VERSION ""

NS_ :

BS_:

BU_: BMS ECC EVBUS_Virtual_ECU GW OBC VCU

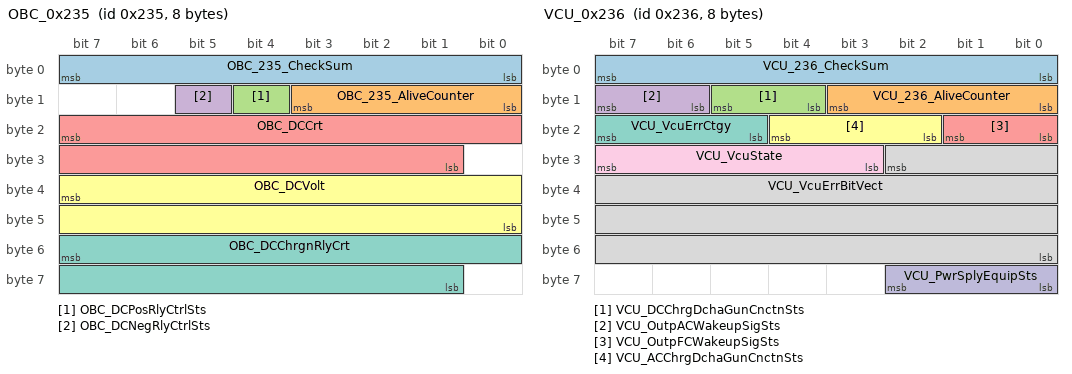
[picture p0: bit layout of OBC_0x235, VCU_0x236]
BO_ 565 OBC_0x235: 8 OBC
 SG_ OBC_235_CheckSum : 7|8@0+ (1,0) [0|255] ""  GW,VCU
 SG_ OBC_235_AliveCounter : 11|4@0+ (1,0) [0|14] ""  GW,VCU
 SG_ OBC_DCPosRlyCtrlSts : 12|1@0+ (1,0) [0|1] ""  GW,VCU
 SG_ OBC_DCNegRlyCtrlSts : 13|1@0+ (1,0) [0|1] ""  GW,VCU
 SG_ OBC_DCCrt : 23|15@0+ (0.02,-255) [-255|255] "A"  GW,VCU
 SG_ OBC_DCVolt : 39|16@0+ (0.02,0) [0|1310.7] "V"  GW,VCU
 SG_ OBC_DCChrgnRlyCrt : 55|15@0+ (0.02,-255) [-255|255] "A"  GW,VCU

BO_ 566 VCU_0x236: 8 VCU
 SG_ VCU_236_CheckSum : 7|8@0+ (1,0) [0|255] ""  GW,OBC
 SG_ VCU_236_AliveCounter : 11|4@0+ (1,0) [0|14] ""  GW,OBC
 SG_ VCU_DCChrgDchaGunCnctnSts : 13|2@0+ (1,0) [0|3] ""  GW,OBC
 SG_ VCU_OutpACWakeupSigSts : 15|2@0+ (1,0) [0|3] ""  GW
 SG_ VCU_OutpFCWakeupSigSts : 17|2@0+ (1,0) [0|3] ""  GW
 SG_ VCU_ACChrgDchaGunCnctnSts : 20|3@0+ (1,0) [0|7] ""  GW,OBC
 SG_ VCU_VcuErrCtgy : 23|3@0+ (1,0) [0|7] ""  GW
 SG_ VCU_VcuErrBitVect : 26|27@0+ (1,0) [0|134217727] ""  GW
 SG_ VCU_VcuState : 31|5@0+ (1,0) [0|31] ""  GW
 SG_ VCU_PwrSplyEquipSts : 58|3@0+ (1,0) [0|7] ""  GW

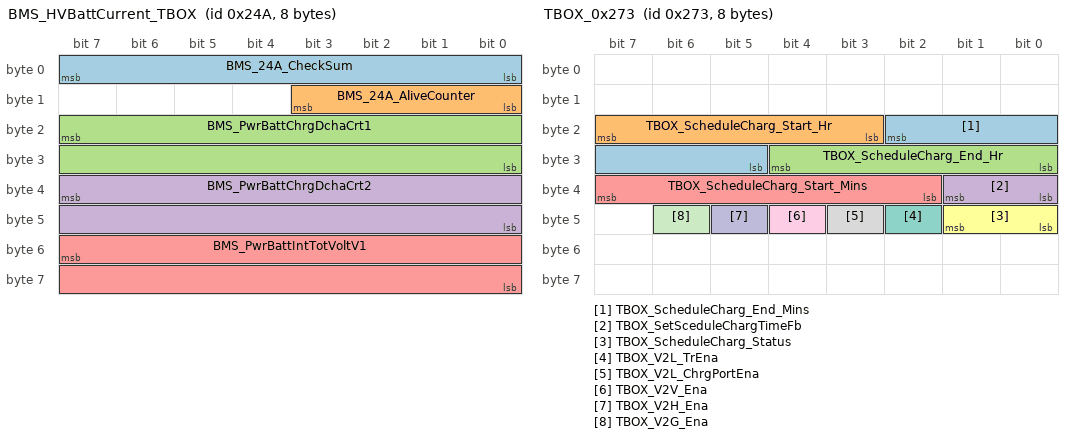
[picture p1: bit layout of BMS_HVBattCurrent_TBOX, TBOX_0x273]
BO_ 586 BMS_HVBattCurrent_TBOX: 8 BMS
 SG_ BMS_24A_CheckSum : 7|8@0+ (1,0) [0|255] ""  GW,VCU
 SG_ BMS_24A_AliveCounter : 11|4@0+ (1,0) [0|14] ""  GW,VCU
 SG_ BMS_PwrBattChrgDchaCrt1 : 23|16@0+ (0.04,-1000) [-1000|1621.4] "A"  GW,VCU
 SG_ BMS_PwrBattChrgDchaCrt2 : 39|16@0+ (0.04,-1000) [-1000|1621.4] "A"  GW,VCU
 SG_ BMS_PwrBattIntTotVoltV1 : 55|16@0+ (0.02,0) [0|1310.7] "V"  ECC,GW,VCU

BO_ 608 VCU_0x260: 16 VCU
 SG_ VCU_260_269_CheckSum : 7|8@0+ (1,0) [0|255] ""  BMS,GW,OBC
 SG_ VCU_260_269_AliveCounter : 11|4@0+ (1,0) [0|14] ""  BMS,GW,OBC
 SG_ VCU_DCVoltCmd_OBC : 23|16@0+ (0.02,0) [0|1310.7] "V"  GW,OBC
 SG_ VCU_DCCrtCmd_OBC : 39|16@0+ (0.02,0) [0|1310.7] "A"  GW,OBC
 SG_ VCU_VehChrgDchgMod : 50|3@0+ (1,0) [0|7] ""  GW,OBC
 SG_ VCU_DCRlyCtrlCmd : 51|1@0+ (1,0) [0|1] ""  GW,OBC
 SG_ VCU_ChrgSysOperCmd : 58|3@0+ (1,0) [0|7] ""  GW,OBC
 SG_ VCU_ChrgSts : 63|3@0+ (1,0) [0|7] ""  BMS,GW,OBC
 SG_ VCU_260_SSecOC_Fresh_Byte0 : 71|8@0+ (1,0) [0|255] ""  GW,OBC
 SG_ VCU_260_SSecOC_MAC_Byte0 : 79|8@0+ (1,0) [0|255] ""  GW,OBC
 SG_ VCU_260_SSecOC_MAC_Byte1 : 87|8@0+ (1,0) [0|255] ""  GW,OBC
 SG_ VCU_260_SSecOC_MAC_Byte2 : 95|8@0+ (1,0) [0|255] ""  GW,OBC

BO_ 627 TBOX_0x273: 8 GW
 SG_ TBOX_ScheduleCharg_End_Mins : 18|6@0+ (1,0) [0|59] ""  EVBUS_Virtual_ECU
 SG_ TBOX_ScheduleCharg_Start_Hr : 23|5@0+ (1,0) [0|23] ""  EVBUS_Virtual_ECU
 SG_ TBOX_ScheduleCharg_End_Hr : 28|5@0+ (1,0) [0|23] ""  EVBUS_Virtual_ECU
 SG_ TBOX_SetSceduleChargTimeFb : 33|2@0+ (1,0) [0|3] ""  EVBUS_Virtual_ECU
 SG_ TBOX_ScheduleCharg_Start_Mins : 39|6@0+ (1,0) [0|59] ""  EVBUS_Virtual_ECU
 SG_ TBOX_ScheduleCharg_Status : 41|2@0+ (1,0) [0|3] ""  VCU
 SG_ TBOX_V2L_TrEna : 42|1@0+ (1,0) [0|1] ""  VCU
 SG_ TBOX_V2L_ChrgPortEna : 43|1@0+ (1,0) [0|1] ""  VCU
 SG_ TBOX_V2V_Ena : 44|1@0+ (1,0) [0|1] ""  VCU
 SG_ TBOX_V2H_Ena : 45|1@0+ (1,0) [0|1] ""  VCU
 SG_ TBOX_V2G_Ena : 46|1@0+ (1,0) [0|1] ""  VCU

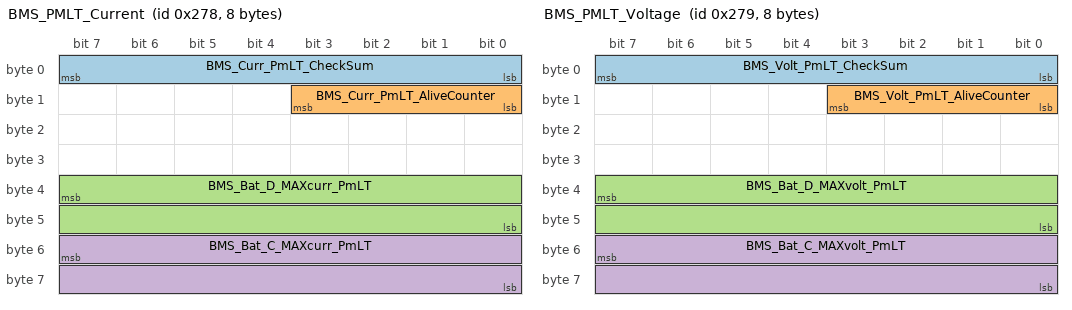
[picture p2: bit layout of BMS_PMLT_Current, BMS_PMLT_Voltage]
BO_ 632 BMS_PMLT_Current: 8 BMS
 SG_ BMS_Curr_PmLT_CheckSum : 7|8@0+ (1,0) [0|255] ""  GW,VCU
 SG_ BMS_Curr_PmLT_AliveCounter : 11|4@0+ (1,0) [0|14] ""  GW,VCU
 SG_ BMS_Bat_D_MAXcurr_PmLT : 39|16@0+ (0.05,0) [0|3276.75] "A"  GW,VCU
 SG_ BMS_Bat_C_MAXcurr_PmLT : 55|16@0+ (0.05,0) [0|3276.75] "A"  GW,VCU

BO_ 633 BMS_PMLT_Voltage: 8 BMS
 SG_ BMS_Volt_PmLT_CheckSum : 7|8@0+ (1,0) [0|255] ""  GW,VCU
 SG_ BMS_Volt_PmLT_AliveCounter : 11|4@0+ (1,0) [0|14] ""  GW,VCU
 SG_ BMS_Bat_D_MAXvolt_PmLT : 39|16@0+ (0.02,0) [0|1310.7] "V"  GW,VCU
 SG_ BMS_Bat_C_MAXvolt_PmLT : 55|16@0+ (0.02,0) [0|1310.7] "V"  GW,VCU

BO_ 649 VCU_0x289: 8 VCU
 SG_ VCU_SetSpeedLimitSts : 7|8@0+ (1,0) [0|255] ""  GW

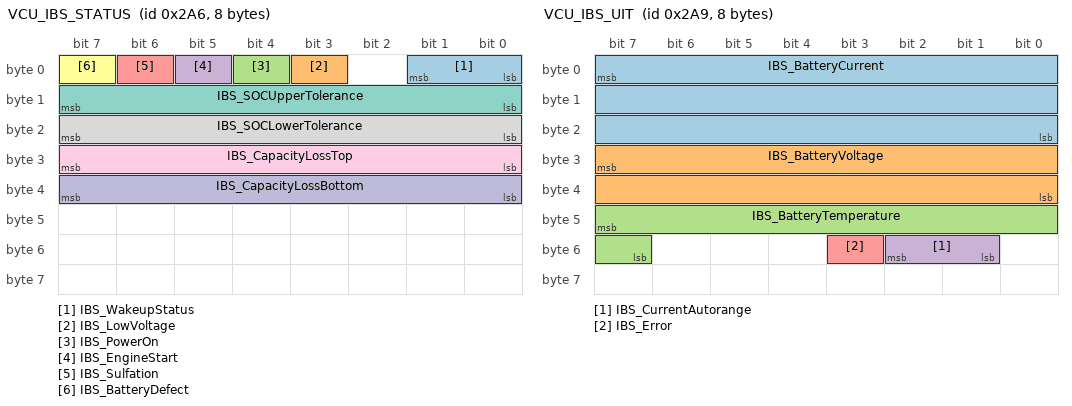
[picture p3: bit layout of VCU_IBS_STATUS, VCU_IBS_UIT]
BO_ 678 VCU_IBS_STATUS: 8 VCU
 SG_ IBS_WakeupStatus : 1|2@0+ (1,0) [0|1] ""  GW
 SG_ IBS_LowVoltage : 3|1@0+ (1,0) [0|1] ""  GW
 SG_ IBS_PowerOn : 4|1@0+ (1,0) [0|1] ""  GW
 SG_ IBS_EngineStart : 5|1@0+ (1,0) [0|1] ""  GW
 SG_ IBS_Sulfation : 6|1@0+ (1,0) [0|1] ""  GW
 SG_ IBS_BatteryDefect : 7|1@0+ (1,0) [0|1] ""  GW
 SG_ IBS_SOCUpperTolerance : 15|8@0+ (1,0) [0|254] "%"  GW
 SG_ IBS_SOCLowerTolerance : 23|8@0+ (1,0) [0|254] "%"  GW
 SG_ IBS_CapacityLossTop : 31|8@0+ (0.5,0) [0|100] "%"  GW
 SG_ IBS_CapacityLossBottom : 39|8@0+ (0.5,0) [0|100] "%"  GW

BO_ 681 VCU_IBS_UIT: 8 VCU
 SG_ IBS_BatteryCurrent : 7|24@0+ (0.001,-2000) [-2000|4000000] "A"  GW
 SG_ IBS_BatteryVoltage : 31|16@0+ (0.001,0) [0|65.535] "V"  GW
 SG_ IBS_BatteryTemperature : 47|9@0+ (0.5,-40) [-40|125] "Degree Celsius"  GW
 SG_ IBS_CurrentAutorange : 50|2@0+ (1,0) [0|3] ""  GW
 SG_ IBS_Error : 51|1@0+ (1,0) [0|1] ""  GW

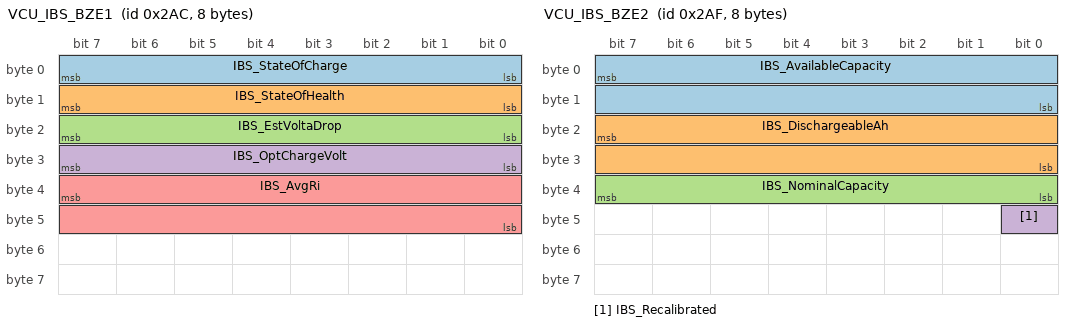
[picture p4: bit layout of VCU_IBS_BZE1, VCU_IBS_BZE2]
BO_ 684 VCU_IBS_BZE1: 8 VCU
 SG_ IBS_StateOfCharge : 7|8@0+ (0.5,0) [0|100] "%"  GW
 SG_ IBS_StateOfHealth : 15|8@0+ (0.5,0) [0|100] "%"  GW
 SG_ IBS_EstVoltaDrop : 23|8@0+ (0.05,0) [0|12.7] "V"  GW
 SG_ IBS_OptChargeVolt : 31|8@0+ (0.05,5) [5|17.75] "V"  GW
 SG_ IBS_AvgRi : 39|16@0+ (0.01,0) [0|200] "mOhm"  GW

BO_ 687 VCU_IBS_BZE2: 8 VCU
 SG_ IBS_AvailableCapacity : 7|16@0+ (0.1,0) [0|500] "Ah"  GW
 SG_ IBS_DischargeableAh : 23|16@0+ (0.1,0) [0|500] "Ah"  GW
 SG_ IBS_NominalCapacity : 39|8@0+ (2,0) [0|500] "Ah"  GW
 SG_ IBS_Recalibrated : 40|1@0+ (1,0) [0|1] ""  GW

BO_ 743 ECC_0x2E7: 8 ECC
 SG_ ECC_ICCSysSwtCmdFb : 1|2@0+ (1,0) [0|3] ""  GW
 SG_ ECC_CooltLvlWarn : 17|2@0+ (1,0) [0|3] ""  GW

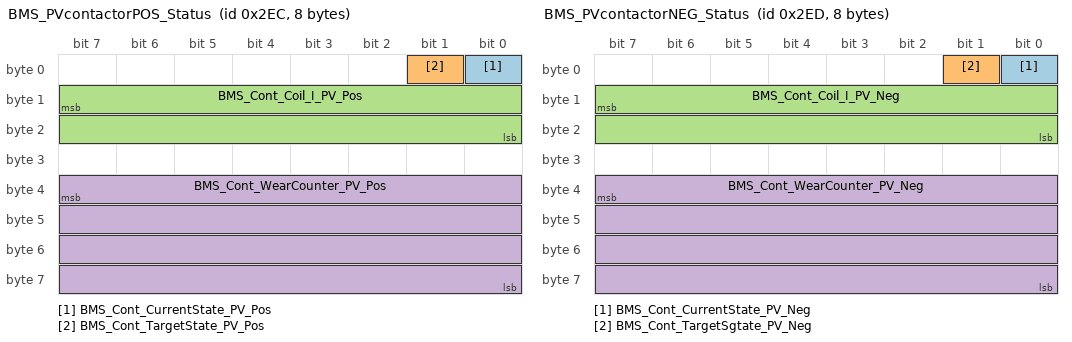
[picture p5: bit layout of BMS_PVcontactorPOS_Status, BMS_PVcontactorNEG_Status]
BO_ 748 BMS_PVcontactorPOS_Status: 8 BMS
 SG_ BMS_Cont_CurrentState_PV_Pos : 0|1@0+ (1,0) [0|1] ""  GW,VCU
 SG_ BMS_Cont_TargetState_PV_Pos : 1|1@0+ (1,0) [0|1] ""  GW
 SG_ BMS_Cont_Coil_I_PV_Pos : 15|16@0+ (0.08,0) [0|5242.8] "mA"  GW,VCU
 SG_ BMS_Cont_WearCounter_PV_Pos : 39|32@0+ (1,0) [0|4294967295] ""  GW,VCU

BO_ 749 BMS_PVcontactorNEG_Status: 8 BMS
 SG_ BMS_Cont_CurrentState_PV_Neg : 0|1@0+ (1,0) [0|1] ""  GW,VCU
 SG_ BMS_Cont_TargetSgtate_PV_Neg : 1|1@0+ (1,0) [0|1] ""  GW
 SG_ BMS_Cont_Coil_I_PV_Neg : 15|16@0+ (0.08,0) [0|5242.8] "mA"  GW,VCU
 SG_ BMS_Cont_WearCounter_PV_Neg : 39|32@0+ (1,0) [0|4294967295] ""  GW,VCU

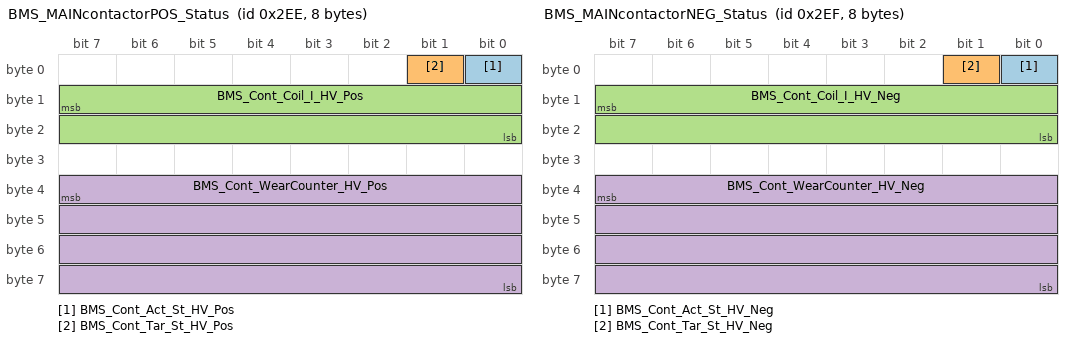
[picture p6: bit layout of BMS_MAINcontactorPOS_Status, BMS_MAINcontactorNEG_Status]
BO_ 750 BMS_MAINcontactorPOS_Status: 8 BMS
 SG_ BMS_Cont_Act_St_HV_Pos : 0|1@0+ (1,0) [0|1] ""  GW,VCU
 SG_ BMS_Cont_Tar_St_HV_Pos : 1|1@0+ (1,0) [0|1] ""  GW,VCU
 SG_ BMS_Cont_Coil_I_HV_Pos : 15|16@0+ (0.08,0) [0|5242.8] "mA"  GW,VCU
 SG_ BMS_Cont_WearCounter_HV_Pos : 39|32@0+ (1,0) [0|4294967295] ""  GW,VCU

BO_ 751 BMS_MAINcontactorNEG_Status: 8 BMS
 SG_ BMS_Cont_Act_St_HV_Neg : 0|1@0+ (1,0) [0|1] ""  GW,VCU
 SG_ BMS_Cont_Tar_St_HV_Neg : 1|1@0+ (1,0) [0|1] ""  GW,VCU
 SG_ BMS_Cont_Coil_I_HV_Neg : 15|16@0+ (0.08,0) [0|5242.8] "mA"  GW,VCU
 SG_ BMS_Cont_WearCounter_HV_Neg : 39|32@0+ (1,0) [0|4294967295] ""  GW,VCU

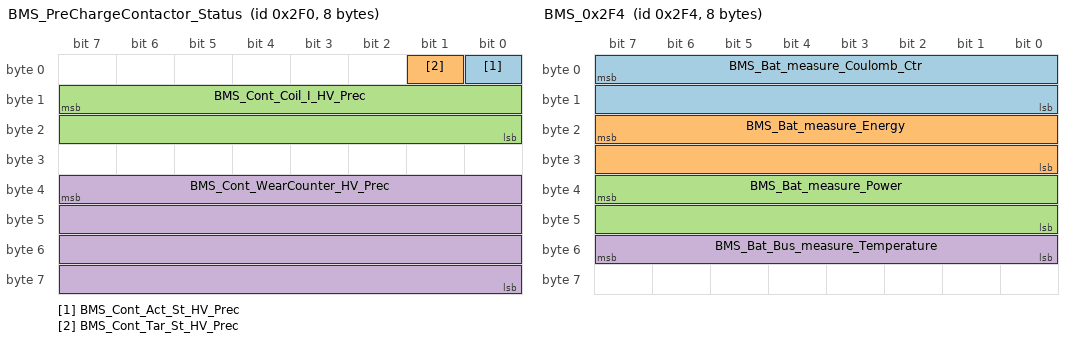
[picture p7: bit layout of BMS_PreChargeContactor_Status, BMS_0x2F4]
BO_ 752 BMS_PreChargeContactor_Status: 8 BMS
 SG_ BMS_Cont_Act_St_HV_Prec : 0|1@0+ (1,0) [0|1] ""  GW,VCU
 SG_ BMS_Cont_Tar_St_HV_Prec : 1|1@0+ (1,0) [0|1] ""  GW
 SG_ BMS_Cont_Coil_I_HV_Prec : 15|16@0+ (0.08,0) [0|5242.8] "mA"  GW,VCU
 SG_ BMS_Cont_WearCounter_HV_Prec : 39|32@0+ (1,0) [0|4294967295] ""  GW,VCU

BO_ 755 BMS_HVBatt_Status_Errors_2: 8 BMS
 SG_ BMS_Error_Flag_CheckSum : 7|8@0+ (1,0) [0|255] ""  GW,VCU
 SG_ BMS_Error_Flag_AliveCounter : 11|4@0+ (1,0) [0|14] ""  GW,VCU
 SG_ BMS_ErrorWarning_CellVoltageDiff : 12|1@0+ (1,0) [0|1] ""  GW,VCU
 SG_ BMS_ErrorActive_CellVoltageDiffO : 13|1@0+ (1,0) [0|1] ""  GW,VCU
 SG_ BMS_ErrorWarning_Diff_U1_UCellSu : 14|1@0+ (1,0) [0|1] ""  GW,VCU
 SG_ BMS_ErrorActive_Diff_U1_UCellSum : 15|1@0+ (1,0) [0|1] ""  GW,VCU
 SG_ BMS_ErrorWarning_SOH_Low : 16|1@0+ (1,0) [0|1] ""  GW,VCU
 SG_ BMS_ErrorActive_SOH_Low : 17|1@0+ (1,0) [0|1] ""  GW,VCU
 SG_ BMS_SystemError_SystemInitFailed : 18|1@0+ (1,0) [0|1] ""  GW,VCU
 SG_ BMS_SystemError_Precharge : 19|1@0+ (1,0) [0|1] ""  GW,VCU
 SG_ BMS_SystemError_HV_CCT_WrongPola : 20|1@0+ (1,0) [0|1] ""  GW,VCU
 SG_ BMS_SystemError_HV_CCT_NoBatVolt : 21|1@0+ (1,0) [0|1] ""  GW,VCU
 SG_ BMS_HVlinkWarning_VCU_MessageInt : 22|1@0+ (1,0) [0|1] ""  GW,VCU
 SG_ BMS_HVlinkError_IVT_Comm_Failure : 23|1@0+ (1,0) [0|1] ""  GW,VCU
 SG_ BMS_HVlinkWarning_IVT_Meas_Failu : 24|1@0+ (1,0) [0|1] ""  GW,VCU
 SG_ BMS_HVlinkError_IVT_Meas_Failure : 25|1@0+ (1,0) [0|1] ""  GW,VCU
 SG_ BMS_HVlinkError_NVM_Comm_Failure : 26|1@0+ (1,0) [0|1] ""  GW,VCU
 SG_ BMS_HVlinkWarning_Eeprom_LifeCyc : 27|1@0+ (1,0) [0|1] ""  GW,VCU
 SG_ BMS_HVlinkError_Eeprom_LifeCycle : 28|1@0+ (1,0) [0|1] ""  GW,VCU
 SG_ BMS_HVlinkError_ContactorGeneric : 29|1@0+ (1,0) [0|1] ""  GW,VCU
 SG_ BMS_HVlinkError_ContactorOpen : 30|1@0+ (1,0) [0|1] ""  GW,VCU
 SG_ BMS_HVlinkError_ContactorAuxFail : 31|1@0+ (1,0) [0|1] ""  GW,VCU
 SG_ BMS_HVlinkError_ContactorPwmEcon : 32|1@0+ (1,0) [0|1] ""  GW,VCU
 SG_ BMS_HVlinkWarning_AnalogInput_Ex : 33|1@0+ (1,0) [0|1] ""  GW,VCU
 SG_ BMS_HVlinkError_AnalogInput_Exce : 34|1@0+ (1,0) [0|1] ""  GW,VCU
 SG_ BMS_HWerror_KL30_Voltage : 35|1@0+ (1,0) [0|1] ""  GW,VCU
 SG_ BMS_HWerror_SD_Voltage : 36|1@0+ (1,0) [0|1] ""  GW,VCU
 SG_ BMS_HWerror_PCB_Temp_Sensor_Fail : 40|1@0+ (1,0) [0|1] ""  GW,VCU
 SG_ BMS_HWerror_Cell_Temp_Sensor_Fai : 41|1@0+ (1,0) [0|1] ""  GW,VCU
 SG_ BMS_HWwarning_LCM_PCB_OverTemp : 42|1@0+ (1,0) [0|1] ""  GW,VCU
 SG_ BMS_HWerror_LCM_PCB_OverTemp : 43|1@0+ (1,0) [0|1] ""  GW,VCU
 SG_ BMS_HWwarning_LCM_PCB_UnderTemp : 44|1@0+ (1,0) [0|1] ""  GW,VCU
 SG_ BMS_HWerror_LCM_PCB_UnderTemp : 45|1@0+ (1,0) [0|1] ""  GW,VCU
 SG_ BMS_Software_Error_Boot_Faild : 46|1@0+ (1,0) [0|1] ""  GW,VCU
 SG_ BMS_DTC_status : 55|16@0+ (1,0) [0|65535] ""  GW,VCU

BO_ 756 BMS_0x2F4: 8 BMS
 SG_ BMS_Bat_measure_Coulomb_Ctr : 7|16@0- (10,0) [-327680|327670] "As"  GW,VCU
 SG_ BMS_Bat_measure_Energy : 23|16@0- (10,0) [-327680|327670] "Wh"  GW,VCU
 SG_ BMS_Bat_measure_Power : 39|16@0- (0.1,0) [-3276.8|3276.7] "KW"  GW,VCU
 SG_ BMS_Bat_Bus_measure_Temperature : 55|8@0+ (1,-55) [-55|200] "Degree Celsius"  GW,VCU

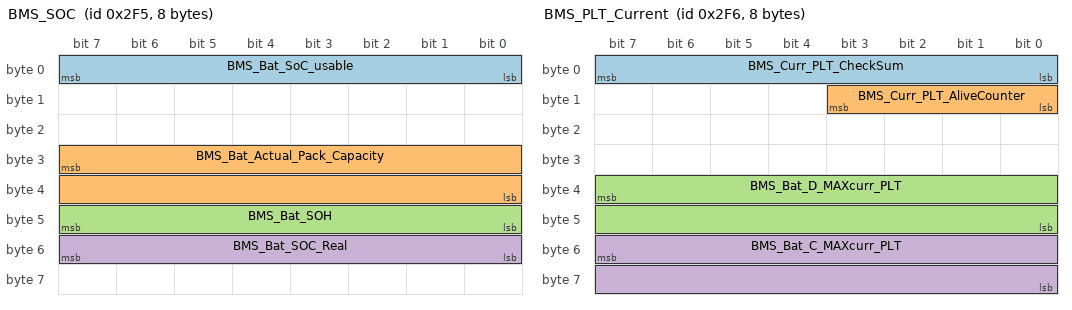
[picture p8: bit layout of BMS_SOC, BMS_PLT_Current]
BO_ 757 BMS_SOC: 8 BMS
 SG_ BMS_Bat_SoC_usable : 7|8@0+ (1,0) [0|100] "%"  GW,VCU
 SG_ BMS_Bat_Actual_Pack_Capacity : 31|16@0+ (0.01,0) [0|655.35] "kWh"  GW,VCU
 SG_ BMS_Bat_SOH : 47|8@0+ (1,0) [0|255] "%"  GW,VCU
 SG_ BMS_Bat_SOC_Real : 55|8@0+ (1,0) [0|100] "%"  GW

BO_ 758 BMS_PLT_Current: 8 BMS
 SG_ BMS_Curr_PLT_CheckSum : 7|8@0+ (1,0) [0|255] ""  GW,VCU
 SG_ BMS_Curr_PLT_AliveCounter : 11|4@0+ (1,0) [0|14] ""  GW,VCU
 SG_ BMS_Bat_D_MAXcurr_PLT : 39|16@0+ (0.05,0) [0|3276.75] "A"  GW,VCU
 SG_ BMS_Bat_C_MAXcurr_PLT : 55|16@0+ (0.05,0) [0|3276.75] "A"  GW,VCU

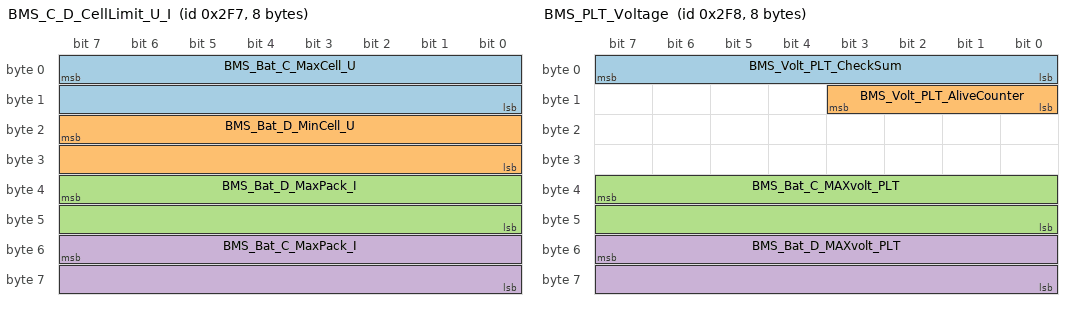
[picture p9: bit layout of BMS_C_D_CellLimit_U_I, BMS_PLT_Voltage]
BO_ 759 BMS_C_D_CellLimit_U_I: 8 BMS
 SG_ BMS_Bat_C_MaxCell_U : 7|16@0+ (0.1,0) [0|6553.5] "mV"  GW,VCU
 SG_ BMS_Bat_D_MinCell_U : 23|16@0+ (0.1,0) [0|6553.5] "mV"  ECC,GW,OBC,VCU
 SG_ BMS_Bat_D_MaxPack_I : 39|16@0+ (0.02,0) [0|1310.7] "A"  ECC,GW,OBC,VCU
 SG_ BMS_Bat_C_MaxPack_I : 55|16@0+ (0.02,0) [0|1310.7] "A"  GW,VCU

BO_ 760 BMS_PLT_Voltage: 8 BMS
 SG_ BMS_Volt_PLT_CheckSum : 7|8@0+ (1,0) [0|255] ""  GW,VCU
 SG_ BMS_Volt_PLT_AliveCounter : 11|4@0+ (1,0) [0|14] ""  GW,VCU
 SG_ BMS_Bat_C_MAXvolt_PLT : 39|16@0+ (0.02,0) [0|1310.7] "V"  GW,VCU
 SG_ BMS_Bat_D_MAXvolt_PLT : 55|16@0+ (0.02,0) [0|1310.7] "V"  GW,VCU

BO_ 761 BMS_C_D_PackLimit_U: 8 BMS
 SG_ BMS_Bat_C_MaxPack_U : 7|16@0+ (0.02,0) [0|1310.7] "V"  GW,VCU
 SG_ BMS_Bat_D_MinPack_U : 23|16@0+ (0.02,0) [0|1310.7] "V"  GW,VCU

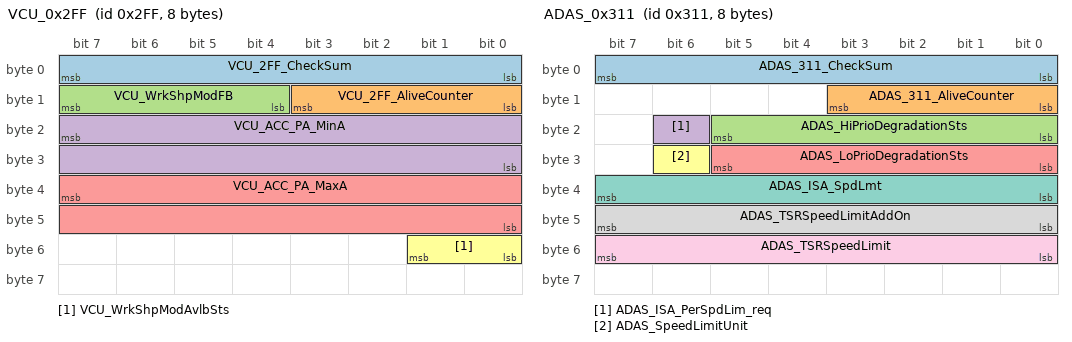
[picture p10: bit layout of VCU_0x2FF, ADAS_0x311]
BO_ 767 VCU_0x2FF: 8 VCU
 SG_ VCU_2FF_CheckSum : 7|8@0+ (1,0) [0|255] ""  GW
 SG_ VCU_2FF_AliveCounter : 11|4@0+ (1,0) [0|14] ""  GW
 SG_ VCU_WrkShpModFB : 15|4@0+ (1,0) [0|15] ""  ECC,GW
 SG_ VCU_ACC_PA_MinA : 23|16@0+ (0.0004882,-16) [-16|0] "m/sec2"  GW
 SG_ VCU_ACC_PA_MaxA : 39|16@0+ (0.0004882,0) [0|16] "m/sec2"  GW
 SG_ VCU_WrkShpModAvlbSts : 49|2@0+ (1,0) [0|3] ""  GW

BO_ 783 ICC_0x30F: 8 GW
 SG_ ICC_QuickBootMode : 0|1@0+ (1,0) [0|1] ""  VCU

BO_ 785 ADAS_0x311: 8 GW
 SG_ ADAS_311_CheckSum : 7|8@0+ (1,0) [0|255] ""  EVBUS_Virtual_ECU
 SG_ ADAS_311_AliveCounter : 11|4@0+ (1,0) [0|14] ""  EVBUS_Virtual_ECU
 SG_ ADAS_HiPrioDegradationSts : 21|6@0+ (1,0) [0|63] ""  EVBUS_Virtual_ECU
 SG_ ADAS_ISA_PerSpdLim_req : 22|1@0+ (1,0) [0|1] ""  EVBUS_Virtual_ECU
 SG_ ADAS_LoPrioDegradationSts : 29|6@0+ (1,0) [0|63] ""  EVBUS_Virtual_ECU
 SG_ ADAS_SpeedLimitUnit : 30|1@0+ (1,0) [0|1] ""  EVBUS_Virtual_ECU
 SG_ ADAS_ISA_SpdLmt : 39|8@0+ (1,0) [0|255] "kph"  VCU
 SG_ ADAS_TSRSpeedLimitAddOn : 47|8@0+ (1,0) [0|255] ""  EVBUS_Virtual_ECU
 SG_ ADAS_TSRSpeedLimit : 55|8@0+ (1,0) [0|255] ""  EVBUS_Virtual_ECU

BO_ 792 ESP_0x318: 8 GW
 SG_ ESP_318_CheckSum : 7|8@0+ (1,0) [0|255] ""  BMS,ECC,OBC
 SG_ ESP_318_AliveCounter : 11|4@0+ (1,0) [0|14] ""  BMS,ECC,OBC
 SG_ ESP_BrkPedlStsVld : 13|2@0+ (1,0) [0|3] ""  ECC
 SG_ ESP_BrkPedlSts : 14|1@0+ (1,0) [0|1] ""  ECC
 SG_ ESP_VehSpdVld : 17|2@0+ (1,0) [0|3] ""  BMS,ECC,OBC
 SG_ ESP_SysActv : 20|1@0+ (1,0) [0|1] ""  ECC
 SG_ ESP_LampSwtOffIndcn : 21|1@0+ (1,0) [0|1] ""  ECC
 SG_ ESP_FltIndcn_EBD : 22|1@0+ (1,0) [0|1] ""  ECC
 SG_ ESP_FltIndcn_ABS : 23|1@0+ (1,0) [0|1] ""  ECC
 SG_ ESP_MilgRollgCntr_ODO : 31|16@0+ (1,0) [0|65535] "pulses"  ECC
 SG_ ESP_VehSpd : 47|16@0+ (0.1,0) [0|300] "km/h"  BMS,ECC,OBC
 SG_ ESP_IninModSigIndcn : 56|1@0+ (1,0) [0|1] ""  ECC
 SG_ ESP_FltIndcn_TCS : 57|1@0+ (1,0) [0|1] ""  ECC
 SG_ ESP_CtrlSts_HDC : 59|2@0+ (1,0) [0|3] ""  ECC
 SG_ ESP_AvlIndcn_HDC : 60|1@0+ (1,0) [0|1] ""  ECC
 SG_ ESP_NoBrkP : 61|1@0+ (1,0) [0|1] ""  ECC
 SG_ ESP_RDAEnaFlg : 62|1@0+ (1,0) [0|1] ""  ECC

BO_ 799 ICC_0x31F: 8 GW
 SG_ ICC_SetSpeedLimit : 23|8@0+ (1,0) [0|255] ""  VCU

BO_ 816 BMS_HVBatt_Status_2_TBOX: 16 BMS
 SG_ BMS_330_391_CheckSum : 7|8@0+ (1,0) [0|255] ""  GW,VCU
 SG_ BMS_330_391_AliveCounter : 11|4@0+ (1,0) [0|14] ""  GW,VCU
 SG_ BMS_VehInsulFltDisp : 16|1@0+ (1,0) [0|1] ""  GW
 SG_ BMS_PwrBattSysFltDisp : 17|1@0+ (1,0) [0|1] ""  GW
 SG_ BMS_PwrBattRmngCpSOC : 31|8@0+ (0.4,0) [0|100] "%"  ECC,GW,VCU
 SG_ BMS_PwrBattAvlCp : 39|16@0+ (0.01,0) [0|655.35] "Ah"  GW,VCU
 SG_ BMS_CellMinTAlrm : 48|1@0+ (1,0) [0|1] ""  GW,VCU
 SG_ BMS_PwrBattThermRunawayAlrm : 49|1@0+ (1,0) [0|1] ""  GW,VCU
 SG_ BMS_PwrBattOverT : 53|1@0+ (1,0) [0|1] ""  GW,VCU
 SG_ BMS_PwrBattInsulSts : 55|2@0+ (1,0) [0|3] ""  GW,VCU
 SG_ BMS_330_SSecOC_Fresh_Byte0 : 71|8@0+ (1,0) [0|255] ""  GW,VCU
 SG_ BMS_330_SSecOC_MAC_Byte0 : 79|8@0+ (1,0) [0|255] ""  GW,VCU
 SG_ BMS_330_SSecOC_MAC_Byte1 : 87|8@0+ (1,0) [0|255] ""  GW,VCU
 SG_ BMS_330_SSecOC_MAC_Byte2 : 95|8@0+ (1,0) [0|255] ""  GW,VCU

BO_ 817 PKC_0x331: 16 GW
 SG_ PKC_331_CheckSum : 7|8@0+ (1,0) [0|255] ""  EVBUS_Virtual_ECU
 SG_ PKC_331_AliveCounter : 11|4@0+ (1,0) [0|14] ""  EVBUS_Virtual_ECU
 SG_ PKC_OTARdy_Fb : 13|2@0+ (1,0) [0|3] ""  EVBUS_Virtual_ECU
 SG_ PKC_OTAInhbRdy : 15|2@0+ (1,0) [0|3] ""  VCU
 SG_ PKC_RemReqCfmRxResp : 16|1@0+ (1,0) [0|1] ""  EVBUS_Virtual_ECU
 SG_ PKC_SysLrngMod : 17|1@0+ (1,0) [0|1] ""  EVBUS_Virtual_ECU
 SG_ PKC_StrtReq : 18|1@0+ (1,0) [0|1] ""  VCU
 SG_ PKC_IMMO_AuthSts : 20|2@0+ (1,0) [0|3] ""  VCU
 SG_ PKC_RemModOpenSts : 23|2@0+ (1,0) [0|3] ""  EVBUS_Virtual_ECU
 SG_ PKC_MnvrSelect : 26|3@0+ (1,0) [0|7] ""  EVBUS_Virtual_ECU
 SG_ PKC_MnvrDelete : 29|3@0+ (1,0) [0|7] ""  EVBUS_Virtual_ECU
 SG_ PKC_331_SSecOC_Fresh_Byte0 : 71|8@0+ (1,0) [0|255] ""  VCU
 SG_ PKC_331_SSecOC_MAC_Byte0 : 79|8@0+ (1,0) [0|255] ""  VCU
 SG_ PKC_331_SSecOC_MAC_Byte1 : 87|8@0+ (1,0) [0|255] ""  VCU
 SG_ PKC_331_SSecOC_MAC_Byte2 : 95|8@0+ (1,0) [0|255] ""  VCU

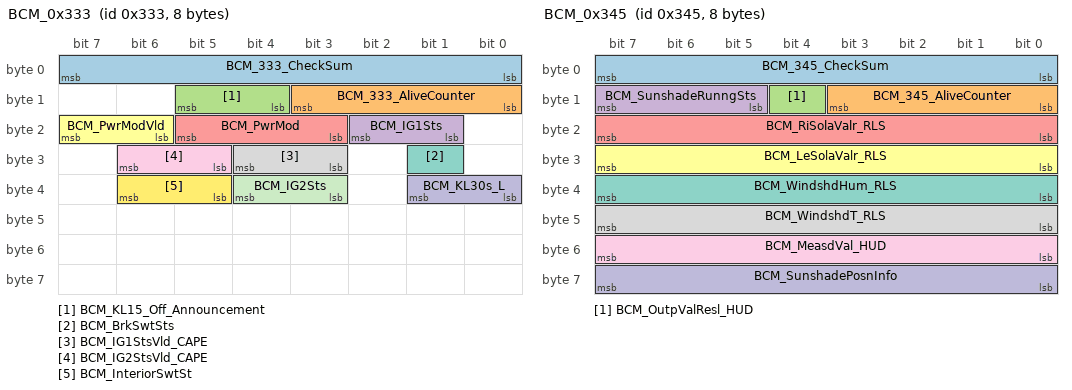
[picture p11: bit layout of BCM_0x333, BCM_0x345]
BO_ 819 BCM_0x333: 8 GW
 SG_ BCM_333_CheckSum : 7|8@0+ (1,0) [0|255] ""  BMS,ECC,OBC,VCU
 SG_ BCM_333_AliveCounter : 11|4@0+ (1,0) [0|14] ""  BMS,ECC,OBC,VCU
 SG_ BCM_KL15_Off_Announcement : 13|2@0+ (1,0) [0|3] ""  ECC
 SG_ BCM_IG1Sts : 18|2@0+ (1,0) [0|3] ""  BMS,ECC
 SG_ BCM_PwrMod : 21|3@0+ (1,0) [0|7] ""  BMS,ECC,OBC,VCU
 SG_ BCM_PwrModVld : 23|2@0+ (1,0) [0|3] ""  BMS,ECC,OBC,VCU
 SG_ BCM_BrkSwtSts : 25|1@0+ (1,0) [0|1] ""  ECC
 SG_ BCM_IG1StsVld_CAPE : 28|2@0+ (1,0) [0|3] ""  BMS,ECC
 SG_ BCM_IG2StsVld_CAPE : 30|2@0+ (1,0) [0|3] ""  ECC
 SG_ BCM_KL30s_L : 33|2@0+ (1,0) [0|3] ""  ECC
 SG_ BCM_IG2Sts : 36|2@0+ (1,0) [0|3] ""  ECC
 SG_ BCM_InteriorSwtSt : 38|2@0+ (1,0) [0|3] ""  ECC

BO_ 835 BCM_0x343: 8 GW
 SG_ BCM_343_CheckSum : 7|8@0+ (1,0) [0|255] ""  EVBUS_Virtual_ECU
 SG_ BCM_343_AliveCounter : 11|4@0+ (1,0) [0|14] ""  EVBUS_Virtual_ECU
 SG_ BCM_RemReqFb : 13|2@0+ (1,0) [0|3] ""  EVBUS_Virtual_ECU
 SG_ BCM_APASwSts : 15|2@0+ (1,0) [0|3] ""  EVBUS_Virtual_ECU
 SG_ BCM_FrntHoodLidSts : 16|1@0+ (1,0) [0|1] ""  VCU
 SG_ BCM_SunroofAntipinchSts : 17|1@0+ (1,0) [0|1] ""  EVBUS_Virtual_ECU
 SG_ BCM_FrntDrDoorLockSts : 18|1@0+ (1,0) [0|1] ""  ECC
 SG_ BCM_TrRelsSwtSts : 19|1@0+ (1,0) [0|1] ""  EVBUS_Virtual_ECU
 SG_ BCM_LockAllDoorCmd : 20|1@0+ (1,0) [0|1] ""  EVBUS_Virtual_ECU
 SG_ BCM_DrFrntDoorSts : 21|1@0+ (1,0) [0|1] ""  ECC,VCU
 SG_ BCM_PasFrntDoorSts : 22|1@0+ (1,0) [0|1] ""  ECC,VCU
 SG_ BCM_AntithftSts : 25|2@0+ (1,0) [0|3] ""  VCU
 SG_ BCM_CenLockSwtSts : 27|2@0+ (1,0) [0|3] ""  ECC
 SG_ BCM_DoorUnlockSetFb : 28|1@0+ (1,0) [0|1] ""  EVBUS_Virtual_ECU
 SG_ BCM_RiReDoorSts : 29|1@0+ (1,0) [0|1] ""  ECC,VCU
 SG_ BCM_LeReDoorSts : 30|1@0+ (1,0) [0|1] ""  ECC,VCU
 SG_ BCM_LeFrntWinSts : 31|1@0+ (1,0) [0|1] ""  EVBUS_Virtual_ECU
 SG_ BCM_RiFrntWinSts : 32|1@0+ (1,0) [0|1] ""  EVBUS_Virtual_ECU
 SG_ BCM_LeReWinSts : 33|1@0+ (1,0) [0|1] ""  EVBUS_Virtual_ECU
 SG_ BCM_RiReWinSt : 34|1@0+ (1,0) [0|1] ""  EVBUS_Virtual_ECU
 SG_ BCM_SunroofSts : 35|1@0+ (1,0) [0|1] ""  EVBUS_Virtual_ECU
 SG_ BCM_FolwMeSetStsFb : 38|3@0+ (1,0) [0|7] ""  EVBUS_Virtual_ECU
 SG_ BCM_DrvrDoorUnlckOutpCmd : 39|1@0+ (1,0) [0|1] ""  EVBUS_Virtual_ECU
 SG_ BCM_PassDoorUnlckOutpCmd : 40|1@0+ (1,0) [0|1] ""  EVBUS_Virtual_ECU
 SG_ BCM_LeDRLOutpCmd : 41|1@0+ (1,0) [0|1] ""  EVBUS_Virtual_ECU
 SG_ BCM_RiDRLOutpCmd : 42|1@0+ (1,0) [0|1] ""  EVBUS_Virtual_ECU
 SG_ BCM_ArmedClsWinSetSts : 44|1@0+ (1,0) [0|1] ""  EVBUS_Virtual_ECU
 SG_ BCM_OffAutoUnlckSetSts : 45|1@0+ (1,0) [0|1] ""  EVBUS_Virtual_ECU
 SG_ BCM_WarnVbrnSts : 46|1@0+ (1,0) [0|1] ""  EVBUS_Virtual_ECU
 SG_ BCM_SunroofPosnInfo : 55|7@0+ (1,0) [0|127] "%"  EVBUS_Virtual_ECU
 SG_ BCM_SunroofOpenAr : 56|1@0+ (1,0) [0|1] ""  EVBUS_Virtual_ECU
 SG_ BCM_SteerWhlVbrnAlrmAvl : 58|2@0+ (1,0) [0|3] ""  EVBUS_Virtual_ECU
 SG_ BCM_SunroofRunngSts : 61|3@0+ (1,0) [0|7] ""  EVBUS_Virtual_ECU
 SG_ BCM_MirrCmd : 63|2@0+ (1,0) [0|3] ""  EVBUS_Virtual_ECU

BO_ 837 BCM_0x345: 8 GW
 SG_ BCM_345_CheckSum : 7|8@0+ (1,0) [0|255] ""  ECC
 SG_ BCM_345_AliveCounter : 11|4@0+ (1,0) [0|14] ""  ECC
 SG_ BCM_OutpValResl_HUD : 12|1@0+ (1,0) [0|1] ""  EVBUS_Virtual_ECU
 SG_ BCM_SunshadeRunngSts : 15|3@0+ (1,0) [0|7] ""  EVBUS_Virtual_ECU
 SG_ BCM_RiSolaValr_RLS : 23|8@0+ (4.01575,0) [0|1024.01625] "W/m2"  ECC
 SG_ BCM_LeSolaValr_RLS : 31|8@0+ (4.01575,0) [0|1024.01625] "W/m2"  ECC
 SG_ BCM_WindshdHum_RLS : 39|8@0+ (0.5,0) [0|127.5] "%"  ECC
 SG_ BCM_WindshdT_RLS : 47|8@0+ (0.5,-40) [-40|87.5] "Degree Celsius"  ECC
 SG_ BCM_MeasdVal_HUD : 55|8@0+ (1,0) [0|255] ""  EVBUS_Virtual_ECU
 SG_ BCM_SunshadePosnInfo : 63|8@0+ (1,0) [0|100] ""  EVBUS_Virtual_ECU

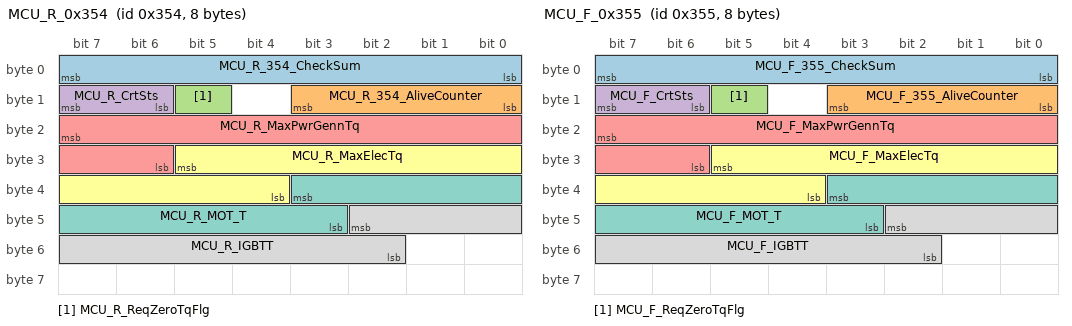
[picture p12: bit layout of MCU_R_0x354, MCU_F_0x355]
BO_ 852 MCU_R_0x354: 8 GW
 SG_ MCU_R_354_CheckSum : 7|8@0+ (1,0) [0|255] ""  ECC
 SG_ MCU_R_354_AliveCounter : 11|4@0+ (1,0) [0|14] ""  ECC
 SG_ MCU_R_ReqZeroTqFlg : 13|1@0+ (1,0) [0|1] ""  EVBUS_Virtual_ECU
 SG_ MCU_R_CrtSts : 15|2@0+ (1,0) [0|3] ""  ECC
 SG_ MCU_R_MaxPwrGennTq : 23|10@0+ (1,-511) [-511|512] "Nm"  EVBUS_Virtual_ECU
 SG_ MCU_R_MaxElecTq : 29|10@0+ (1,-511) [-511|512] "Nm"  EVBUS_Virtual_ECU
 SG_ MCU_R_MOT_T : 35|9@0+ (1,-48) [-48|400] "Degree Celsius"  ECC
 SG_ MCU_R_IGBTT : 42|9@0+ (1,-48) [-48|300] "Degree Celsius"  ECC

BO_ 853 MCU_F_0x355: 8 GW
 SG_ MCU_F_355_CheckSum : 7|8@0+ (1,0) [0|255] ""  ECC
 SG_ MCU_F_355_AliveCounter : 11|4@0+ (1,0) [0|14] ""  ECC
 SG_ MCU_F_ReqZeroTqFlg : 13|1@0+ (1,0) [0|1] ""  EVBUS_Virtual_ECU
 SG_ MCU_F_CrtSts : 15|2@0+ (1,0) [0|3] ""  ECC
 SG_ MCU_F_MaxPwrGennTq : 23|10@0+ (1,-511) [-511|512] "Nm"  EVBUS_Virtual_ECU
 SG_ MCU_F_MaxElecTq : 29|10@0+ (1,-511) [-511|512] "Nm"  EVBUS_Virtual_ECU
 SG_ MCU_F_MOT_T : 35|9@0+ (1,-48) [-48|400] "Degree Celsius"  ECC
 SG_ MCU_F_IGBTT : 42|9@0+ (1,-48) [-48|300] "Degree Celsius"  ECC

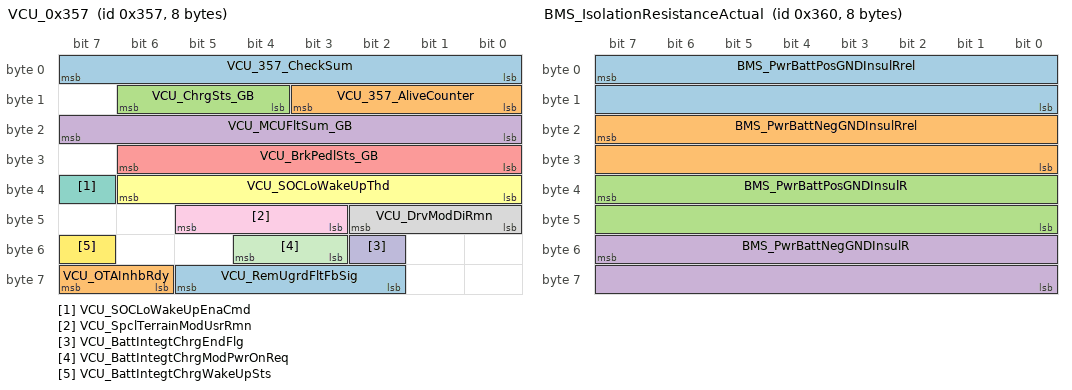
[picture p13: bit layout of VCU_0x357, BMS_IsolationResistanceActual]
BO_ 855 VCU_0x357: 8 VCU
 SG_ VCU_357_CheckSum : 7|8@0+ (1,0) [0|255] ""  GW
 SG_ VCU_357_AliveCounter : 11|4@0+ (1,0) [0|14] ""  GW
 SG_ VCU_ChrgSts_GB : 14|3@0+ (1,0) [0|7] ""  GW
 SG_ VCU_MCUFltSum_GB : 23|8@0+ (1,0) [0|255] ""  GW
 SG_ VCU_BrkPedlSts_GB : 30|7@0+ (1,0) [0|127] ""  GW
 SG_ VCU_SOCLoWakeUpThd : 38|7@0+ (1,0) [0|100] "%"  GW
 SG_ VCU_SOCLoWakeUpEnaCmd : 39|1@0+ (1,0) [0|1] ""  GW
 SG_ VCU_DrvModDiRmn : 42|3@0+ (1,0) [0|7] ""  GW
 SG_ VCU_SpclTerrainModUsrRmn : 45|3@0+ (1,0) [0|7] ""  GW
 SG_ VCU_BattIntegtChrgEndFlg : 50|1@0+ (1,0) [0|1] ""  GW
 SG_ VCU_BattIntegtChrgModPwrOnReq : 52|2@0+ (1,0) [0|3] ""  GW
 SG_ VCU_BattIntegtChrgWakeUpSts : 55|1@0+ (1,0) [0|1] ""  GW
 SG_ VCU_RemUgrdFltFbSig : 61|4@0+ (1,0) [0|15] ""  GW
 SG_ VCU_OTAInhbRdy : 63|2@0+ (1,0) [0|3] ""  GW

BO_ 856 VCU_0x358: 8 VCU
 SG_ VCU_358_CheckSum : 7|8@0+ (1,0) [0|255] ""  EVBUS_Virtual_ECU
 SG_ VCU_358_AliveCounter : 11|4@0+ (1,0) [0|14] ""  EVBUS_Virtual_ECU
 SG_ VCU_KickdwnFlg : 13|2@0+ (1,0) [0|3] ""  EVBUS_Virtual_ECU
 SG_ VCU_EPedlEnaSig : 15|1@0+ (1,0) [0|1] ""  EVBUS_Virtual_ECU
 SG_ VCU_ComLostFlt_ESP : 16|1@0+ (1,0) [0|1] ""  EVBUS_Virtual_ECU
 SG_ VCU_ComFlt_iBooster : 17|1@0+ (1,0) [0|1] ""  EVBUS_Virtual_ECU
 SG_ VCU_RegenLvlFb : 19|2@0+ (1,0) [0|3] ""  EVBUS_Virtual_ECU
 SG_ VCU_AccelModFb : 21|2@0+ (1,0) [0|3] ""  EVBUS_Virtual_ECU
 SG_ VCU_EPedlStsFb : 23|2@0+ (1,0) [0|3] ""  EVBUS_Virtual_ECU
 SG_ VCU_CcTrgSpdDisp : 31|8@0+ (1,0) [0|255] ""  EVBUS_Virtual_ECU
 SG_ VCU_Sts_CC_ICC : 35|4@0+ (1,0) [0|15] ""  EVBUS_Virtual_ECU
 SG_ VCU_CCIconDisp : 38|3@0+ (1,0) [0|7] ""  EVBUS_Virtual_ECU
 SG_ VCU_DispSpdUnit_CC : 39|1@0+ (1,0) [0|1] ""  EVBUS_Virtual_ECU
 SG_ VCU_BoostEnStat : 43|4@0+ (1,0) [0|15] ""  EVBUS_Virtual_ECU
 SG_ VCU_OTARdy_Fb : 45|2@0+ (1,0) [0|3] ""  EVBUS_Virtual_ECU
 SG_ VCU_OTA_ECUInhb_Req : 47|2@0+ (1,0) [0|3] ""  EVBUS_Virtual_ECU
 SG_ VCU_OTAVehCdnChk_ASIL : 49|2@0+ (1,0) [0|3] ""  BMS,ECC,OBC
 SG_ VCU_OTAVehInhb_ASIL_Fb : 51|2@0+ (1,0) [0|3] ""  BMS,ECC,OBC

BO_ 864 BMS_IsolationResistanceActual: 8 BMS
 SG_ BMS_PwrBattPosGNDInsulRrel : 7|16@0+ (1,0) [0|65535] "Ohm/V"  GW,VCU
 SG_ BMS_PwrBattNegGNDInsulRrel : 23|16@0+ (1,0) [0|65535] "Ohm/V"  GW,VCU
 SG_ BMS_PwrBattPosGNDInsulR : 39|16@0+ (1,0) [0|65535] "k¦¸"  GW,VCU
 SG_ BMS_PwrBattNegGNDInsulR : 55|16@0+ (1,0) [0|65535] "k¦¸"  GW,VCU

BO_ 867 VCU_0x363: 8 VCU
 SG_ VCU_ACDchaStrtFailReason : 10|3@0+ (1,0) [0|7] ""  GW
 SG_ VCU_AllwRemHeatgSts : 14|3@0+ (1,0) [0|7] ""  GW
 SG_ VCU_FbRemHeatgOperSts : 15|1@0+ (1,0) [0|1] ""  GW
 SG_ VCU_ChrgEndSOCCrtCtrlFlg : 17|2@0+ (1,0) [0|3] ""  GW
 SG_ VCU_Lvl2ProtStrtFlg : 18|1@0+ (1,0) [0|1] ""  GW
 SG_ VCU_TotOverVoltLvl2ProtFlg : 19|1@0+ (1,0) [0|1] ""  GW
 SG_ VCU_UnderVoltFltLvl2ProtFlg : 20|1@0+ (1,0) [0|1] ""  GW
 SG_ VCU_OverTFltLvl2ProtFlg : 21|1@0+ (1,0) [0|1] ""  GW
 SG_ VCU_OverVoltFltLvl2ProtFlg : 22|1@0+ (1,0) [0|1] ""  GW
 SG_ VCU_CellIntShoFltLvl2ProtFlg : 23|1@0+ (1,0) [0|1] ""  GW
 SG_ VCU_InsulFltLvl2ProtFlg : 24|1@0+ (1,0) [0|1] ""  GW
 SG_ VCU_VehCfgExchgFlg : 25|1@0+ (1,0) [0|1] ""  GW
 SG_ VCU_ReadEEFailFlg : 26|1@0+ (1,0) [0|1] ""  GW
 SG_ VCU_WrEEFailFlg : 27|1@0+ (1,0) [0|1] ""  GW
 SG_ VCU_FirstUseEEFlg : 28|1@0+ (1,0) [0|1] ""  GW
 SG_ VCU_SwUpdataFlg : 29|1@0+ (1,0) [0|1] ""  GW
 SG_ VCU_NewOldEESwtFlg : 30|1@0+ (1,0) [0|1] ""  GW
 SG_ VCU_FSCFillEndFlg : 31|1@0+ (1,0) [0|1] ""  GW
 SG_ VCU_MaxAlrmLvl : 33|2@0+ (1,0) [0|3] ""  GW
 SG_ VCU_UsrStopChrgReqSts : 35|2@0+ (1,0) [0|3] ""  GW
 SG_ VCU_DchaIndcrLampCtrlCmd : 36|1@0+ (1,0) [0|1] ""  GW
 SG_ VCU_VehExtDchaSts : 39|3@0+ (1,0) [0|7] ""  GW
 SG_ VCU_S1SwtCmd : 41|2@0+ (1,0) [0|3] ""  GW
 SG_ VCU_DchaFltStsIndcn : 42|1@0+ (1,0) [0|1] ""  GW
 SG_ VCU_DchaUsrSetThd : 43|1@0+ (1,0) [0|1] ""  GW
 SG_ VCU_RemHeatgDmd : 45|2@0+ (1,0) [0|3] ""  GW
 SG_ VCU_PwrBattHeatgTyp : 47|2@0+ (1,0) [0|3] ""  ECC,GW
 SG_ VCU_RemPwrBattPreheatgDmdTi : 55|8@0+ (1,0) [0|255] "min"  GW
 SG_ VCU_ChrgInsulFctOpenSts : 56|1@0+ (1,0) [0|1] ""  GW
 SG_ VCU_ChrgEquipPwrNotEngh : 59|2@0+ (1,0) [0|3] ""  GW
 SG_ VCU_ACChrgStrtFailReason : 62|3@0+ (1,0) [0|7] ""  GW

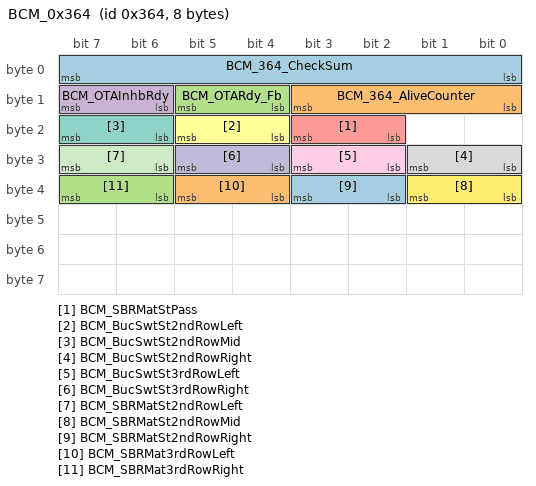
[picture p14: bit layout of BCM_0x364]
BO_ 868 BCM_0x364: 8 GW
 SG_ BCM_364_CheckSum : 7|8@0+ (1,0) [0|255] ""  ECC
 SG_ BCM_364_AliveCounter : 11|4@0+ (1,0) [0|14] ""  ECC
 SG_ BCM_OTARdy_Fb : 13|2@0+ (1,0) [0|3] ""  EVBUS_Virtual_ECU
 SG_ BCM_OTAInhbRdy : 15|2@0+ (1,0) [0|3] ""  VCU
 SG_ BCM_SBRMatStPass : 19|2@0+ (1,0) [0|3] ""  ECC
 SG_ BCM_BucSwtSt2ndRowLeft : 21|2@0+ (1,0) [0|3] ""  ECC
 SG_ BCM_BucSwtSt2ndRowMid : 23|2@0+ (1,0) [0|3] ""  ECC
 SG_ BCM_BucSwtSt2ndRowRight : 25|2@0+ (1,0) [0|3] ""  ECC
 SG_ BCM_BucSwtSt3rdRowLeft : 27|2@0+ (1,0) [0|3] ""  ECC
 SG_ BCM_BucSwtSt3rdRowRight : 29|2@0+ (1,0) [0|3] ""  ECC
 SG_ BCM_SBRMatSt2ndRowLeft : 31|2@0+ (1,0) [0|3] ""  ECC
 SG_ BCM_SBRMatSt2ndRowMid : 33|2@0+ (1,0) [0|3] ""  ECC
 SG_ BCM_SBRMatSt2ndRowRight : 35|2@0+ (1,0) [0|3] ""  ECC
 SG_ BCM_SBRMat3rdRowLeft : 37|2@0+ (1,0) [0|3] ""  ECC
 SG_ BCM_SBRMat3rdRowRight : 39|2@0+ (1,0) [0|3] ""  ECC

BO_ 869 MCU_F_0x365: 8 GW
 SG_ MCU_F_SecuStsChkFlt : 1|1@0+ (1,0) [0|1] ""  EVBUS_Virtual_ECU
 SG_ MCU_F_HVActvDchaFlt : 2|1@0+ (1,0) [0|1] ""  EVBUS_Virtual_ECU
 SG_ MCU_F_CtrlPanTChkCircFlt : 6|1@0+ (1,0) [0|1] ""  EVBUS_Virtual_ECU
 SG_ MCU_F_ComLostFlt_VCU : 7|1@0+ (1,0) [0|1] ""  EVBUS_Virtual_ECU
 SG_ MCU_F_E2EFlt : 8|1@0+ (1,0) [0|1] ""  EVBUS_Virtual_ECU
 SG_ MCU_F_I2TFlt : 9|1@0+ (1,0) [0|1] ""  EVBUS_Virtual_ECU
 SG_ MCU_F_OperModFlt : 10|1@0+ (1,0) [0|1] ""  EVBUS_Virtual_ECU
 SG_ MCU_F_CooltOverTFlt : 11|1@0+ (1,0) [0|1] ""  EVBUS_Virtual_ECU
 SG_ MCU_F_PhaCrtSampleCircFltU : 17|1@0+ (1,0) [0|1] ""  EVBUS_Virtual_ECU
 SG_ MCU_F_PhaCrtSampleCircFltV : 19|1@0+ (1,0) [0|1] ""  EVBUS_Virtual_ECU
 SG_ MCU_F_PhaCrtSampleCircFltW : 20|1@0+ (1,0) [0|1] ""  EVBUS_Virtual_ECU
 SG_ MCU_F_ThreePhaCrtChkFlt : 21|1@0+ (1,0) [0|1] ""  EVBUS_Virtual_ECU
 SG_ MCU_F_DCBusUnderVoltFlt : 22|1@0+ (1,0) [0|1] ""  EVBUS_Virtual_ECU
 SG_ MCU_F_DCBusOverVoltFlt : 23|1@0+ (1,0) [0|1] ""  EVBUS_Virtual_ECU
 SG_ MCU_F_PosnSnsrChkCircFlt : 25|1@0+ (1,0) [0|1] ""  EVBUS_Virtual_ECU
 SG_ MCU_F_DCBusVoltSampleCircFlt : 26|1@0+ (1,0) [0|1] ""  EVBUS_Virtual_ECU
 SG_ MCU_F_OverSpdFlt : 27|1@0+ (1,0) [0|1] ""  EVBUS_Virtual_ECU
 SG_ MCU_F_IGBTOverTFltU : 28|1@0+ (1,0) [0|1] ""  ECC
 SG_ MCU_F_IGBTTChkCircFltU : 29|1@0+ (1,0) [0|1] ""  ECC
 SG_ MCU_F_IGBTTChkCircFltV : 32|1@0+ (1,0) [0|1] ""  ECC
 SG_ MCU_F_IGBTTChkCircFltW : 33|1@0+ (1,0) [0|1] ""  ECC
 SG_ MCU_F_OverTFlt : 34|1@0+ (1,0) [0|1] ""  ECC
 SG_ MCU_F_TChkCircFlt : 35|1@0+ (1,0) [0|1] ""  ECC
 SG_ MCU_F_CtrlPanOverTFlt : 36|1@0+ (1,0) [0|1] ""  ECC
 SG_ MCU_F_LVPwrSplyUnderVoltFlt : 38|1@0+ (1,0) [0|1] ""  EVBUS_Virtual_ECU
 SG_ MCU_F_LVPwrSplyOverVoltFlt : 39|1@0+ (1,0) [0|1] ""  EVBUS_Virtual_ECU
 SG_ MCU_F_FbTqStsChkFlt : 40|1@0+ (1,0) [0|1] ""  EVBUS_Virtual_ECU
 SG_ MCU_F_PhaCrtSwOverCrtFltU : 42|1@0+ (1,0) [0|1] ""  EVBUS_Virtual_ECU
 SG_ MCU_F_TqCmdOverLimFlt : 43|1@0+ (1,0) [0|1] ""  ECC
 SG_ MCU_F_PwrSplyModFlt : 44|1@0+ (1,0) [0|1] ""  EVBUS_Virtual_ECU
 SG_ MCU_F_IGBTThreePhaTChkFlt : 45|1@0+ (1,0) [0|1] ""  EVBUS_Virtual_ECU
 SG_ MCU_F_RotCalFlt : 46|1@0+ (1,0) [0|1] ""  EVBUS_Virtual_ECU
 SG_ MCU_F_IntComFlt : 47|1@0+ (1,0) [0|1] ""  EVBUS_Virtual_ECU
 SG_ MCU_F_IntTqChkFlt : 48|1@0+ (1,0) [0|1] ""  EVBUS_Virtual_ECU
 SG_ MCU_F_IGBTDesatFltTop : 49|1@0+ (1,0) [0|1] ""  EVBUS_Virtual_ECU
 SG_ MCU_F_IGBTDesatFltBot : 50|1@0+ (1,0) [0|1] ""  EVBUS_Virtual_ECU
 SG_ MCU_F_PhaCrtSwOverCrtFltV : 52|1@0+ (1,0) [0|1] ""  EVBUS_Virtual_ECU
 SG_ MCU_F_PhaCrtSwOverCrtFltW : 53|1@0+ (1,0) [0|1] ""  EVBUS_Virtual_ECU
 SG_ MCU_F_IGBTOverTFltV : 54|1@0+ (1,0) [0|1] ""  EVBUS_Virtual_ECU
 SG_ MCU_F_IGBTOverTFltW : 55|1@0+ (1,0) [0|1] ""  EVBUS_Virtual_ECU

CM_ SG_ 565 OBC_235_CheckSum "OBC_235_Message checksum(0x55)OBC_235_CheckSum";
CM_ SG_ 565 OBC_235_AliveCounter "OBC_235_Message counterOBC235AliveCounter";
CM_ SG_ 565 OBC_DCPosRlyCtrlSts "DC Pos charging relay control state";
CM_ SG_ 565 OBC_DCNegRlyCtrlSts "DC Neg charging relay control state";
CM_ SG_ 565 OBC_DCCrt "DC terminal current of charger";
CM_ SG_ 565 OBC_DCVolt "DC terminal voltage of charger";
CM_ SG_ 565 OBC_DCChrgnRlyCrt "HV DC charging contactor current";
CM_ SG_ 566 VCU_236_CheckSum "VCU_236_Message checksum (E2E data ID: 0x94)";
CM_ SG_ 566 VCU_236_AliveCounter "VCU_236_Message counterVCU_236_AliveCounter";
CM_ SG_ 566 VCU_DCChrgDchaGunCnctnSts "DC Connection state of charge/discharge gun";
CM_ SG_ 566 VCU_OutpACWakeupSigSts "VCU output AC charge and discharge wake-up signal state";
CM_ SG_ 566 VCU_OutpFCWakeupSigSts "VCU output fast charge wake-up signal state";
CM_ SG_ 566 VCU_ACChrgDchaGunCnctnSts "AC Connection state of charge/discharge gun";
CM_ SG_ 566 VCU_VcuErrCtgy "VCU Error Category";
CM_ SG_ 566 VCU_VcuErrBitVect "VCU error bit signal";
CM_ SG_ 566 VCU_VcuState "VCU state signal";
CM_ SG_ 566 VCU_PwrSplyEquipSts "State of power supply equipment";
CM_ SG_ 586 BMS_24A_CheckSum "BMS_24A_message checksum (E2E data ID: 0xA8)";
CM_ SG_ 586 BMS_24A_AliveCounter "BMS_24A message counterBMS_24A_AliveCounter";
CM_ SG_ 586 BMS_PwrBattChrgDchaCrt1 "Traction battery charge and discharge current (functional safety channel 1)";
CM_ SG_ 586 BMS_PwrBattChrgDchaCrt2 "Traction battery charge and discharge current (functional safety channel 2)";
CM_ SG_ 586 BMS_PwrBattIntTotVoltV1 "Total internal voltage V1 of traction battery";
CM_ SG_ 608 VCU_260_269_CheckSum "VCU_260_269_CheckSum (E2E data ID: 0x5D) ";
CM_ SG_ 608 VCU_260_269_AliveCounter "VCU_260_269_AliveCounter";
CM_ SG_ 608 VCU_DCVoltCmd_OBC "DC terminal voltage command of on-board charger";
CM_ SG_ 608 VCU_DCCrtCmd_OBC "On-board charger DC terminal current command";
CM_ SG_ 608 VCU_VehChrgDchgMod "Vehicle charge and discharge mode";
CM_ SG_ 608 VCU_DCRlyCtrlCmd "DC charging relay control command";
CM_ SG_ 608 VCU_ChrgSysOperCmd "Operating instructions of charging system";
CM_ SG_ 608 VCU_ChrgSts "VCU charging status";
CM_ SG_ 608 VCU_260_SSecOC_Fresh_Byte0 "Short SecOC Fresh signal byte 0 on CAN";
CM_ SG_ 608 VCU_260_SSecOC_MAC_Byte0 "Short SecOC MAC signal byte 0 on CAN";
CM_ SG_ 608 VCU_260_SSecOC_MAC_Byte1 "Short SecOC MAC signal byte 1 on CAN";
CM_ SG_ 608 VCU_260_SSecOC_MAC_Byte2 "Short SecOC MAC signal byte 2 on CAN";
CM_ SG_ 627 TBOX_V2L_TrEna "TBOX_V2LTrunkEnable";
CM_ SG_ 627 TBOX_V2L_ChrgPortEna "TBOX_V2LChargePortEnable";
CM_ SG_ 627 TBOX_V2V_Ena "TBOX_V2VEnable";
CM_ SG_ 627 TBOX_V2H_Ena "TBOX_V2HEnable";
CM_ SG_ 627 TBOX_V2G_Ena "TBOX_V2GEnable";
CM_ SG_ 632 BMS_Curr_PmLT_CheckSum "CheckSum(E2E data ID: 0x52)";
CM_ SG_ 632 BMS_Curr_PmLT_AliveCounter "Rolling counter";
CM_ SG_ 632 BMS_Bat_D_MAXcurr_PmLT "predicted discharge current for middle long time [30s value]";
CM_ SG_ 632 BMS_Bat_C_MAXcurr_PmLT "  predicted charge current for middle long time [30s value]   When vehicle driving, this signal is used as a recharging (recuperation) current limit";
CM_ SG_ 633 BMS_Volt_PmLT_CheckSum "CheckSum(E2E data ID: 0x53)";
CM_ SG_ 633 BMS_Volt_PmLT_AliveCounter "Rolling counter";
CM_ SG_ 633 BMS_Bat_D_MAXvolt_PmLT "predicted discharge REESS voltage for middle long time [30s value]";
CM_ SG_ 633 BMS_Bat_C_MAXvolt_PmLT "predicted charge REESS voltage for middle long time [30s value]";
CM_ SG_ 678 IBS_WakeupStatus "Information if IBS has woken-up the master or not";
CM_ SG_ 678 IBS_LowVoltage "Voltage lower then defined level (not implemented)";
CM_ SG_ 678 IBS_PowerOn "IBS Power On in last 2 sec";
CM_ SG_ 678 IBS_EngineStart "Engine cranking seen";
CM_ SG_ 678 IBS_Sulfation "Battery sulfation flag";
CM_ SG_ 678 IBS_BatteryDefect "Battery defect flag";
CM_ SG_ 678 IBS_SOCUpperTolerance "State of Charge Upper Tolerance";
CM_ SG_ 678 IBS_SOCLowerTolerance "State of Charge Lower Tolerance";
CM_ SG_ 678 IBS_CapacityLossTop "Upper capacity loss (reversible)";
CM_ SG_ 678 IBS_CapacityLossBottom "Lower capacity loss";
CM_ SG_ 681 IBS_BatteryCurrent "Battery current (charge = positive)";
CM_ SG_ 681 IBS_BatteryVoltage "Battery voltage";
CM_ SG_ 681 IBS_BatteryTemperature "Battery temperature (acid temperature)";
CM_ SG_ 681 IBS_CurrentAutorange "Current measurement range (gain setting)";
CM_ SG_ 684 IBS_StateOfCharge "State of Charge";
CM_ SG_ 684 IBS_StateOfHealth "State of Health, age of battery";
CM_ SG_ 684 IBS_EstVoltaDrop "State of Function, predicted battery voltage for next crank";
CM_ SG_ 684 IBS_OptChargeVolt "Recommended charge voltage for battery";
CM_ SG_ 684 IBS_AvgRi "Average of internal resistance";
CM_ SG_ 687 IBS_AvailableCapacity "Available capacity if battery would be fully charged";
CM_ SG_ 687 IBS_DischargeableAh "Dischargeable capacity";
CM_ SG_ 687 IBS_NominalCapacity "Adjusted nominal capacity";
CM_ SG_ 687 IBS_Recalibrated "SOC valid flag";
CM_ SG_ 743 ECC_CooltLvlWarn "Coolant level Warning to HMI ";
CM_ SG_ 748 BMS_Cont_CurrentState_PV_Pos "Current State of the relay see Enum ContactorStatus";
CM_ SG_ 748 BMS_Cont_TargetState_PV_Pos "Desired state of the ralay  ";
CM_ SG_ 748 BMS_Cont_Coil_I_PV_Pos "Current flowing through the coil";
CM_ SG_ 748 BMS_Cont_WearCounter_PV_Pos "Switch counter";
CM_ SG_ 749 BMS_Cont_CurrentState_PV_Neg "Current State of the relay see Enum ContactorStatus";
CM_ SG_ 749 BMS_Cont_TargetSgtate_PV_Neg "Desired state of the ralay  ";
CM_ SG_ 749 BMS_Cont_Coil_I_PV_Neg "Current flowing through the coil";
CM_ SG_ 749 BMS_Cont_WearCounter_PV_Neg "Switch counter";
CM_ SG_ 750 BMS_Cont_Act_St_HV_Pos "Current State of the relay see Enum ContactorStatus";
CM_ SG_ 750 BMS_Cont_Tar_St_HV_Pos "Desired state of the ralay  ";
CM_ SG_ 750 BMS_Cont_Coil_I_HV_Pos "Current flowing through the coil";
CM_ SG_ 750 BMS_Cont_WearCounter_HV_Pos "Switch counter";
CM_ SG_ 751 BMS_Cont_Act_St_HV_Neg "Current State of the relay see Enum ContactorStatus";
CM_ SG_ 751 BMS_Cont_Tar_St_HV_Neg "Desired state of the ralay  ";
CM_ SG_ 751 BMS_Cont_Coil_I_HV_Neg "Current flowing through the coil";
CM_ SG_ 751 BMS_Cont_WearCounter_HV_Neg "Switch counter";
CM_ SG_ 752 BMS_Cont_Act_St_HV_Prec "Current State of the relay see Enum ContactorStatus";
CM_ SG_ 752 BMS_Cont_Tar_St_HV_Prec "Desired state of the ralay  ";
CM_ SG_ 752 BMS_Cont_Coil_I_HV_Prec "Current flowing through the coil";
CM_ SG_ 752 BMS_Cont_WearCounter_HV_Prec "Switch counter";
CM_ SG_ 755 BMS_Error_Flag_CheckSum "CheckSum(E2E data ID: 0xF3)";
CM_ SG_ 755 BMS_Error_Flag_AliveCounter "Rolling counter";
CM_ SG_ 755 BMS_ErrorWarning_CellVoltageDiff "Cell voltages are not homogenious and allowed maximum cell voltage difference is almost reached";
CM_ SG_ 755 BMS_ErrorActive_CellVoltageDiffO "Cell voltages are not homogenious and allowed maximum cell voltage difference is  reached";
CM_ SG_ 755 BMS_ErrorWarning_Diff_U1_UCellSu "Sum of all cell voltages differs from the measured voltage of IVT (U1)";
CM_ SG_ 755 BMS_ErrorActive_Diff_U1_UCellSum "Sum of all cell voltages differs from the measured voltage of IVT (U1)";
CM_ SG_ 755 BMS_ErrorWarning_SOH_Low "The currently measured SOH value has reached the warning threshold: SOH system limit ";
CM_ SG_ 755 BMS_ErrorActive_SOH_Low "Current measured SOH value is below of the minimum allowed system limit";
CM_ SG_ 755 BMS_SystemError_SystemInitFailed "There is any err while the initialization is done.";
CM_ SG_ 755 BMS_SystemError_Precharge "Precharge sequence failed because voltage after contactors is not equal to U1 +/-2V for 250ms after time";
CM_ SG_ 755 BMS_SystemError_HV_CCT_WrongPola "The battery volatge and current signes are wrong";
CM_ SG_ 755 BMS_SystemError_HV_CCT_NoBatVolt "No battery volatge measured during initialisation";
CM_ SG_ 755 BMS_HVlinkWarning_VCU_MessageInt "The content of the received VCU_BMS_Control message is not valid or undefined";
CM_ SG_ 755 BMS_HVlinkError_IVT_Comm_Failure "Messages of the IVT Sensor are lost or specific measurement channels (e.g current channel) aren't received in the defined cycle time.";
CM_ SG_ 755 BMS_HVlinkWarning_IVT_Meas_Failu "The sensor signals with specific err bits that the last received measurement results are faulty. This err will be reported when the warning threshold value has been reached";
CM_ SG_ 755 BMS_HVlinkError_IVT_Meas_Failure "IVT sensor no longer sends plausible values . This err is reported when the number of measurement errs exceeds the critical threshold. ";
CM_ SG_ 755 BMS_HVlinkError_NVM_Comm_Failure "The number of faulty write and read accesses to eeprom memory has reached the maximum allowed limit";
CM_ SG_ 755 BMS_HVlinkWarning_Eeprom_LifeCyc "The Eeeprom memory has almost reached the maximum number of write cycles.";
CM_ SG_ 755 BMS_HVlinkError_Eeprom_LifeCycle "The Eeeprom memory has reached the maximum number of write cycles.No further writing on Eeprom is Possible.";
CM_ SG_ 755 BMS_HVlinkError_ContactorGeneric "the life time of the contactor (number of close-open sequencies) has been reached  or number of disconnects under high currrent has exceeded the allowed limit for this contactor type";
CM_ SG_ 755 BMS_HVlinkError_ContactorOpen "-A- HV contactor is defective and no longer closes";
CM_ SG_ 755 BMS_HVlinkError_ContactorAuxFail "Auxilary feedback line of the contactor is defective";
CM_ SG_ 755 BMS_HVlinkError_ContactorPwmEcon "The chosen pwm value does not keep the contacts together.This err only applies to pwm operated contactors.";
CM_ SG_ 755 BMS_HVlinkWarning_AnalogInput_Ex "One of the analog inputs crossed its limit operational limit";
CM_ SG_ 755 BMS_HVlinkError_AnalogInput_Exce "One of the analog inputs crossed its limit safety limit";
CM_ SG_ 755 BMS_HWerror_KL30_Voltage "Voltage at KL30 + reminal is outside defined operational range";
CM_ SG_ 755 BMS_HWerror_SD_Voltage "Service disconnect loop voltage is outside of defined operational range";
CM_ SG_ 755 BMS_HWerror_PCB_Temp_Sensor_Fail "One or more pcb  temperature sensors at LMM module are faulty";
CM_ SG_ 755 BMS_HWerror_Cell_Temp_Sensor_Fai "One or more cell  temperature sensors  are faulty";
CM_ SG_ 755 BMS_HWwarning_LCM_PCB_OverTemp "Temperature sensor on the LCM has reached its overheating warning threshold.";
CM_ SG_ 755 BMS_HWerror_LCM_PCB_OverTemp "Temperature sensor on the LCM has reached its overheating  limit";
CM_ SG_ 755 BMS_HWwarning_LCM_PCB_UnderTemp "Temperature sensor on the LCM has reached its undercooling warning threshold.";
CM_ SG_ 755 BMS_HWerror_LCM_PCB_UnderTemp "Temperature sensor on the LCM has reached its undercooling limit";
CM_ SG_ 755 BMS_Software_Error_Boot_Faild "Boot process failed";
CM_ SG_ 755 BMS_DTC_status "BMS DTC status";
CM_ SG_ 756 BMS_Bat_measure_Coulomb_Ctr "measured values [As]";
CM_ SG_ 756 BMS_Bat_measure_Energy "measured values IVT [Wh]";
CM_ SG_ 756 BMS_Bat_measure_Power "measured values IVT [KW]";
CM_ SG_ 756 BMS_Bat_Bus_measure_Temperature "measured valuesIVT";
CM_ SG_ 757 BMS_Bat_SoC_usable "Usable SoC value output [%]";
CM_ SG_ 757 BMS_Bat_Actual_Pack_Capacity "Actual system capacity [kWh]";
CM_ SG_ 757 BMS_Bat_SOH "Actual aging [%]";
CM_ SG_ 757 BMS_Bat_SOC_Real "Real SOC of HV battery (%) ";
CM_ SG_ 758 BMS_Curr_PLT_CheckSum "CheckSum(E2E data ID: 0x82)";
CM_ SG_ 758 BMS_Curr_PLT_AliveCounter "Rolling counter";
CM_ SG_ 758 BMS_Bat_D_MAXcurr_PLT "predicted discharge current for long time [300s value]";
CM_ SG_ 758 BMS_Bat_C_MAXcurr_PLT "predicted charge current for long time [300s value]";
CM_ SG_ 759 BMS_Bat_C_MaxCell_U "maximum cell voltage which is allowed in charge direction ";
CM_ SG_ 759 BMS_Bat_D_MinCell_U "minimum cell voltage level, which is allowed in discharge";
CM_ SG_ 759 BMS_Bat_D_MaxPack_I " maximum allowed current in discharge direction (depends on temperature)";
CM_ SG_ 759 BMS_Bat_C_MaxPack_I "maximum allowed current in charge direction (depends on temperature) When vehicle driving, this signal is used as a recharging (recuperation) current limit";
CM_ SG_ 760 BMS_Volt_PLT_CheckSum "CheckSum(E2E data ID: 0x89)";
CM_ SG_ 760 BMS_Volt_PLT_AliveCounter "Rolling counter";
CM_ SG_ 760 BMS_Bat_C_MAXvolt_PLT "predicted charge REESS voltage for long time [300s value]";
CM_ SG_ 760 BMS_Bat_D_MAXvolt_PLT "predicted discharge REESS voltage for long time [300s value]";
CM_ SG_ 761 BMS_Bat_C_MaxPack_U "maximum system voltage which is allowed in charge direction.";
CM_ SG_ 761 BMS_Bat_D_MinPack_U "minimum system voltage level, which is allowed in discharge direction";
CM_ SG_ 767 VCU_2FF_CheckSum "VCU_2FF_Message checksum (0xE7)VCU_2FF_CheckSum";
CM_ SG_ 767 VCU_2FF_AliveCounter "VCU_0x139_AliveCounter";
CM_ SG_ 767 VCU_WrkShpModFB "Workshop Mode Feedback from VCU";
CM_ SG_ 767 VCU_ACC_PA_MinA "VCU minimum acceleration for ACC and parking functions";
CM_ SG_ 767 VCU_ACC_PA_MaxA "VCU maximum acceleration for ACC and parking functions";
CM_ SG_ 767 VCU_WrkShpModAvlbSts "Workshop Mode Availability Status from VCU";
CM_ SG_ 783 ICC_QuickBootMode "ICC to send VCU to enable quick boot mode where ICC does not power down, but just turns the screen blank.";
CM_ SG_ 785 ADAS_311_CheckSum "ADAS_0x311_message checksum (E2E data ID: 0x4F)";
CM_ SG_ 785 ADAS_311_AliveCounter "ADAS_311_Message counter";
CM_ SG_ 785 ADAS_HiPrioDegradationSts "ADAS high priority feature degradation status, used to popup a window on central display when the feature reaches the safe state";
CM_ SG_ 785 ADAS_ISA_PerSpdLim_req "Signal to notify the driver for the speed limit change between SLIF percieved speed limit and Speedometer speed.";
CM_ SG_ 785 ADAS_LoPrioDegradationSts "ADAS low priority feature degradation status, used to popup a window on central display when the feature reaches the safe state";
CM_ SG_ 785 ADAS_SpeedLimitUnit "Change speed Unit (kmh /Mph)";
CM_ SG_ 785 ADAS_ISA_SpdLmt "ISA detected speed limit + user selected offset";
CM_ SG_ 785 ADAS_TSRSpeedLimitAddOn "TSR speed limit add on";
CM_ SG_ 785 ADAS_TSRSpeedLimit "TSR speed limit";
CM_ SG_ 792 ESP_318_CheckSum "ESP318_Message Checksum ( E2E data ID: 0x79)";
CM_ SG_ 792 ESP_318_AliveCounter "ESP 3318_Message counterESP_318_AliveCounter";
CM_ SG_ 792 ESP_BrkPedlStsVld "Effective position of brake pedal state validity of BRAKE_STATUS_ESP.";
CM_ SG_ 792 ESP_BrkPedlSts "Brake pedal state indicating brake pedal activated by driver or not.";
CM_ SG_ 792 ESP_VehSpdVld "ABS_ESC signal indicates whether the vehicle speed is valid When the diagnostic have set the failure code on this signal the value wil be 2.";
CM_ SG_ 792 ESP_SysActv "ESP works effectively Is used to indicate to the driver that the system is currently active. Not used for ABS.";
CM_ SG_ 792 ESP_LampSwtOffIndcn "ESP OFF indication Signal indicates to light up 'TCS/ESP off' lamp.-manual switch off of ESP function (on/off switch).Not used for ABS.";
CM_ SG_ 792 ESP_FltIndcn_EBD "EBD fault indication Signal indicates to light up EBD lamp.";
CM_ SG_ 792 ESP_FltIndcn_ABS "ABS fault indication Signal indicates to light up ABS lamp.";
CM_ SG_ 792 ESP_MilgRollgCntr_ODO "Mileage statistical pulse Odometer rolling count 1 pulse/bit. The value shall be set to zero at every ignition off and if the counter reach max value it starts from zero again.";
CM_ SG_ 792 ESP_VehSpd "Speed signal";
CM_ SG_ 792 ESP_IninModSigIndcn "The signal needs to cover the time of ESP and ABS fault signals caused by self-inspection. Signal indicates if ESP or ABS is in initialization mode or not.";
CM_ SG_ 792 ESP_FltIndcn_TCS "ESP/TCS fault indication Signal indicates failure monitoring of ESP function. Not used for ABS";
CM_ SG_ 792 ESP_CtrlSts_HDC "Indicate that the HDC is on/off or working, and the ADAS receives this signal to determine whether the ACC is off. HDC control(Off/On, not active braking/On, active braking).";
CM_ SG_ 792 ESP_AvlIndcn_HDC "Effective bit of HDC indicating HDC is available or not.";
CM_ SG_ 792 ESP_NoBrkP "When the vehicle is stationary, whether the function has braking force or not, whether it is braking.no brake pressure applied; generally it regards wheel cylinder presure.";
CM_ SG_ 792 ESP_RDAEnaFlg "ESP remote driving function enable flag position";
CM_ SG_ 816 BMS_330_391_CheckSum "BMS_330_Message checksum (E2E data ID: 0x3F)";
CM_ SG_ 816 BMS_330_391_AliveCounter "BMS_330_AliveCounter";
CM_ SG_ 816 BMS_VehInsulFltDisp "Vehicle insulation fault display";
CM_ SG_ 816 BMS_PwrBattSysFltDisp "Power battery system fault display";
CM_ SG_ 816 BMS_PwrBattRmngCpSOC "Remaining SOC";
CM_ SG_ 816 BMS_PwrBattAvlCp "Power battery capacity in kWh";
CM_ SG_ 816 BMS_CellMinTAlrm "cell temperature too low";
CM_ SG_ 816 BMS_PwrBattThermRunawayAlrm "Thermal Runaway detected ";
CM_ SG_ 816 BMS_PwrBattOverT "cell temperature too high";
CM_ SG_ 816 BMS_PwrBattInsulSts "Traction battery insulation state";
CM_ SG_ 816 BMS_330_SSecOC_Fresh_Byte0 "Short SecOC Fresh signal byte 0 on CAN";
CM_ SG_ 816 BMS_330_SSecOC_MAC_Byte0 "Short SecOC MAC signal byte 0 on CAN";
CM_ SG_ 816 BMS_330_SSecOC_MAC_Byte1 "Short SecOC MAC signal byte 1 on CAN";
CM_ SG_ 816 BMS_330_SSecOC_MAC_Byte2 "Short SecOC MAC signal byte 2 on CAN";
CM_ SG_ 817 PKC_331_CheckSum "PKC_331_CheckSum ( 0xCA)";
CM_ SG_ 817 PKC_331_AliveCounter "PKC_331_AliveCounter";
CM_ SG_ 817 PKC_OTARdy_Fb "PKC OTA ready status feedback";
CM_ SG_ 817 PKC_RemReqCfmRxResp "Remote control request confirmation receiving feedback PKC";
CM_ SG_ 817 PKC_SysLrngMod "System learning mode";
CM_ SG_ 817 PKC_StrtReq "Activation request";
CM_ SG_ 817 PKC_IMMO_AuthSts "Immo authentication status";
CM_ SG_ 817 PKC_RemModOpenSts "Remote mode ON state";
CM_ SG_ 817 PKC_MnvrSelect "Select maneuver";
CM_ SG_ 817 PKC_MnvrDelete "Delete maneuver";
CM_ SG_ 817 PKC_331_SSecOC_Fresh_Byte0 "Short SecOC Fresh signal byte 0 on CAN";
CM_ SG_ 817 PKC_331_SSecOC_MAC_Byte0 "Short SecOC MAC signal byte 0 on CAN";
CM_ SG_ 817 PKC_331_SSecOC_MAC_Byte1 "Short SecOC MAC signal byte 1 on CAN";
CM_ SG_ 817 PKC_331_SSecOC_MAC_Byte2 "Short SecOC MAC signal byte 2 on CAN";
CM_ SG_ 819 BCM_333_CheckSum "BCM333_message checksum ( 0xCB)BCM_333_CheckSum";
CM_ SG_ 819 BCM_333_AliveCounter "BCM333_Packet counterBCM_333_AliveCounter";
CM_ SG_ 819 BCM_KL15_Off_Announcement "Before switching off the KL15 (5s), this signal gets active to inform other ECUs that the KL15 will be disabled in 5seconds if there are still no triggers to keep it active";
CM_ SG_ 819 BCM_IG1Sts "IG1 state";
CM_ SG_ 819 BCM_PwrMod "Power mode";
CM_ SG_ 819 BCM_PwrModVld "Effective value of power mode";
CM_ SG_ 819 BCM_BrkSwtSts "Brake switch status";
CM_ SG_ 819 BCM_IG1StsVld_CAPE "Effective value of IG1 state";
CM_ SG_ 819 BCM_IG2StsVld_CAPE "Effective value of IG2 state";
CM_ SG_ 819 BCM_KL30s_L "Logical State of KL30";
CM_ SG_ 819 BCM_IG2Sts "IG2 state";
CM_ SG_ 819 BCM_InteriorSwtSt "Interior switch status from LIN1";
CM_ SG_ 835 BCM_343_CheckSum "BCM3343_Message checksum ( 0xD7)BCM_343_CheckSum";
CM_ SG_ 835 BCM_343_AliveCounter "BCM3343_Message counterBCM_343_AliveCounter";
CM_ SG_ 835 BCM_RemReqFb "Remote request feedback";
CM_ SG_ 835 BCM_APASwSts "APA switch state";
CM_ SG_ 835 BCM_FrntHoodLidSts "Status of front engine hood";
CM_ SG_ 835 BCM_SunroofAntipinchSts "Sunroof anti-pinch state";
CM_ SG_ 835 BCM_FrntDrDoorLockSts "Driver door lock state";
CM_ SG_ 835 BCM_TrRelsSwtSts "State of micro switch of tail gate";
CM_ SG_ 835 BCM_LockAllDoorCmd "Four door locking output command";
CM_ SG_ 835 BCM_DrFrntDoorSts "Lock StATUS driver Door used as central lock information ";
CM_ SG_ 835 BCM_PasFrntDoorSts "Lock Status Passinger Front  Door used as central lock information ";
CM_ SG_ 835 BCM_AntithftSts "Body anti-theft state";
CM_ SG_ 835 BCM_CenLockSwtSts "Central control lock switch state";
CM_ SG_ 835 BCM_DoorUnlockSetFb "Door unlocking setting feedback";
CM_ SG_ 835 BCM_RiReDoorSts "State of RR door";
CM_ SG_ 835 BCM_LeReDoorSts "State of left rear door";
CM_ SG_ 835 BCM_LeFrntWinSts "Opening and closing state of left front window";
CM_ SG_ 835 BCM_RiFrntWinSts "Opening and closing state of right front window";
CM_ SG_ 835 BCM_LeReWinSts "Opening and closing state of left rear window";
CM_ SG_ 835 BCM_RiReWinSt "Opening and closing state of right rear window";
CM_ SG_ 835 BCM_SunroofSts "Opening and closing status of sunroof";
CM_ SG_ 835 BCM_FolwMeSetStsFb "Follow me home setting status feedback";
CM_ SG_ 835 BCM_DrvrDoorUnlckOutpCmd "Driver door unlocking output command";
CM_ SG_ 835 BCM_PassDoorUnlckOutpCmd "Passenger door unlocking output command";
CM_ SG_ 835 BCM_LeDRLOutpCmd "Left daytime running lamp output command";
CM_ SG_ 835 BCM_RiDRLOutpCmd "Right daytime running lamp output command";
CM_ SG_ 835 BCM_ArmedClsWinSetSts "Central control screen control window setting state";
CM_ SG_ 835 BCM_OffAutoUnlckSetSts "Automatic unlocking setting state of central control flameout";
CM_ SG_ 835 BCM_WarnVbrnSts "BCM vibration alarm activated state";
CM_ SG_ 835 BCM_SunroofPosnInfo "Sunroof opening information";
CM_ SG_ 835 BCM_SunroofOpenAr "Sunroof opening area";
CM_ SG_ 835 BCM_SteerWhlVbrnAlrmAvl "Whether steering wheel vibration alarm is available";
CM_ SG_ 835 BCM_SunroofRunngSts "Sunroof operation state";
CM_ SG_ 835 BCM_MirrCmd "Exterior rearview mirror control";
CM_ SG_ 837 BCM_345_CheckSum "BCM_345_Message checksum ( 0xD9)BCM_345_CheckSum";
CM_ SG_ 837 BCM_345_AliveCounter "BCM345_Packet counterBCM_345_AliveCounter";
CM_ SG_ 837 BCM_OutpValResl_HUD "HUD output value resolution";
CM_ SG_ 837 BCM_SunshadeRunngSts "Sunshade running status";
CM_ SG_ 837 BCM_RiSolaValr_RLS "Solar radiation intensity at the right side";
CM_ SG_ 837 BCM_LeSolaValr_RLS "Left solar radiation intensity";
CM_ SG_ 837 BCM_WindshdHum_RLS "Glass humidity";
CM_ SG_ 837 BCM_WindshdT_RLS "Glass temperature";
CM_ SG_ 837 BCM_MeasdVal_HUD "HUD function measurement value";
CM_ SG_ 837 BCM_SunshadePosnInfo "Sunshade opening information";
CM_ SG_ 852 MCU_R_354_CheckSum "MCU_R_354_Message checksum(E2E data ID: 0xB4)";
CM_ SG_ 852 MCU_R_354_AliveCounter "Rear MCU life signal";
CM_ SG_ 852 MCU_R_ReqZeroTqFlg "Rear MCU request zero torque flag bit";
CM_ SG_ 852 MCU_R_CrtSts "Current state of rear drive motorMotorRState";
CM_ SG_ 852 MCU_R_MaxPwrGennTq "Maximum braking torque of rear drive motorMotorRMaximumGeneratingTorque.";
CM_ SG_ 852 MCU_R_MaxElecTq "Maximum driving torque of rear drive motorMotorRMaximumMotoringTorque.";
CM_ SG_ 852 MCU_R_MOT_T "Temperature of rear drive motor";
CM_ SG_ 852 MCU_R_IGBTT "Rear MCU IGBT temperatureMCURIGBTTemperature.";
CM_ SG_ 853 MCU_F_355_CheckSum "MCU_F_355_Message checksum(E2E data ID: 0xB5)";
CM_ SG_ 853 MCU_F_355_AliveCounter "Front MCU life signal";
CM_ SG_ 853 MCU_F_ReqZeroTqFlg "Front MCU request zero torque flag";
CM_ SG_ 853 MCU_F_CrtSts "Current state of front drive motorMotorFState";
CM_ SG_ 853 MCU_F_MaxPwrGennTq "Maximum braking torque of front drive motorMotorFMaximumGeneratingTorque.";
CM_ SG_ 853 MCU_F_MaxElecTq "Maximum driving torque of front drive motorMotorFMaximumMotoringTorque.";
CM_ SG_ 853 MCU_F_MOT_T "Temperature of front drive motorMotorFTemerature.";
CM_ SG_ 853 MCU_F_IGBTT "Front MCU IGBT temperatureMCUFIGBTTemperature.";
CM_ SG_ 855 VCU_357_CheckSum "VCU_357_Message checksum ( E2E data ID: 0xB3)";
CM_ SG_ 855 VCU_357_AliveCounter "VCU_357_Message counterVCU_357_AliveCounter";
CM_ SG_ 855 VCU_ChrgSts_GB "Charging state (national standard)";
CM_ SG_ 855 VCU_MCUFltSum_GB "Total number N2 of driving motor faults (national standard)";
CM_ SG_ 855 VCU_BrkPedlSts_GB "Brake pedal state (national standard)";
CM_ SG_ 855 VCU_SOCLoWakeUpThd "Low power wake-up threshold";
CM_ SG_ 855 VCU_SOCLoWakeUpEnaCmd "Power low wake-up enable command";
CM_ SG_ 855 VCU_DrvModDiRmn "Disable the instrument reminder in driving mode";
CM_ SG_ 855 VCU_SpclTerrainModUsrRmn "All-terrain mode user reminder";
CM_ SG_ 855 VCU_BattIntegtChrgEndFlg "Battery Intelligent end-of-charge flag position";
CM_ SG_ 855 VCU_BattIntegtChrgModPwrOnReq "Battery smart charging mode power-on demand";
CM_ SG_ 855 VCU_BattIntegtChrgWakeUpSts "Battery intelligent charging wake-up state";
CM_ SG_ 855 VCU_RemUgrdFltFbSig "Remote Upgrade Fault Feedback Signal";
CM_ SG_ 855 VCU_OTAInhbRdy "OTA pre-condition and Inhibiting of all OTA relevant ECUs";
CM_ SG_ 856 VCU_358_CheckSum "VCU_0x358_Message Check (E2E data ID: 0x47)";
CM_ SG_ 856 VCU_358_AliveCounter "VCU_0x358_Message counter";
CM_ SG_ 856 VCU_KickdwnFlg "status of kickdown function ";
CM_ SG_ 856 VCU_EPedlEnaSig "E-Pedal enable signal (TBD if required)";
CM_ SG_ 856 VCU_ComLostFlt_ESP "VCU and ESP communication related faults";
CM_ SG_ 856 VCU_ComFlt_iBooster "VCU and iBooster communication failure_U101587_E03";
CM_ SG_ 856 VCU_RegenLvlFb "Coasting Mode settings (Off, Normal, high) feedback to ICC";
CM_ SG_ 856 VCU_AccelModFb "Acceleration Mode setting (Low/Mid/High) feedback to ICC";
CM_ SG_ 856 VCU_EPedlStsFb "Pedal Comport Setting (One Pedal Drive / Roll / Creep) feedback to ICC";
CM_ SG_ 856 VCU_CcTrgSpdDisp "Cruise Control Target Speed display";
CM_ SG_ 856 VCU_Sts_CC_ICC "ACC status";
CM_ SG_ 856 VCU_CCIconDisp "ACC icon color";
CM_ SG_ 856 VCU_DispSpdUnit_CC "CC display speed unit";
CM_ SG_ 856 VCU_BoostEnStat "Boost Enable Status";
CM_ SG_ 856 VCU_OTARdy_Fb "VCU OTA ready status feedback";
CM_ SG_ 856 VCU_OTA_ECUInhb_Req "VCU OTA inhibit request to ECUs";
CM_ SG_ 856 VCU_OTAVehCdnChk_ASIL "ASIL A group OTA vehicle condition check status";
CM_ SG_ 856 VCU_OTAVehInhb_ASIL_Fb "ASIL A group OTA vehicle Inhibit feedback";
CM_ SG_ 864 BMS_PwrBattPosGNDInsulRrel "Relative Insulation resistance of positive pole of traction battery to GND";
CM_ SG_ 864 BMS_PwrBattNegGNDInsulRrel "Relative Insulation resistance of negative pole of traction battery to GND";
CM_ SG_ 864 BMS_PwrBattPosGNDInsulR "Insulation resistance of positive pole of traction battery to GND";
CM_ SG_ 864 BMS_PwrBattNegGNDInsulR "Insulation resistance of negative pole of traction battery to GND";
CM_ SG_ 867 VCU_ACDchaStrtFailReason "Reasons for AC discharge failure or current drop";
CM_ SG_ 867 VCU_AllwRemHeatgSts "VCU allows remote heating status";
CM_ SG_ 867 VCU_FbRemHeatgOperSts "VCU feedback of remote heating working status";
CM_ SG_ 867 VCU_ChrgEndSOCCrtCtrlFlg "SOC correction current control mark at charging end";
CM_ SG_ 867 VCU_Lvl2ProtStrtFlg "Secondary protection start flag bit";
CM_ SG_ 867 VCU_TotOverVoltLvl2ProtFlg "Total voltage overvoltage secondary protection flag bit";
CM_ SG_ 867 VCU_UnderVoltFltLvl2ProtFlg "Undervoltage fault secondary protection flag bit";
CM_ SG_ 867 VCU_OverTFltLvl2ProtFlg "Overtemperature fault secondary protection flag bit";
CM_ SG_ 867 VCU_OverVoltFltLvl2ProtFlg "Overvoltage fault secondary protection flag bit";
CM_ SG_ 867 VCU_CellIntShoFltLvl2ProtFlg "Secondary protection symbol in single cell internal short circuit fault";
CM_ SG_ 867 VCU_InsulFltLvl2ProtFlg "Insulation fault secondary protection flag bit";
CM_ SG_ 867 VCU_VehCfgExchgFlg "VCU models are equipped with interchangeable marks";
CM_ SG_ 867 VCU_ReadEEFailFlg "VCU reading EE failure flag bit";
CM_ SG_ 867 VCU_WrEEFailFlg "VCU write EE failure flag bit";
CM_ SG_ 867 VCU_FirstUseEEFlg "EE flag is used for the first time in VCU";
CM_ SG_ 867 VCU_SwUpdataFlg "VCU software upgrade flag bit";
CM_ SG_ 867 VCU_NewOldEESwtFlg "VCU new and old EE switching flag bit";
CM_ SG_ 867 VCU_FSCFillEndFlg "Fast and slow charging and normal filling end flag position";
CM_ SG_ 867 VCU_MaxAlrmLvl "VCU maximum alarm level";
CM_ SG_ 867 VCU_UsrStopChrgReqSts "User termination charging request state";
CM_ SG_ 867 VCU_DchaIndcrLampCtrlCmd "Discharge indicator control command";
CM_ SG_ 867 VCU_VehExtDchaSts "External discharge state of vehicle";
CM_ SG_ 867 VCU_S1SwtCmd "S1 switch command";
CM_ SG_ 867 VCU_DchaFltStsIndcn "AC discharge system fault";
CM_ SG_ 867 VCU_DchaUsrSetThd "Whether the discharge reaches the user set threshold";
CM_ SG_ 867 VCU_RemHeatgDmd "VCU remote heating demand";
CM_ SG_ 867 VCU_PwrBattHeatgTyp "Traction battery heating method";
CM_ SG_ 867 VCU_RemPwrBattPreheatgDmdTi "Time required for preheating of remote traction battery";
CM_ SG_ 867 VCU_ChrgInsulFctOpenSts "Charging insulation function on state";
CM_ SG_ 867 VCU_ChrgEquipPwrNotEngh "Insufficient charging equipment power";
CM_ SG_ 867 VCU_ACChrgStrtFailReason "AC charging cannot be turned on or current charging is reduced";
CM_ SG_ 868 BCM_364_CheckSum "BCM_364_Message checksum (0xD3)BCM_364_CheckSum";
CM_ SG_ 868 BCM_364_AliveCounter "BCM_364_Message counterBCM_364_AliveCounter";
CM_ SG_ 868 BCM_OTARdy_Fb "BCM OTA ready status feedback";
CM_ SG_ 868 BCM_SBRMatStPass "SBR mat state  of the passenger seat";
CM_ SG_ 868 BCM_BucSwtSt2ndRowLeft "Buckle switch state  2nd row left";
CM_ SG_ 868 BCM_BucSwtSt2ndRowMid "Buckle switch state  2nd row mid";
CM_ SG_ 868 BCM_BucSwtSt2ndRowRight "Buckle switch state  2nd row right";
CM_ SG_ 868 BCM_BucSwtSt3rdRowLeft "Buckle switch state  3rd row left";
CM_ SG_ 868 BCM_BucSwtSt3rdRowRight "Buckle switch state  3rd row right";
CM_ SG_ 868 BCM_SBRMatSt2ndRowLeft "SBR mat state  2nd row left";
CM_ SG_ 868 BCM_SBRMatSt2ndRowMid "SBR mat state  2nd row mid";
CM_ SG_ 868 BCM_SBRMatSt2ndRowRight "SBR mat state  2nd row right";
CM_ SG_ 868 BCM_SBRMat3rdRowLeft "SBR mat state  3rd row left";
CM_ SG_ 868 BCM_SBRMat3rdRowRight "SBR mat state  3rd row right";
CM_ SG_ 869 MCU_F_SecuStsChkFlt "Fault of MCU safety state detection_P116C41_E00MCUFSecuritystateckeckfault.";
CM_ SG_ 869 MCU_F_HVActvDchaFlt "Front MCU active discharge fault_P116D04_E00MCUFActiveDischargeFault.";
CM_ SG_ 869 MCU_F_CtrlPanTChkCircFlt "Front MCU control board temperature detection loop faulty_P116F1C_E00";
CM_ SG_ 869 MCU_F_ComLostFlt_VCU "Front MCU and VCU communication loss faet_U010087C_E00";
CM_ SG_ 869 MCU_F_E2EFlt "Front MCU E2E faulty_U110D87_E00";
CM_ SG_ 869 MCU_F_I2TFlt "Front MCU AC/DC connector I2T failure_P116101_E00";
CM_ SG_ 869 MCU_F_OperModFlt "Front motor operating mode abnormal_P11AE62_E00";
CM_ SG_ 869 MCU_F_CooltOverTFlt "Front motor MCU coolant over-temperature fault_P11AF98_E00";
CM_ SG_ 869 MCU_F_PhaCrtSampleCircFltU "Front-MCU phase current sampling loop fault (U-phase)_P118A12_E03";
CM_ SG_ 869 MCU_F_PhaCrtSampleCircFltV "Front-MCU phase current sampling loop fault (V phase)_P118B12_E03";
CM_ SG_ 869 MCU_F_PhaCrtSampleCircFltW "Front-MCU phase current sampling loop fault (W phase)_P118C12_E03";
CM_ SG_ 869 MCU_F_ThreePhaCrtChkFlt "Front drive motor three-phase current calibration fault_P112164_E03";
CM_ SG_ 869 MCU_F_DCBusUnderVoltFlt "DC bus undervoltage fault of MCU_P114016_E03";
CM_ SG_ 869 MCU_F_DCBusOverVoltFlt "DC bus overvoltage fault of MCU_P114017_E03";
CM_ SG_ 869 MCU_F_PosnSnsrChkCircFlt "Front MCU position signal detection loop faulty_P0A3F00_E03";
CM_ SG_ 869 MCU_F_DCBusVoltSampleCircFlt "Front MCU DC bus voltage sampling loop faulty_P11841C_E03";
CM_ SG_ 869 MCU_F_OverSpdFlt "Front drive motor over-speed fault_P0A4400_E03";
CM_ SG_ 869 MCU_F_IGBTOverTFltU "Front MCU IGBT over-temperature fault (U-phase)_P117098_E00";
CM_ SG_ 869 MCU_F_IGBTTChkCircFltU "Front MCU IGBT temperature detection loop fault (U phase)_P11801C_E00";
CM_ SG_ 869 MCU_F_IGBTTChkCircFltV "Front MCU IGBT temperature detection loop fault (V phase)_P11811C_E00";
CM_ SG_ 869 MCU_F_IGBTTChkCircFltW "Front MCU IGBT temperature detection loop fault (W phase)_P11821C_E00";
CM_ SG_ 869 MCU_F_OverTFlt "Front drive motor over temperature faet_P0A2F98_E00";
CM_ SG_ 869 MCU_F_TChkCircFlt "Front drive motor temperature detection loop faulty_P0A001C_E00";
CM_ SG_ 869 MCU_F_CtrlPanOverTFlt "Front MCU control board over-temperature fault_P117F98_E00";
CM_ SG_ 869 MCU_F_LVPwrSplyUnderVoltFlt "Front MCU low voltage power undervoltage fault_U300316C_E03";
CM_ SG_ 869 MCU_F_LVPwrSplyOverVoltFlt "Overvoltage failure of the low voltage supply of the front MCU_U300317C_E03";
CM_ SG_ 869 MCU_F_FbTqStsChkFlt "Front MCU feedback torque and torque command check error_P113064_E03";
CM_ SG_ 869 MCU_F_PhaCrtSwOverCrtFltU "Front-MCU phase current hardware overcurrent fault (U-phase)_P116016_E03";
CM_ SG_ 869 MCU_F_TqCmdOverLimFlt "Overrun fault of the front MCU torque command_U040186_E03";
CM_ SG_ 869 MCU_F_PwrSplyModFlt "Front MCU power supply module faulty_P11A01C_E03";
CM_ SG_ 869 MCU_F_IGBTThreePhaTChkFlt "Front MCU IGBT three-phase temperature check fault_P116E41_E00";
CM_ SG_ 869 MCU_F_RotCalFlt "Front drive motor rotation transformer calibration fault_P116F04_E00";
CM_ SG_ 869 MCU_F_IntComFlt "Internal communication of pre-MCU fa_U110C87_E00";
CM_ SG_ 869 MCU_F_IntTqChkFlt "Front MCU internal torque verification fault_P116096_E00";
CM_ SG_ 869 MCU_F_IGBTDesatFltTop "Front-MCU internal IGBT drive circuit fault (U-phase lower bridge)_P11A201_E00MCUFIGBTvoltagefault(U BOTTOM).";
CM_ SG_ 869 MCU_F_IGBTDesatFltBot "Front MCU internal IGBT drive circuit fault (V phase down bridge)_P11A401_E00MCUFIGBTvoltagelow(V BOTTOM).";
CM_ SG_ 869 MCU_F_PhaCrtSwOverCrtFltV "Front-MCU phase current hardware overcurrent fault (V phase)_P116116_E00";
CM_ SG_ 869 MCU_F_PhaCrtSwOverCrtFltW "Front-MCU phase current hardware overcurrent fault (W phase)_P116216_E00";
CM_ SG_ 869 MCU_F_IGBTOverTFltV "Front MCU IGBT over-temperature fault (phase V)_P117198_E00";
CM_ SG_ 869 MCU_F_IGBTOverTFltW "Pre-MCU IGBT over-temperature fault (W phase)_P117298_E00";
BA_DEF_ BO_  "NmAsrMessage" ENUM  "No","Yes";
BA_DEF_ SG_  "GenSigCycleTime" INT 0 0;
BA_DEF_ BO_  "NmMessage" ENUM  "No","Yes";
BA_DEF_ BO_  "SC_Message" ENUM  "No","Yes","Yes, split message";
BA_DEF_ BO_  "DiagState" ENUM  "No","Yes";
BA_DEF_ BO_  "SC_LinkPos" INT 0 65535;
BA_DEF_ BO_  "DiagRequest" ENUM  "No","Yes";
BA_DEF_ BO_  "DiagFdOnly" ENUM  "No","Yes";
BA_DEF_ BO_  "DiagResponse" ENUM  "No","Yes";
BA_DEF_ BO_  "SCP_AuthInfoTxLength" INT 0 512;
BA_DEF_ BO_  "GenMsgSendType" ENUM  "Cyclic","NotUsed","NotUsed","NotUsed","NotUsed","NotUsed","NotUsed","IfActive","NoMsgSendType";
BA_DEF_ BO_  "SCP_DataId" INT 0 65535;
BA_DEF_ BO_  "GenMsgCycleTime" INT 0 0;
BA_DEF_ BO_  "SCP_FreshnessValueId" INT 0 65535;
BA_DEF_ BO_  "SCP_FreshnessValueLength" INT 0 512;
BA_DEF_ SG_  "GenSigStartValue" INT 0 0;
BA_DEF_ BO_  "SCL_CryptographicMessageID" INT 0 65535;
BA_DEF_ SG_  "GenSigInactiveValue" INT 0 0;
BA_DEF_ SG_  "GenSigSendType" ENUM  "Cyclic","OnWrite","OnWriteWithRepetition","OnChange","OnChangeWithRepetition","IfActive","IfActiveWithRepetition","NoSigSendType";
BA_DEF_ BO_  "SCP_FreshnessValueTxLength" INT 0 512;
BA_DEF_ BO_  "GenMsgCycleTimeFast" INT 0 0;
BA_DEF_ BO_  "GenMsgNrOfRepetition" INT 0 0;
BA_DEF_ BO_  "DiagConnection" INT 0 65535;
BA_DEF_ BO_  "GenMsgDelayTime" INT 0 0;
BA_DEF_ BO_  "CANFD_BRS" ENUM  "0","1";
BA_DEF_ BO_  "VFrameFormat" ENUM  "StandardCAN","ExtendedCAN","reserved","reserved","reserved","reserved","reserved","reserved","reserved","reserved","reserved","reserved","reserved","reserved","StandardCAN_FD","ExtendedCAN_FD";
BA_DEF_ BO_  "GenMsgILSupport" ENUM  "No","Yes";
BA_DEF_ BO_  "GenMsgStartDelayTime" INT 0 65535;
BA_DEF_ BO_  "E2EP01DataLength" INT 0 65535;
BA_DEF_ BO_  "E2EP01DataId" INT 0 65535;
BA_DEF_ SG_  "sigSecLevel" STRING ;
BA_DEF_ SG_  "sigConfig" STRING ;
BA_DEF_ SG_  "sigExplanation" STRING ;
BA_DEF_ SG_  "SystemSignalLongSymbol" STRING ;
BA_DEF_REL_ BU_SG_REL_  "SC_Verification" ENUM  "No","Yes";
BA_DEF_DEF_  "NmAsrMessage" "No";
BA_DEF_DEF_  "GenSigCycleTime" 0;
BA_DEF_DEF_  "NmMessage" "No";
BA_DEF_DEF_  "SC_Message" "No";
BA_DEF_DEF_  "DiagState" "No";
BA_DEF_DEF_  "SC_LinkPos" 0;
BA_DEF_DEF_  "DiagRequest" "No";
BA_DEF_DEF_  "DiagFdOnly" "No";
BA_DEF_DEF_  "DiagResponse" "No";
BA_DEF_DEF_  "SCP_AuthInfoTxLength" 0;
BA_DEF_DEF_  "GenMsgSendType" "Cyclic";
BA_DEF_DEF_  "SCP_DataId" 0;
BA_DEF_DEF_  "GenMsgCycleTime" 0;
BA_DEF_DEF_  "SCP_FreshnessValueId" 0;
BA_DEF_DEF_  "SCP_FreshnessValueLength" 0;
BA_DEF_DEF_  "GenSigStartValue" 0;
BA_DEF_DEF_  "SCL_CryptographicMessageID" 0;
BA_DEF_DEF_  "GenSigInactiveValue" 0;
BA_DEF_DEF_  "GenSigSendType" "Cyclic";
BA_DEF_DEF_  "SCP_FreshnessValueTxLength" 0;
BA_DEF_DEF_  "GenMsgCycleTimeFast" 0;
BA_DEF_DEF_  "GenMsgNrOfRepetition" 0;
BA_DEF_DEF_  "DiagConnection" 0;
BA_DEF_DEF_  "GenMsgDelayTime" 0;
BA_DEF_DEF_  "CANFD_BRS" "1";
BA_DEF_DEF_  "VFrameFormat" "StandardCAN";
BA_DEF_DEF_  "GenMsgILSupport" "Yes";
BA_DEF_DEF_  "GenMsgStartDelayTime" 0;
BA_DEF_DEF_  "E2EP01DataLength" 0;
BA_DEF_DEF_  "E2EP01DataId" 0;
BA_DEF_DEF_  "sigSecLevel" "";
BA_DEF_DEF_  "sigConfig" "";
BA_DEF_DEF_  "sigExplanation" "";
BA_DEF_DEF_REL_ "SC_Verification" "No";
BA_DEF_DEF_  "SystemSignalLongSymbol" "";
BA_ "E2EP01DataId" BO_ 565 85;
BA_ "E2EP01DataLength" BO_ 565 64;
BA_ "GenMsgCycleTime" BO_ 565 20;
BA_ "VFrameFormat" BO_ 565 14;
BA_ "E2EP01DataId" BO_ 566 148;
BA_ "E2EP01DataLength" BO_ 566 64;
BA_ "GenMsgCycleTime" BO_ 566 20;
BA_ "VFrameFormat" BO_ 566 14;
BA_ "E2EP01DataId" BO_ 586 168;
BA_ "E2EP01DataLength" BO_ 586 64;
BA_ "GenMsgCycleTime" BO_ 586 20;
BA_ "VFrameFormat" BO_ 586 14;
BA_ "E2EP01DataId" BO_ 608 93;
BA_ "E2EP01DataLength" BO_ 608 64;
BA_ "GenMsgCycleTime" BO_ 608 20;
BA_ "SCL_CryptographicMessageID" BO_ 608 608;
BA_ "SCP_AuthInfoTxLength" BO_ 608 24;
BA_ "SCP_DataId" BO_ 608 608;
BA_ "SCP_FreshnessValueId" BO_ 608 608;
BA_ "SCP_FreshnessValueLength" BO_ 608 64;
BA_ "SCP_FreshnessValueTxLength" BO_ 608 8;
BA_ "SC_LinkPos" BO_ 608 64;
BA_ "SC_Message" BO_ 608 1;
BA_ "VFrameFormat" BO_ 608 14;
BA_ "GenMsgSendType" BO_ 627 8;
BA_ "GenMsgNrOfRepetition" BO_ 627 3;
BA_ "GenMsgCycleTimeFast" BO_ 627 100;
BA_ "VFrameFormat" BO_ 627 14;
BA_ "E2EP01DataId" BO_ 632 82;
BA_ "E2EP01DataLength" BO_ 632 64;
BA_ "GenMsgCycleTime" BO_ 632 50;
BA_ "VFrameFormat" BO_ 632 14;
BA_ "E2EP01DataId" BO_ 633 83;
BA_ "E2EP01DataLength" BO_ 633 64;
BA_ "GenMsgCycleTime" BO_ 633 50;
BA_ "VFrameFormat" BO_ 633 14;
BA_ "GenMsgCycleTime" BO_ 649 200;
BA_ "VFrameFormat" BO_ 649 14;
BA_ "GenMsgCycleTime" BO_ 678 100;
BA_ "VFrameFormat" BO_ 678 14;
BA_ "GenMsgCycleTime" BO_ 681 100;
BA_ "VFrameFormat" BO_ 681 14;
BA_ "GenMsgCycleTime" BO_ 684 100;
BA_ "VFrameFormat" BO_ 684 14;
BA_ "GenMsgCycleTime" BO_ 687 100;
BA_ "VFrameFormat" BO_ 687 14;
BA_ "GenMsgCycleTime" BO_ 743 100;
BA_ "VFrameFormat" BO_ 743 14;
BA_ "GenMsgCycleTime" BO_ 748 100;
BA_ "VFrameFormat" BO_ 748 14;
BA_ "GenMsgCycleTime" BO_ 749 100;
BA_ "VFrameFormat" BO_ 749 14;
BA_ "GenMsgCycleTime" BO_ 750 100;
BA_ "VFrameFormat" BO_ 750 14;
BA_ "GenMsgCycleTime" BO_ 751 100;
BA_ "VFrameFormat" BO_ 751 14;
BA_ "GenMsgCycleTime" BO_ 752 100;
BA_ "VFrameFormat" BO_ 752 14;
BA_ "E2EP01DataId" BO_ 755 243;
BA_ "E2EP01DataLength" BO_ 755 64;
BA_ "GenMsgCycleTime" BO_ 755 100;
BA_ "VFrameFormat" BO_ 755 14;
BA_ "GenMsgCycleTime" BO_ 756 100;
BA_ "VFrameFormat" BO_ 756 14;
BA_ "GenMsgCycleTime" BO_ 757 100;
BA_ "VFrameFormat" BO_ 757 14;
BA_ "E2EP01DataId" BO_ 758 130;
BA_ "E2EP01DataLength" BO_ 758 64;
BA_ "GenMsgCycleTime" BO_ 758 100;
BA_ "VFrameFormat" BO_ 758 14;
BA_ "GenMsgCycleTime" BO_ 759 100;
BA_ "VFrameFormat" BO_ 759 14;
BA_ "E2EP01DataId" BO_ 760 137;
BA_ "E2EP01DataLength" BO_ 760 64;
BA_ "GenMsgCycleTime" BO_ 760 100;
BA_ "VFrameFormat" BO_ 760 14;
BA_ "GenMsgCycleTime" BO_ 761 100;
BA_ "VFrameFormat" BO_ 761 14;
BA_ "E2EP01DataId" BO_ 767 231;
BA_ "E2EP01DataLength" BO_ 767 64;
BA_ "GenMsgCycleTime" BO_ 767 100;
BA_ "VFrameFormat" BO_ 767 14;
BA_ "GenMsgCycleTime" BO_ 783 1000;
BA_ "VFrameFormat" BO_ 783 14;
BA_ "E2EP01DataId" BO_ 785 79;
BA_ "E2EP01DataLength" BO_ 785 64;
BA_ "GenMsgCycleTime" BO_ 785 20;
BA_ "VFrameFormat" BO_ 785 14;
BA_ "E2EP01DataId" BO_ 792 121;
BA_ "E2EP01DataLength" BO_ 792 64;
BA_ "GenMsgCycleTime" BO_ 792 20;
BA_ "VFrameFormat" BO_ 792 14;
BA_ "GenMsgCycleTime" BO_ 799 200;
BA_ "VFrameFormat" BO_ 799 14;
BA_ "E2EP01DataId" BO_ 816 63;
BA_ "E2EP01DataLength" BO_ 816 64;
BA_ "GenMsgCycleTime" BO_ 816 50;
BA_ "SCL_CryptographicMessageID" BO_ 816 816;
BA_ "SCP_AuthInfoTxLength" BO_ 816 24;
BA_ "SCP_DataId" BO_ 816 816;
BA_ "SCP_FreshnessValueId" BO_ 816 816;
BA_ "SCP_FreshnessValueLength" BO_ 816 64;
BA_ "SCP_FreshnessValueTxLength" BO_ 816 8;
BA_ "SC_LinkPos" BO_ 816 64;
BA_ "SC_Message" BO_ 816 1;
BA_ "VFrameFormat" BO_ 816 14;
BA_ "E2EP01DataId" BO_ 817 202;
BA_ "E2EP01DataLength" BO_ 817 64;
BA_ "GenMsgCycleTime" BO_ 817 50;
BA_ "GenMsgCycleTimeFast" BO_ 817 20;
BA_ "GenMsgDelayTime" BO_ 817 20;
BA_ "SCL_CryptographicMessageID" BO_ 817 817;
BA_ "SCP_AuthInfoTxLength" BO_ 817 24;
BA_ "SCP_DataId" BO_ 817 817;
BA_ "SCP_FreshnessValueId" BO_ 817 817;
BA_ "SCP_FreshnessValueLength" BO_ 817 64;
BA_ "SCP_FreshnessValueTxLength" BO_ 817 8;
BA_ "SC_LinkPos" BO_ 817 64;
BA_ "SC_Message" BO_ 817 1;
BA_ "GenMsgNrOfRepetition" BO_ 817 3;
BA_ "VFrameFormat" BO_ 817 14;
BA_ "E2EP01DataId" BO_ 819 203;
BA_ "E2EP01DataLength" BO_ 819 64;
BA_ "GenMsgCycleTime" BO_ 819 50;
BA_ "VFrameFormat" BO_ 819 14;
BA_ "E2EP01DataId" BO_ 835 215;
BA_ "E2EP01DataLength" BO_ 835 64;
BA_ "GenMsgCycleTime" BO_ 835 50;
BA_ "VFrameFormat" BO_ 835 14;
BA_ "E2EP01DataId" BO_ 837 217;
BA_ "E2EP01DataLength" BO_ 837 64;
BA_ "GenMsgCycleTime" BO_ 837 50;
BA_ "VFrameFormat" BO_ 837 14;
BA_ "E2EP01DataId" BO_ 852 180;
BA_ "E2EP01DataLength" BO_ 852 64;
BA_ "GenMsgCycleTime" BO_ 852 10;
BA_ "VFrameFormat" BO_ 852 14;
BA_ "E2EP01DataId" BO_ 853 181;
BA_ "E2EP01DataLength" BO_ 853 64;
BA_ "GenMsgCycleTime" BO_ 853 10;
BA_ "VFrameFormat" BO_ 853 14;
BA_ "E2EP01DataId" BO_ 855 179;
BA_ "E2EP01DataLength" BO_ 855 64;
BA_ "GenMsgCycleTime" BO_ 855 100;
BA_ "VFrameFormat" BO_ 855 14;
BA_ "E2EP01DataId" BO_ 856 71;
BA_ "E2EP01DataLength" BO_ 856 64;
BA_ "GenMsgCycleTime" BO_ 856 100;
BA_ "VFrameFormat" BO_ 856 14;
BA_ "GenMsgCycleTime" BO_ 864 100;
BA_ "VFrameFormat" BO_ 864 14;
BA_ "GenMsgCycleTime" BO_ 867 100;
BA_ "VFrameFormat" BO_ 867 14;
BA_ "E2EP01DataId" BO_ 868 211;
BA_ "E2EP01DataLength" BO_ 868 64;
BA_ "GenMsgCycleTime" BO_ 868 100;
BA_ "VFrameFormat" BO_ 868 14;
BA_ "GenMsgCycleTime" BO_ 869 10;
BA_ "VFrameFormat" BO_ 869 14;
BA_ "sigConfig" SG_ 565 OBC_235_CheckSum "null";
BA_ "sigExplanation" SG_ 565 OBC_235_CheckSum "null";
BA_ "sigSecLevel" SG_ 565 OBC_235_CheckSum "null";
BA_ "sigConfig" SG_ 565 OBC_235_AliveCounter "null";
BA_ "sigExplanation" SG_ 565 OBC_235_AliveCounter "null";
BA_ "sigSecLevel" SG_ 565 OBC_235_AliveCounter "null";
BA_ "sigConfig" SG_ 565 OBC_DCPosRlyCtrlSts "null";
BA_ "sigExplanation" SG_ 565 OBC_DCPosRlyCtrlSts "null";
BA_ "sigSecLevel" SG_ 565 OBC_DCPosRlyCtrlSts "null";
BA_ "sigConfig" SG_ 565 OBC_DCNegRlyCtrlSts "null";
BA_ "sigExplanation" SG_ 565 OBC_DCNegRlyCtrlSts "null";
BA_ "sigSecLevel" SG_ 565 OBC_DCNegRlyCtrlSts "null";
BA_ "GenSigStartValue" SG_ 565 OBC_DCCrt 12750;
BA_ "sigConfig" SG_ 565 OBC_DCCrt "null";
BA_ "sigExplanation" SG_ 565 OBC_DCCrt "null";
BA_ "sigSecLevel" SG_ 565 OBC_DCCrt "null";
BA_ "sigConfig" SG_ 565 OBC_DCVolt "null";
BA_ "sigExplanation" SG_ 565 OBC_DCVolt "null";
BA_ "sigSecLevel" SG_ 565 OBC_DCVolt "null";
BA_ "GenSigStartValue" SG_ 565 OBC_DCChrgnRlyCrt 12750;
BA_ "sigConfig" SG_ 565 OBC_DCChrgnRlyCrt "null";
BA_ "sigExplanation" SG_ 565 OBC_DCChrgnRlyCrt "null";
BA_ "sigSecLevel" SG_ 565 OBC_DCChrgnRlyCrt "null";
BA_ "sigConfig" SG_ 566 VCU_236_CheckSum "null";
BA_ "sigExplanation" SG_ 566 VCU_236_CheckSum "null";
BA_ "sigSecLevel" SG_ 566 VCU_236_CheckSum "null";
BA_ "sigConfig" SG_ 566 VCU_236_AliveCounter "null";
BA_ "sigExplanation" SG_ 566 VCU_236_AliveCounter "null";
BA_ "sigSecLevel" SG_ 566 VCU_236_AliveCounter "null";
BA_ "sigConfig" SG_ 566 VCU_DCChrgDchaGunCnctnSts "null";
BA_ "sigExplanation" SG_ 566 VCU_DCChrgDchaGunCnctnSts "null";
BA_ "sigSecLevel" SG_ 566 VCU_DCChrgDchaGunCnctnSts "A";
BA_ "sigConfig" SG_ 566 VCU_OutpACWakeupSigSts "null";
BA_ "sigExplanation" SG_ 566 VCU_OutpACWakeupSigSts "null";
BA_ "sigSecLevel" SG_ 566 VCU_OutpACWakeupSigSts "null";
BA_ "sigConfig" SG_ 566 VCU_OutpFCWakeupSigSts "null";
BA_ "sigExplanation" SG_ 566 VCU_OutpFCWakeupSigSts "null";
BA_ "sigSecLevel" SG_ 566 VCU_OutpFCWakeupSigSts "null";
BA_ "sigConfig" SG_ 566 VCU_ACChrgDchaGunCnctnSts "null";
BA_ "sigExplanation" SG_ 566 VCU_ACChrgDchaGunCnctnSts "null";
BA_ "sigSecLevel" SG_ 566 VCU_ACChrgDchaGunCnctnSts "A";
BA_ "sigConfig" SG_ 566 VCU_VcuErrCtgy "null";
BA_ "sigExplanation" SG_ 566 VCU_VcuErrCtgy "null";
BA_ "sigSecLevel" SG_ 566 VCU_VcuErrCtgy "B";
BA_ "sigConfig" SG_ 566 VCU_VcuErrBitVect "null";
BA_ "sigExplanation" SG_ 566 VCU_VcuErrBitVect "null";
BA_ "sigSecLevel" SG_ 566 VCU_VcuErrBitVect "null";
BA_ "GenSigInactiveValue" SG_ 566 VCU_VcuState 31;
BA_ "sigConfig" SG_ 566 VCU_VcuState "null";
BA_ "sigExplanation" SG_ 566 VCU_VcuState "null";
BA_ "sigSecLevel" SG_ 566 VCU_VcuState "B";
BA_ "sigConfig" SG_ 566 VCU_PwrSplyEquipSts "null";
BA_ "sigExplanation" SG_ 566 VCU_PwrSplyEquipSts "null";
BA_ "sigSecLevel" SG_ 566 VCU_PwrSplyEquipSts "null";
BA_ "sigConfig" SG_ 586 BMS_24A_CheckSum "null";
BA_ "sigExplanation" SG_ 586 BMS_24A_CheckSum "null";
BA_ "sigSecLevel" SG_ 586 BMS_24A_CheckSum "null";
BA_ "sigConfig" SG_ 586 BMS_24A_AliveCounter "null";
BA_ "sigExplanation" SG_ 586 BMS_24A_AliveCounter "null";
BA_ "sigSecLevel" SG_ 586 BMS_24A_AliveCounter "null";
BA_ "GenSigStartValue" SG_ 586 BMS_PwrBattChrgDchaCrt1 25000;
BA_ "sigConfig" SG_ 586 BMS_PwrBattChrgDchaCrt1 "null";
BA_ "sigExplanation" SG_ 586 BMS_PwrBattChrgDchaCrt1 "null";
BA_ "sigSecLevel" SG_ 586 BMS_PwrBattChrgDchaCrt1 "null";
BA_ "GenSigStartValue" SG_ 586 BMS_PwrBattChrgDchaCrt2 25000;
BA_ "sigConfig" SG_ 586 BMS_PwrBattChrgDchaCrt2 "null";
BA_ "sigExplanation" SG_ 586 BMS_PwrBattChrgDchaCrt2 "null";
BA_ "sigSecLevel" SG_ 586 BMS_PwrBattChrgDchaCrt2 "null";
BA_ "sigConfig" SG_ 586 BMS_PwrBattIntTotVoltV1 "null";
BA_ "sigExplanation" SG_ 586 BMS_PwrBattIntTotVoltV1 "null";
BA_ "sigSecLevel" SG_ 586 BMS_PwrBattIntTotVoltV1 "null";
BA_ "sigConfig" SG_ 608 VCU_DCVoltCmd_OBC "null";
BA_ "sigExplanation" SG_ 608 VCU_DCVoltCmd_OBC "null";
BA_ "sigSecLevel" SG_ 608 VCU_DCVoltCmd_OBC "null";
BA_ "sigConfig" SG_ 608 VCU_DCCrtCmd_OBC "null";
BA_ "sigExplanation" SG_ 608 VCU_DCCrtCmd_OBC "null";
BA_ "sigSecLevel" SG_ 608 VCU_DCCrtCmd_OBC "null";
BA_ "sigConfig" SG_ 608 VCU_VehChrgDchgMod "null";
BA_ "sigExplanation" SG_ 608 VCU_VehChrgDchgMod "null";
BA_ "sigSecLevel" SG_ 608 VCU_VehChrgDchgMod "A";
BA_ "sigConfig" SG_ 608 VCU_DCRlyCtrlCmd "null";
BA_ "sigExplanation" SG_ 608 VCU_DCRlyCtrlCmd "null";
BA_ "sigSecLevel" SG_ 608 VCU_DCRlyCtrlCmd "A";
BA_ "sigConfig" SG_ 608 VCU_ChrgSysOperCmd "null";
BA_ "sigExplanation" SG_ 608 VCU_ChrgSysOperCmd "null";
BA_ "sigSecLevel" SG_ 608 VCU_ChrgSysOperCmd "A(B)";
BA_ "sigConfig" SG_ 608 VCU_ChrgSts "null";
BA_ "sigExplanation" SG_ 608 VCU_ChrgSts "null";
BA_ "sigSecLevel" SG_ 608 VCU_ChrgSts "null";
BA_ "sigConfig" SG_ 608 VCU_260_SSecOC_Fresh_Byte0 "null";
BA_ "sigExplanation" SG_ 608 VCU_260_SSecOC_Fresh_Byte0 "null";
BA_ "sigSecLevel" SG_ 608 VCU_260_SSecOC_Fresh_Byte0 "null";
BA_ "sigConfig" SG_ 608 VCU_260_SSecOC_MAC_Byte0 "null";
BA_ "sigExplanation" SG_ 608 VCU_260_SSecOC_MAC_Byte0 "null";
BA_ "sigSecLevel" SG_ 608 VCU_260_SSecOC_MAC_Byte0 "null";
BA_ "sigConfig" SG_ 608 VCU_260_SSecOC_MAC_Byte1 "null";
BA_ "sigExplanation" SG_ 608 VCU_260_SSecOC_MAC_Byte1 "null";
BA_ "sigSecLevel" SG_ 608 VCU_260_SSecOC_MAC_Byte1 "null";
BA_ "sigConfig" SG_ 608 VCU_260_SSecOC_MAC_Byte2 "null";
BA_ "sigExplanation" SG_ 608 VCU_260_SSecOC_MAC_Byte2 "null";
BA_ "sigSecLevel" SG_ 608 VCU_260_SSecOC_MAC_Byte2 "null";
BA_ "GenSigSendType" SG_ 627 TBOX_ScheduleCharg_End_Mins 1;
BA_ "GenSigSendType" SG_ 627 TBOX_ScheduleCharg_Start_Hr 1;
BA_ "GenSigSendType" SG_ 627 TBOX_ScheduleCharg_End_Hr 1;
BA_ "GenSigSendType" SG_ 627 TBOX_SetSceduleChargTimeFb 1;
BA_ "GenSigSendType" SG_ 627 TBOX_ScheduleCharg_Start_Mins 1;
BA_ "GenSigSendType" SG_ 627 TBOX_ScheduleCharg_Status 1;
BA_ "GenSigSendType" SG_ 627 TBOX_V2L_TrEna 2;
BA_ "GenSigSendType" SG_ 627 TBOX_V2L_ChrgPortEna 2;
BA_ "GenSigSendType" SG_ 627 TBOX_V2V_Ena 2;
BA_ "GenSigSendType" SG_ 627 TBOX_V2H_Ena 2;
BA_ "GenSigSendType" SG_ 627 TBOX_V2G_Ena 2;
BA_ "sigConfig" SG_ 632 BMS_Curr_PmLT_CheckSum "null";
BA_ "sigExplanation" SG_ 632 BMS_Curr_PmLT_CheckSum "null";
BA_ "sigSecLevel" SG_ 632 BMS_Curr_PmLT_CheckSum "null";
BA_ "sigConfig" SG_ 632 BMS_Curr_PmLT_AliveCounter "null";
BA_ "sigExplanation" SG_ 632 BMS_Curr_PmLT_AliveCounter "null";
BA_ "sigSecLevel" SG_ 632 BMS_Curr_PmLT_AliveCounter "null";
BA_ "sigConfig" SG_ 632 BMS_Bat_D_MAXcurr_PmLT "null";
BA_ "sigExplanation" SG_ 632 BMS_Bat_D_MAXcurr_PmLT "null";
BA_ "sigSecLevel" SG_ 632 BMS_Bat_D_MAXcurr_PmLT "null";
BA_ "sigConfig" SG_ 632 BMS_Bat_C_MAXcurr_PmLT "null";
BA_ "sigExplanation" SG_ 632 BMS_Bat_C_MAXcurr_PmLT "null";
BA_ "sigSecLevel" SG_ 632 BMS_Bat_C_MAXcurr_PmLT "null";
BA_ "sigConfig" SG_ 633 BMS_Volt_PmLT_CheckSum "null";
BA_ "sigExplanation" SG_ 633 BMS_Volt_PmLT_CheckSum "null";
BA_ "sigSecLevel" SG_ 633 BMS_Volt_PmLT_CheckSum "null";
BA_ "sigConfig" SG_ 633 BMS_Volt_PmLT_AliveCounter "null";
BA_ "sigExplanation" SG_ 633 BMS_Volt_PmLT_AliveCounter "null";
BA_ "sigSecLevel" SG_ 633 BMS_Volt_PmLT_AliveCounter "null";
BA_ "sigConfig" SG_ 633 BMS_Bat_D_MAXvolt_PmLT "null";
BA_ "sigExplanation" SG_ 633 BMS_Bat_D_MAXvolt_PmLT "null";
BA_ "sigSecLevel" SG_ 633 BMS_Bat_D_MAXvolt_PmLT "null";
BA_ "sigConfig" SG_ 633 BMS_Bat_C_MAXvolt_PmLT "null";
BA_ "sigExplanation" SG_ 633 BMS_Bat_C_MAXvolt_PmLT "null";
BA_ "sigSecLevel" SG_ 633 BMS_Bat_C_MAXvolt_PmLT "null";
BA_ "GenSigStartValue" SG_ 678 IBS_SOCUpperTolerance 255;
BA_ "GenSigStartValue" SG_ 678 IBS_SOCLowerTolerance 255;
BA_ "GenSigStartValue" SG_ 678 IBS_CapacityLossTop 255;
BA_ "GenSigStartValue" SG_ 678 IBS_CapacityLossBottom 255;
BA_ "GenSigStartValue" SG_ 681 IBS_BatteryCurrent 16777215;
BA_ "GenSigStartValue" SG_ 681 IBS_BatteryVoltage 65534;
BA_ "GenSigStartValue" SG_ 681 IBS_BatteryTemperature 80;
BA_ "GenSigStartValue" SG_ 684 IBS_StateOfCharge 255;
BA_ "GenSigStartValue" SG_ 684 IBS_StateOfHealth 255;
BA_ "GenSigStartValue" SG_ 684 IBS_EstVoltaDrop 255;
BA_ "GenSigStartValue" SG_ 684 IBS_OptChargeVolt 255;
BA_ "GenSigStartValue" SG_ 684 IBS_AvgRi 65535;
BA_ "GenSigStartValue" SG_ 687 IBS_AvailableCapacity 65535;
BA_ "GenSigStartValue" SG_ 687 IBS_DischargeableAh 65535;
BA_ "GenSigStartValue" SG_ 687 IBS_NominalCapacity 255;
BA_ "sigConfig" SG_ 748 BMS_Cont_CurrentState_PV_Pos "null";
BA_ "sigExplanation" SG_ 748 BMS_Cont_CurrentState_PV_Pos "null";
BA_ "sigSecLevel" SG_ 748 BMS_Cont_CurrentState_PV_Pos "null";
BA_ "sigConfig" SG_ 748 BMS_Cont_TargetState_PV_Pos "null";
BA_ "sigExplanation" SG_ 748 BMS_Cont_TargetState_PV_Pos "null";
BA_ "sigSecLevel" SG_ 748 BMS_Cont_TargetState_PV_Pos "null";
BA_ "sigConfig" SG_ 748 BMS_Cont_Coil_I_PV_Pos "null";
BA_ "sigExplanation" SG_ 748 BMS_Cont_Coil_I_PV_Pos "null";
BA_ "sigSecLevel" SG_ 748 BMS_Cont_Coil_I_PV_Pos "null";
BA_ "sigConfig" SG_ 748 BMS_Cont_WearCounter_PV_Pos "null";
BA_ "sigExplanation" SG_ 748 BMS_Cont_WearCounter_PV_Pos "null";
BA_ "sigSecLevel" SG_ 748 BMS_Cont_WearCounter_PV_Pos "null";
BA_ "sigConfig" SG_ 749 BMS_Cont_CurrentState_PV_Neg "null";
BA_ "sigExplanation" SG_ 749 BMS_Cont_CurrentState_PV_Neg "null";
BA_ "sigSecLevel" SG_ 749 BMS_Cont_CurrentState_PV_Neg "null";
BA_ "sigConfig" SG_ 749 BMS_Cont_TargetSgtate_PV_Neg "null";
BA_ "sigExplanation" SG_ 749 BMS_Cont_TargetSgtate_PV_Neg "null";
BA_ "sigSecLevel" SG_ 749 BMS_Cont_TargetSgtate_PV_Neg "null";
BA_ "sigConfig" SG_ 749 BMS_Cont_Coil_I_PV_Neg "null";
BA_ "sigExplanation" SG_ 749 BMS_Cont_Coil_I_PV_Neg "null";
BA_ "sigSecLevel" SG_ 749 BMS_Cont_Coil_I_PV_Neg "null";
BA_ "sigConfig" SG_ 749 BMS_Cont_WearCounter_PV_Neg "null";
BA_ "sigExplanation" SG_ 749 BMS_Cont_WearCounter_PV_Neg "null";
BA_ "sigSecLevel" SG_ 749 BMS_Cont_WearCounter_PV_Neg "null";
BA_ "sigConfig" SG_ 750 BMS_Cont_Act_St_HV_Pos "null";
BA_ "sigExplanation" SG_ 750 BMS_Cont_Act_St_HV_Pos "null";
BA_ "sigSecLevel" SG_ 750 BMS_Cont_Act_St_HV_Pos "null";
BA_ "sigConfig" SG_ 750 BMS_Cont_Tar_St_HV_Pos "null";
BA_ "sigExplanation" SG_ 750 BMS_Cont_Tar_St_HV_Pos "null";
BA_ "sigSecLevel" SG_ 750 BMS_Cont_Tar_St_HV_Pos "null";
BA_ "sigConfig" SG_ 750 BMS_Cont_Coil_I_HV_Pos "null";
BA_ "sigExplanation" SG_ 750 BMS_Cont_Coil_I_HV_Pos "null";
BA_ "sigSecLevel" SG_ 750 BMS_Cont_Coil_I_HV_Pos "null";
BA_ "sigConfig" SG_ 750 BMS_Cont_WearCounter_HV_Pos "null";
BA_ "sigExplanation" SG_ 750 BMS_Cont_WearCounter_HV_Pos "null";
BA_ "sigSecLevel" SG_ 750 BMS_Cont_WearCounter_HV_Pos "null";
BA_ "sigConfig" SG_ 751 BMS_Cont_Act_St_HV_Neg "null";
BA_ "sigExplanation" SG_ 751 BMS_Cont_Act_St_HV_Neg "null";
BA_ "sigSecLevel" SG_ 751 BMS_Cont_Act_St_HV_Neg "null";
BA_ "sigConfig" SG_ 751 BMS_Cont_Tar_St_HV_Neg "null";
BA_ "sigExplanation" SG_ 751 BMS_Cont_Tar_St_HV_Neg "null";
BA_ "sigSecLevel" SG_ 751 BMS_Cont_Tar_St_HV_Neg "null";
BA_ "sigConfig" SG_ 751 BMS_Cont_Coil_I_HV_Neg "null";
BA_ "sigExplanation" SG_ 751 BMS_Cont_Coil_I_HV_Neg "null";
BA_ "sigSecLevel" SG_ 751 BMS_Cont_Coil_I_HV_Neg "null";
BA_ "sigConfig" SG_ 751 BMS_Cont_WearCounter_HV_Neg "null";
BA_ "sigExplanation" SG_ 751 BMS_Cont_WearCounter_HV_Neg "null";
BA_ "sigSecLevel" SG_ 751 BMS_Cont_WearCounter_HV_Neg "null";
BA_ "sigConfig" SG_ 752 BMS_Cont_Act_St_HV_Prec "null";
BA_ "sigExplanation" SG_ 752 BMS_Cont_Act_St_HV_Prec "null";
BA_ "sigSecLevel" SG_ 752 BMS_Cont_Act_St_HV_Prec "null";
BA_ "sigConfig" SG_ 752 BMS_Cont_Tar_St_HV_Prec "null";
BA_ "sigExplanation" SG_ 752 BMS_Cont_Tar_St_HV_Prec "null";
BA_ "sigSecLevel" SG_ 752 BMS_Cont_Tar_St_HV_Prec "null";
BA_ "sigConfig" SG_ 752 BMS_Cont_Coil_I_HV_Prec "null";
BA_ "sigExplanation" SG_ 752 BMS_Cont_Coil_I_HV_Prec "null";
BA_ "sigSecLevel" SG_ 752 BMS_Cont_Coil_I_HV_Prec "null";
BA_ "sigConfig" SG_ 752 BMS_Cont_WearCounter_HV_Prec "null";
BA_ "sigExplanation" SG_ 752 BMS_Cont_WearCounter_HV_Prec "null";
BA_ "sigSecLevel" SG_ 752 BMS_Cont_WearCounter_HV_Prec "null";
BA_ "sigConfig" SG_ 755 BMS_Error_Flag_CheckSum "null";
BA_ "sigExplanation" SG_ 755 BMS_Error_Flag_CheckSum "null";
BA_ "sigSecLevel" SG_ 755 BMS_Error_Flag_CheckSum "null";
BA_ "sigConfig" SG_ 755 BMS_Error_Flag_AliveCounter "null";
BA_ "sigExplanation" SG_ 755 BMS_Error_Flag_AliveCounter "null";
BA_ "sigSecLevel" SG_ 755 BMS_Error_Flag_AliveCounter "null";
BA_ "sigConfig" SG_ 755 BMS_ErrorWarning_CellVoltageDiff "null";
BA_ "sigExplanation" SG_ 755 BMS_ErrorWarning_CellVoltageDiff "null";
BA_ "sigSecLevel" SG_ 755 BMS_ErrorWarning_CellVoltageDiff "null";
BA_ "SystemSignalLongSymbol" SG_ 755 BMS_ErrorWarning_CellVoltageDiff "BMS_ErrorWarning_CellVoltageDiffOverLim";
BA_ "sigConfig" SG_ 755 BMS_ErrorActive_CellVoltageDiffO "null";
BA_ "sigExplanation" SG_ 755 BMS_ErrorActive_CellVoltageDiffO "null";
BA_ "sigSecLevel" SG_ 755 BMS_ErrorActive_CellVoltageDiffO "null";
BA_ "SystemSignalLongSymbol" SG_ 755 BMS_ErrorActive_CellVoltageDiffO "BMS_ErrorActive_CellVoltageDiffOverLim";
BA_ "sigConfig" SG_ 755 BMS_ErrorWarning_Diff_U1_UCellSu "null";
BA_ "sigExplanation" SG_ 755 BMS_ErrorWarning_Diff_U1_UCellSu "null";
BA_ "sigSecLevel" SG_ 755 BMS_ErrorWarning_Diff_U1_UCellSu "null";
BA_ "SystemSignalLongSymbol" SG_ 755 BMS_ErrorWarning_Diff_U1_UCellSu "BMS_ErrorWarning_Diff_U1_UCellSum";
BA_ "sigConfig" SG_ 755 BMS_ErrorActive_Diff_U1_UCellSum "null";
BA_ "sigExplanation" SG_ 755 BMS_ErrorActive_Diff_U1_UCellSum "null";
BA_ "sigSecLevel" SG_ 755 BMS_ErrorActive_Diff_U1_UCellSum "null";
BA_ "sigConfig" SG_ 755 BMS_ErrorWarning_SOH_Low "null";
BA_ "sigExplanation" SG_ 755 BMS_ErrorWarning_SOH_Low "null";
BA_ "sigSecLevel" SG_ 755 BMS_ErrorWarning_SOH_Low "null";
BA_ "sigConfig" SG_ 755 BMS_ErrorActive_SOH_Low "null";
BA_ "sigExplanation" SG_ 755 BMS_ErrorActive_SOH_Low "null";
BA_ "sigSecLevel" SG_ 755 BMS_ErrorActive_SOH_Low "null";
BA_ "sigConfig" SG_ 755 BMS_SystemError_SystemInitFailed "null";
BA_ "sigExplanation" SG_ 755 BMS_SystemError_SystemInitFailed "null";
BA_ "sigSecLevel" SG_ 755 BMS_SystemError_SystemInitFailed "null";
BA_ "sigConfig" SG_ 755 BMS_SystemError_Precharge "null";
BA_ "sigExplanation" SG_ 755 BMS_SystemError_Precharge "null";
BA_ "sigSecLevel" SG_ 755 BMS_SystemError_Precharge "null";
BA_ "sigConfig" SG_ 755 BMS_SystemError_HV_CCT_WrongPola "null";
BA_ "sigExplanation" SG_ 755 BMS_SystemError_HV_CCT_WrongPola "null";
BA_ "sigSecLevel" SG_ 755 BMS_SystemError_HV_CCT_WrongPola "null";
BA_ "SystemSignalLongSymbol" SG_ 755 BMS_SystemError_HV_CCT_WrongPola "BMS_SystemError_HV_CCT_WrongPolarity";
BA_ "sigConfig" SG_ 755 BMS_SystemError_HV_CCT_NoBatVolt "null";
BA_ "sigExplanation" SG_ 755 BMS_SystemError_HV_CCT_NoBatVolt "null";
BA_ "sigSecLevel" SG_ 755 BMS_SystemError_HV_CCT_NoBatVolt "null";
BA_ "SystemSignalLongSymbol" SG_ 755 BMS_SystemError_HV_CCT_NoBatVolt "BMS_SystemError_HV_CCT_NoBatVoltage";
BA_ "sigConfig" SG_ 755 BMS_HVlinkWarning_VCU_MessageInt "null";
BA_ "sigExplanation" SG_ 755 BMS_HVlinkWarning_VCU_MessageInt "null";
BA_ "sigSecLevel" SG_ 755 BMS_HVlinkWarning_VCU_MessageInt "null";
BA_ "SystemSignalLongSymbol" SG_ 755 BMS_HVlinkWarning_VCU_MessageInt "BMS_HVlinkWarning_VCU_MessageIntegrity";
BA_ "sigConfig" SG_ 755 BMS_HVlinkError_IVT_Comm_Failure "null";
BA_ "sigExplanation" SG_ 755 BMS_HVlinkError_IVT_Comm_Failure "null";
BA_ "sigSecLevel" SG_ 755 BMS_HVlinkError_IVT_Comm_Failure "null";
BA_ "sigConfig" SG_ 755 BMS_HVlinkWarning_IVT_Meas_Failu "null";
BA_ "sigExplanation" SG_ 755 BMS_HVlinkWarning_IVT_Meas_Failu "null";
BA_ "sigSecLevel" SG_ 755 BMS_HVlinkWarning_IVT_Meas_Failu "null";
BA_ "SystemSignalLongSymbol" SG_ 755 BMS_HVlinkWarning_IVT_Meas_Failu "BMS_HVlinkWarning_IVT_Meas_Failure";
BA_ "sigConfig" SG_ 755 BMS_HVlinkError_IVT_Meas_Failure "null";
BA_ "sigExplanation" SG_ 755 BMS_HVlinkError_IVT_Meas_Failure "null";
BA_ "sigSecLevel" SG_ 755 BMS_HVlinkError_IVT_Meas_Failure "null";
BA_ "sigConfig" SG_ 755 BMS_HVlinkError_NVM_Comm_Failure "null";
BA_ "sigExplanation" SG_ 755 BMS_HVlinkError_NVM_Comm_Failure "null";
BA_ "sigSecLevel" SG_ 755 BMS_HVlinkError_NVM_Comm_Failure "null";
BA_ "sigConfig" SG_ 755 BMS_HVlinkWarning_Eeprom_LifeCyc "null";
BA_ "sigExplanation" SG_ 755 BMS_HVlinkWarning_Eeprom_LifeCyc "null";
BA_ "sigSecLevel" SG_ 755 BMS_HVlinkWarning_Eeprom_LifeCyc "null";
BA_ "SystemSignalLongSymbol" SG_ 755 BMS_HVlinkWarning_Eeprom_LifeCyc "BMS_HVlinkWarning_Eeprom_LifeCycleCount";
BA_ "sigConfig" SG_ 755 BMS_HVlinkError_Eeprom_LifeCycle "null";
BA_ "sigExplanation" SG_ 755 BMS_HVlinkError_Eeprom_LifeCycle "null";
BA_ "sigSecLevel" SG_ 755 BMS_HVlinkError_Eeprom_LifeCycle "null";
BA_ "SystemSignalLongSymbol" SG_ 755 BMS_HVlinkError_Eeprom_LifeCycle "BMS_HVlinkError_Eeprom_LifeCycleCount";
BA_ "sigConfig" SG_ 755 BMS_HVlinkError_ContactorGeneric "null";
BA_ "sigExplanation" SG_ 755 BMS_HVlinkError_ContactorGeneric "null";
BA_ "sigSecLevel" SG_ 755 BMS_HVlinkError_ContactorGeneric "null";
BA_ "sigConfig" SG_ 755 BMS_HVlinkError_ContactorOpen "null";
BA_ "sigExplanation" SG_ 755 BMS_HVlinkError_ContactorOpen "null";
BA_ "sigSecLevel" SG_ 755 BMS_HVlinkError_ContactorOpen "null";
BA_ "sigConfig" SG_ 755 BMS_HVlinkError_ContactorAuxFail "null";
BA_ "sigExplanation" SG_ 755 BMS_HVlinkError_ContactorAuxFail "null";
BA_ "sigSecLevel" SG_ 755 BMS_HVlinkError_ContactorAuxFail "null";
BA_ "SystemSignalLongSymbol" SG_ 755 BMS_HVlinkError_ContactorAuxFail "BMS_HVlinkError_ContactorAuxFailed";
BA_ "sigConfig" SG_ 755 BMS_HVlinkError_ContactorPwmEcon "null";
BA_ "sigExplanation" SG_ 755 BMS_HVlinkError_ContactorPwmEcon "null";
BA_ "sigSecLevel" SG_ 755 BMS_HVlinkError_ContactorPwmEcon "null";
BA_ "SystemSignalLongSymbol" SG_ 755 BMS_HVlinkError_ContactorPwmEcon "BMS_HVlinkError_ContactorPwmEconomizer";
BA_ "sigConfig" SG_ 755 BMS_HVlinkWarning_AnalogInput_Ex "null";
BA_ "sigExplanation" SG_ 755 BMS_HVlinkWarning_AnalogInput_Ex "null";
BA_ "sigSecLevel" SG_ 755 BMS_HVlinkWarning_AnalogInput_Ex "null";
BA_ "SystemSignalLongSymbol" SG_ 755 BMS_HVlinkWarning_AnalogInput_Ex "BMS_HVlinkWarning_AnalogInput_Exceed_Lim";
BA_ "sigConfig" SG_ 755 BMS_HVlinkError_AnalogInput_Exce "null";
BA_ "sigExplanation" SG_ 755 BMS_HVlinkError_AnalogInput_Exce "null";
BA_ "sigSecLevel" SG_ 755 BMS_HVlinkError_AnalogInput_Exce "null";
BA_ "SystemSignalLongSymbol" SG_ 755 BMS_HVlinkError_AnalogInput_Exce "BMS_HVlinkError_AnalogInput_Exceed_Lim";
BA_ "sigConfig" SG_ 755 BMS_HWerror_KL30_Voltage "null";
BA_ "sigExplanation" SG_ 755 BMS_HWerror_KL30_Voltage "null";
BA_ "sigSecLevel" SG_ 755 BMS_HWerror_KL30_Voltage "null";
BA_ "sigConfig" SG_ 755 BMS_HWerror_SD_Voltage "null";
BA_ "sigExplanation" SG_ 755 BMS_HWerror_SD_Voltage "null";
BA_ "sigSecLevel" SG_ 755 BMS_HWerror_SD_Voltage "null";
BA_ "sigConfig" SG_ 755 BMS_HWerror_PCB_Temp_Sensor_Fail "null";
BA_ "sigExplanation" SG_ 755 BMS_HWerror_PCB_Temp_Sensor_Fail "null";
BA_ "sigSecLevel" SG_ 755 BMS_HWerror_PCB_Temp_Sensor_Fail "null";
BA_ "sigConfig" SG_ 755 BMS_HWerror_Cell_Temp_Sensor_Fai "null";
BA_ "sigExplanation" SG_ 755 BMS_HWerror_Cell_Temp_Sensor_Fai "null";
BA_ "sigSecLevel" SG_ 755 BMS_HWerror_Cell_Temp_Sensor_Fai "null";
BA_ "SystemSignalLongSymbol" SG_ 755 BMS_HWerror_Cell_Temp_Sensor_Fai "BMS_HWerror_Cell_Temp_Sensor_Fail";
BA_ "sigConfig" SG_ 755 BMS_HWwarning_LCM_PCB_OverTemp "null";
BA_ "sigExplanation" SG_ 755 BMS_HWwarning_LCM_PCB_OverTemp "null";
BA_ "sigSecLevel" SG_ 755 BMS_HWwarning_LCM_PCB_OverTemp "null";
BA_ "sigConfig" SG_ 755 BMS_HWerror_LCM_PCB_OverTemp "null";
BA_ "sigExplanation" SG_ 755 BMS_HWerror_LCM_PCB_OverTemp "null";
BA_ "sigSecLevel" SG_ 755 BMS_HWerror_LCM_PCB_OverTemp "null";
BA_ "sigConfig" SG_ 755 BMS_HWwarning_LCM_PCB_UnderTemp "null";
BA_ "sigExplanation" SG_ 755 BMS_HWwarning_LCM_PCB_UnderTemp "null";
BA_ "sigSecLevel" SG_ 755 BMS_HWwarning_LCM_PCB_UnderTemp "null";
BA_ "sigConfig" SG_ 755 BMS_HWerror_LCM_PCB_UnderTemp "null";
BA_ "sigExplanation" SG_ 755 BMS_HWerror_LCM_PCB_UnderTemp "null";
BA_ "sigSecLevel" SG_ 755 BMS_HWerror_LCM_PCB_UnderTemp "null";
BA_ "sigConfig" SG_ 755 BMS_Software_Error_Boot_Faild "null";
BA_ "sigExplanation" SG_ 755 BMS_Software_Error_Boot_Faild "null";
BA_ "sigSecLevel" SG_ 755 BMS_Software_Error_Boot_Faild "null";
BA_ "sigConfig" SG_ 755 BMS_DTC_status "null";
BA_ "sigExplanation" SG_ 755 BMS_DTC_status "null";
BA_ "sigSecLevel" SG_ 755 BMS_DTC_status "null";
BA_ "sigConfig" SG_ 756 BMS_Bat_measure_Coulomb_Ctr "null";
BA_ "sigExplanation" SG_ 756 BMS_Bat_measure_Coulomb_Ctr "null";
BA_ "sigSecLevel" SG_ 756 BMS_Bat_measure_Coulomb_Ctr "null";
BA_ "sigConfig" SG_ 756 BMS_Bat_measure_Energy "null";
BA_ "sigExplanation" SG_ 756 BMS_Bat_measure_Energy "null";
BA_ "sigSecLevel" SG_ 756 BMS_Bat_measure_Energy "null";
BA_ "GenSigStartValue" SG_ 756 BMS_Bat_measure_Power 7000;
BA_ "sigConfig" SG_ 756 BMS_Bat_measure_Power "null";
BA_ "sigExplanation" SG_ 756 BMS_Bat_measure_Power "null";
BA_ "sigSecLevel" SG_ 756 BMS_Bat_measure_Power "null";
BA_ "GenSigStartValue" SG_ 756 BMS_Bat_Bus_measure_Temperature 55;
BA_ "sigConfig" SG_ 756 BMS_Bat_Bus_measure_Temperature "null";
BA_ "sigExplanation" SG_ 756 BMS_Bat_Bus_measure_Temperature "null";
BA_ "sigSecLevel" SG_ 756 BMS_Bat_Bus_measure_Temperature "null";
BA_ "sigConfig" SG_ 757 BMS_Bat_SoC_usable "null";
BA_ "sigExplanation" SG_ 757 BMS_Bat_SoC_usable "null";
BA_ "sigSecLevel" SG_ 757 BMS_Bat_SoC_usable "null";
BA_ "sigConfig" SG_ 757 BMS_Bat_Actual_Pack_Capacity "null";
BA_ "sigExplanation" SG_ 757 BMS_Bat_Actual_Pack_Capacity "null";
BA_ "sigSecLevel" SG_ 757 BMS_Bat_Actual_Pack_Capacity "null";
BA_ "sigConfig" SG_ 757 BMS_Bat_SOH "null";
BA_ "sigExplanation" SG_ 757 BMS_Bat_SOH "null";
BA_ "sigSecLevel" SG_ 757 BMS_Bat_SOH "null";
BA_ "sigConfig" SG_ 758 BMS_Curr_PLT_CheckSum "null";
BA_ "sigExplanation" SG_ 758 BMS_Curr_PLT_CheckSum "null";
BA_ "sigSecLevel" SG_ 758 BMS_Curr_PLT_CheckSum "null";
BA_ "sigConfig" SG_ 758 BMS_Curr_PLT_AliveCounter "null";
BA_ "sigExplanation" SG_ 758 BMS_Curr_PLT_AliveCounter "null";
BA_ "sigSecLevel" SG_ 758 BMS_Curr_PLT_AliveCounter "null";
BA_ "sigConfig" SG_ 758 BMS_Bat_D_MAXcurr_PLT "null";
BA_ "sigExplanation" SG_ 758 BMS_Bat_D_MAXcurr_PLT "null";
BA_ "sigSecLevel" SG_ 758 BMS_Bat_D_MAXcurr_PLT "A(B)";
BA_ "sigConfig" SG_ 758 BMS_Bat_C_MAXcurr_PLT "null";
BA_ "sigExplanation" SG_ 758 BMS_Bat_C_MAXcurr_PLT "null";
BA_ "sigSecLevel" SG_ 758 BMS_Bat_C_MAXcurr_PLT "B";
BA_ "sigConfig" SG_ 759 BMS_Bat_C_MaxCell_U "null";
BA_ "sigExplanation" SG_ 759 BMS_Bat_C_MaxCell_U "null";
BA_ "sigSecLevel" SG_ 759 BMS_Bat_C_MaxCell_U "null";
BA_ "sigConfig" SG_ 759 BMS_Bat_D_MinCell_U "null";
BA_ "sigExplanation" SG_ 759 BMS_Bat_D_MinCell_U "null";
BA_ "sigSecLevel" SG_ 759 BMS_Bat_D_MinCell_U "B";
BA_ "sigConfig" SG_ 759 BMS_Bat_D_MaxPack_I "null";
BA_ "sigExplanation" SG_ 759 BMS_Bat_D_MaxPack_I "null";
BA_ "sigSecLevel" SG_ 759 BMS_Bat_D_MaxPack_I "A(B)";
BA_ "sigConfig" SG_ 759 BMS_Bat_C_MaxPack_I "null";
BA_ "sigExplanation" SG_ 759 BMS_Bat_C_MaxPack_I "null";
BA_ "sigSecLevel" SG_ 759 BMS_Bat_C_MaxPack_I "A(B)";
BA_ "sigConfig" SG_ 760 BMS_Volt_PLT_CheckSum "null";
BA_ "sigExplanation" SG_ 760 BMS_Volt_PLT_CheckSum "null";
BA_ "sigSecLevel" SG_ 760 BMS_Volt_PLT_CheckSum "null";
BA_ "sigConfig" SG_ 760 BMS_Volt_PLT_AliveCounter "null";
BA_ "sigExplanation" SG_ 760 BMS_Volt_PLT_AliveCounter "null";
BA_ "sigSecLevel" SG_ 760 BMS_Volt_PLT_AliveCounter "null";
BA_ "sigConfig" SG_ 760 BMS_Bat_C_MAXvolt_PLT "null";
BA_ "sigExplanation" SG_ 760 BMS_Bat_C_MAXvolt_PLT "null";
BA_ "sigSecLevel" SG_ 760 BMS_Bat_C_MAXvolt_PLT "null";
BA_ "sigConfig" SG_ 760 BMS_Bat_D_MAXvolt_PLT "null";
BA_ "sigExplanation" SG_ 760 BMS_Bat_D_MAXvolt_PLT "null";
BA_ "sigSecLevel" SG_ 760 BMS_Bat_D_MAXvolt_PLT "null";
BA_ "sigConfig" SG_ 761 BMS_Bat_C_MaxPack_U "null";
BA_ "sigExplanation" SG_ 761 BMS_Bat_C_MaxPack_U "null";
BA_ "sigSecLevel" SG_ 761 BMS_Bat_C_MaxPack_U "A(B)";
BA_ "sigConfig" SG_ 761 BMS_Bat_D_MinPack_U "null";
BA_ "sigExplanation" SG_ 761 BMS_Bat_D_MinPack_U "null";
BA_ "sigSecLevel" SG_ 761 BMS_Bat_D_MinPack_U "null";
BA_ "sigConfig" SG_ 767 VCU_2FF_CheckSum "null";
BA_ "sigExplanation" SG_ 767 VCU_2FF_CheckSum "null";
BA_ "sigSecLevel" SG_ 767 VCU_2FF_CheckSum "null";
BA_ "sigConfig" SG_ 767 VCU_2FF_AliveCounter "null";
BA_ "sigExplanation" SG_ 767 VCU_2FF_AliveCounter "null";
BA_ "sigSecLevel" SG_ 767 VCU_2FF_AliveCounter "null";
BA_ "GenSigStartValue" SG_ 767 VCU_ACC_PA_MinA 32773;
BA_ "sigConfig" SG_ 785 ADAS_311_CheckSum "null";
BA_ "sigExplanation" SG_ 785 ADAS_311_CheckSum "null";
BA_ "sigSecLevel" SG_ 785 ADAS_311_CheckSum "null";
BA_ "sigConfig" SG_ 785 ADAS_311_AliveCounter "null";
BA_ "sigExplanation" SG_ 785 ADAS_311_AliveCounter "null";
BA_ "sigSecLevel" SG_ 785 ADAS_311_AliveCounter "null";
BA_ "sigConfig" SG_ 785 ADAS_HiPrioDegradationSts "null";
BA_ "sigExplanation" SG_ 785 ADAS_HiPrioDegradationSts "null";
BA_ "sigSecLevel" SG_ 785 ADAS_HiPrioDegradationSts "null";
BA_ "sigConfig" SG_ 785 ADAS_LoPrioDegradationSts "null";
BA_ "sigExplanation" SG_ 785 ADAS_LoPrioDegradationSts "null";
BA_ "sigSecLevel" SG_ 785 ADAS_LoPrioDegradationSts "null";
BA_ "sigConfig" SG_ 785 ADAS_SpeedLimitUnit "null";
BA_ "sigExplanation" SG_ 785 ADAS_SpeedLimitUnit "null";
BA_ "sigSecLevel" SG_ 785 ADAS_SpeedLimitUnit "null";
BA_ "sigConfig" SG_ 785 ADAS_ISA_SpdLmt "null";
BA_ "sigExplanation" SG_ 785 ADAS_ISA_SpdLmt "null";
BA_ "sigSecLevel" SG_ 785 ADAS_ISA_SpdLmt "null";
BA_ "sigConfig" SG_ 785 ADAS_TSRSpeedLimitAddOn "null";
BA_ "sigExplanation" SG_ 785 ADAS_TSRSpeedLimitAddOn "null";
BA_ "sigSecLevel" SG_ 785 ADAS_TSRSpeedLimitAddOn "null";
BA_ "sigConfig" SG_ 785 ADAS_TSRSpeedLimit "null";
BA_ "sigExplanation" SG_ 785 ADAS_TSRSpeedLimit "null";
BA_ "sigSecLevel" SG_ 785 ADAS_TSRSpeedLimit "null";
BA_ "sigConfig" SG_ 792 ESP_318_CheckSum "null";
BA_ "sigExplanation" SG_ 792 ESP_318_CheckSum "null";
BA_ "sigSecLevel" SG_ 792 ESP_318_CheckSum "null";
BA_ "sigConfig" SG_ 792 ESP_318_AliveCounter "null";
BA_ "sigExplanation" SG_ 792 ESP_318_AliveCounter "null";
BA_ "sigSecLevel" SG_ 792 ESP_318_AliveCounter "null";
BA_ "sigConfig" SG_ 792 ESP_BrkPedlStsVld "null";
BA_ "sigExplanation" SG_ 792 ESP_BrkPedlStsVld "null";
BA_ "sigSecLevel" SG_ 792 ESP_BrkPedlStsVld "C";
BA_ "sigConfig" SG_ 792 ESP_BrkPedlSts "null";
BA_ "sigExplanation" SG_ 792 ESP_BrkPedlSts "null";
BA_ "sigSecLevel" SG_ 792 ESP_BrkPedlSts "C";
BA_ "sigConfig" SG_ 792 ESP_VehSpdVld "null";
BA_ "sigExplanation" SG_ 792 ESP_VehSpdVld "null";
BA_ "sigSecLevel" SG_ 792 ESP_VehSpdVld "B";
BA_ "sigConfig" SG_ 792 ESP_SysActv "null";
BA_ "sigExplanation" SG_ 792 ESP_SysActv "null";
BA_ "sigSecLevel" SG_ 792 ESP_SysActv "null";
BA_ "sigConfig" SG_ 792 ESP_LampSwtOffIndcn "null";
BA_ "sigExplanation" SG_ 792 ESP_LampSwtOffIndcn "null";
BA_ "sigSecLevel" SG_ 792 ESP_LampSwtOffIndcn "null";
BA_ "sigConfig" SG_ 792 ESP_FltIndcn_EBD "null";
BA_ "sigExplanation" SG_ 792 ESP_FltIndcn_EBD "null";
BA_ "sigSecLevel" SG_ 792 ESP_FltIndcn_EBD "null";
BA_ "sigConfig" SG_ 792 ESP_FltIndcn_ABS "null";
BA_ "sigExplanation" SG_ 792 ESP_FltIndcn_ABS "null";
BA_ "sigSecLevel" SG_ 792 ESP_FltIndcn_ABS "B";
BA_ "sigConfig" SG_ 792 ESP_MilgRollgCntr_ODO "null";
BA_ "sigExplanation" SG_ 792 ESP_MilgRollgCntr_ODO "null";
BA_ "sigSecLevel" SG_ 792 ESP_MilgRollgCntr_ODO "null";
BA_ "sigConfig" SG_ 792 ESP_VehSpd "null";
BA_ "sigExplanation" SG_ 792 ESP_VehSpd "null";
BA_ "sigSecLevel" SG_ 792 ESP_VehSpd "B";
BA_ "sigConfig" SG_ 792 ESP_IninModSigIndcn "null";
BA_ "sigExplanation" SG_ 792 ESP_IninModSigIndcn "null";
BA_ "sigSecLevel" SG_ 792 ESP_IninModSigIndcn "null";
BA_ "sigConfig" SG_ 792 ESP_FltIndcn_TCS "null";
BA_ "sigExplanation" SG_ 792 ESP_FltIndcn_TCS "null";
BA_ "sigSecLevel" SG_ 792 ESP_FltIndcn_TCS "B";
BA_ "sigConfig" SG_ 792 ESP_CtrlSts_HDC "null";
BA_ "sigExplanation" SG_ 792 ESP_CtrlSts_HDC "null";
BA_ "sigSecLevel" SG_ 792 ESP_CtrlSts_HDC "null";
BA_ "sigConfig" SG_ 792 ESP_AvlIndcn_HDC "null";
BA_ "sigExplanation" SG_ 792 ESP_AvlIndcn_HDC "null";
BA_ "sigSecLevel" SG_ 792 ESP_AvlIndcn_HDC "null";
BA_ "sigConfig" SG_ 792 ESP_NoBrkP "null";
BA_ "sigExplanation" SG_ 792 ESP_NoBrkP "null";
BA_ "sigSecLevel" SG_ 792 ESP_NoBrkP "null";
BA_ "sigConfig" SG_ 792 ESP_RDAEnaFlg "null";
BA_ "sigExplanation" SG_ 792 ESP_RDAEnaFlg "null";
BA_ "sigSecLevel" SG_ 792 ESP_RDAEnaFlg "null";
BA_ "sigConfig" SG_ 816 BMS_330_391_CheckSum "null";
BA_ "sigExplanation" SG_ 816 BMS_330_391_CheckSum "null";
BA_ "sigSecLevel" SG_ 816 BMS_330_391_CheckSum "null";
BA_ "sigConfig" SG_ 816 BMS_330_391_AliveCounter "null";
BA_ "sigExplanation" SG_ 816 BMS_330_391_AliveCounter "null";
BA_ "sigSecLevel" SG_ 816 BMS_330_391_AliveCounter "null";
BA_ "sigConfig" SG_ 816 BMS_VehInsulFltDisp "null";
BA_ "sigExplanation" SG_ 816 BMS_VehInsulFltDisp "null";
BA_ "sigSecLevel" SG_ 816 BMS_VehInsulFltDisp "null";
BA_ "sigConfig" SG_ 816 BMS_PwrBattSysFltDisp "null";
BA_ "sigExplanation" SG_ 816 BMS_PwrBattSysFltDisp "null";
BA_ "sigSecLevel" SG_ 816 BMS_PwrBattSysFltDisp "null";
BA_ "sigConfig" SG_ 816 BMS_PwrBattRmngCpSOC "null";
BA_ "sigExplanation" SG_ 816 BMS_PwrBattRmngCpSOC "null";
BA_ "sigSecLevel" SG_ 816 BMS_PwrBattRmngCpSOC "null";
BA_ "sigConfig" SG_ 816 BMS_PwrBattAvlCp "null";
BA_ "sigExplanation" SG_ 816 BMS_PwrBattAvlCp "null";
BA_ "sigSecLevel" SG_ 816 BMS_PwrBattAvlCp "null";
BA_ "sigConfig" SG_ 816 BMS_CellMinTAlrm "null";
BA_ "sigExplanation" SG_ 816 BMS_CellMinTAlrm "null";
BA_ "sigSecLevel" SG_ 816 BMS_CellMinTAlrm "null";
BA_ "sigConfig" SG_ 816 BMS_PwrBattThermRunawayAlrm "null";
BA_ "sigExplanation" SG_ 816 BMS_PwrBattThermRunawayAlrm "null";
BA_ "sigSecLevel" SG_ 816 BMS_PwrBattThermRunawayAlrm "null";
BA_ "sigConfig" SG_ 816 BMS_PwrBattOverT "null";
BA_ "sigExplanation" SG_ 816 BMS_PwrBattOverT "null";
BA_ "sigSecLevel" SG_ 816 BMS_PwrBattOverT "null";
BA_ "sigConfig" SG_ 816 BMS_PwrBattInsulSts "null";
BA_ "sigExplanation" SG_ 816 BMS_PwrBattInsulSts "null";
BA_ "sigSecLevel" SG_ 816 BMS_PwrBattInsulSts "null";
BA_ "sigConfig" SG_ 816 BMS_330_SSecOC_Fresh_Byte0 "null";
BA_ "sigExplanation" SG_ 816 BMS_330_SSecOC_Fresh_Byte0 "null";
BA_ "sigSecLevel" SG_ 816 BMS_330_SSecOC_Fresh_Byte0 "null";
BA_ "sigConfig" SG_ 816 BMS_330_SSecOC_MAC_Byte0 "null";
BA_ "sigExplanation" SG_ 816 BMS_330_SSecOC_MAC_Byte0 "null";
BA_ "sigSecLevel" SG_ 816 BMS_330_SSecOC_MAC_Byte0 "null";
BA_ "sigConfig" SG_ 816 BMS_330_SSecOC_MAC_Byte1 "null";
BA_ "sigExplanation" SG_ 816 BMS_330_SSecOC_MAC_Byte1 "null";
BA_ "sigSecLevel" SG_ 816 BMS_330_SSecOC_MAC_Byte1 "null";
BA_ "sigConfig" SG_ 816 BMS_330_SSecOC_MAC_Byte2 "null";
BA_ "sigExplanation" SG_ 816 BMS_330_SSecOC_MAC_Byte2 "null";
BA_ "sigSecLevel" SG_ 816 BMS_330_SSecOC_MAC_Byte2 "null";
BA_ "sigConfig" SG_ 817 PKC_331_CheckSum "null";
BA_ "sigExplanation" SG_ 817 PKC_331_CheckSum "null";
BA_ "sigSecLevel" SG_ 817 PKC_331_CheckSum "null";
BA_ "sigConfig" SG_ 817 PKC_331_AliveCounter "null";
BA_ "sigExplanation" SG_ 817 PKC_331_AliveCounter "null";
BA_ "sigSecLevel" SG_ 817 PKC_331_AliveCounter "null";
BA_ "sigConfig" SG_ 817 PKC_RemReqCfmRxResp "null";
BA_ "sigExplanation" SG_ 817 PKC_RemReqCfmRxResp "null";
BA_ "sigSecLevel" SG_ 817 PKC_RemReqCfmRxResp "null";
BA_ "sigConfig" SG_ 817 PKC_SysLrngMod "null";
BA_ "sigExplanation" SG_ 817 PKC_SysLrngMod "null";
BA_ "sigSecLevel" SG_ 817 PKC_SysLrngMod "null";
BA_ "GenSigSendType" SG_ 817 PKC_StrtReq 4;
BA_ "sigConfig" SG_ 817 PKC_StrtReq "null";
BA_ "sigExplanation" SG_ 817 PKC_StrtReq "null";
BA_ "sigSecLevel" SG_ 817 PKC_StrtReq "null";
BA_ "sigConfig" SG_ 817 PKC_IMMO_AuthSts "null";
BA_ "sigExplanation" SG_ 817 PKC_IMMO_AuthSts "null";
BA_ "sigSecLevel" SG_ 817 PKC_IMMO_AuthSts "null";
BA_ "sigConfig" SG_ 817 PKC_RemModOpenSts "null";
BA_ "sigExplanation" SG_ 817 PKC_RemModOpenSts "null";
BA_ "sigSecLevel" SG_ 817 PKC_RemModOpenSts "null";
BA_ "sigConfig" SG_ 817 PKC_331_SSecOC_Fresh_Byte0 "null";
BA_ "sigExplanation" SG_ 817 PKC_331_SSecOC_Fresh_Byte0 "null";
BA_ "sigSecLevel" SG_ 817 PKC_331_SSecOC_Fresh_Byte0 "null";
BA_ "sigConfig" SG_ 817 PKC_331_SSecOC_MAC_Byte0 "null";
BA_ "sigExplanation" SG_ 817 PKC_331_SSecOC_MAC_Byte0 "null";
BA_ "sigSecLevel" SG_ 817 PKC_331_SSecOC_MAC_Byte0 "null";
BA_ "sigConfig" SG_ 817 PKC_331_SSecOC_MAC_Byte1 "null";
BA_ "sigExplanation" SG_ 817 PKC_331_SSecOC_MAC_Byte1 "null";
BA_ "sigSecLevel" SG_ 817 PKC_331_SSecOC_MAC_Byte1 "null";
BA_ "sigConfig" SG_ 817 PKC_331_SSecOC_MAC_Byte2 "null";
BA_ "sigExplanation" SG_ 817 PKC_331_SSecOC_MAC_Byte2 "null";
BA_ "sigSecLevel" SG_ 817 PKC_331_SSecOC_MAC_Byte2 "null";
BA_ "sigConfig" SG_ 819 BCM_333_CheckSum "null";
BA_ "sigExplanation" SG_ 819 BCM_333_CheckSum "null";
BA_ "sigSecLevel" SG_ 819 BCM_333_CheckSum "null";
BA_ "sigConfig" SG_ 819 BCM_333_AliveCounter "null";
BA_ "sigExplanation" SG_ 819 BCM_333_AliveCounter "null";
BA_ "sigSecLevel" SG_ 819 BCM_333_AliveCounter "null";
BA_ "sigConfig" SG_ 819 BCM_KL15_Off_Announcement "null";
BA_ "sigExplanation" SG_ 819 BCM_KL15_Off_Announcement "null";
BA_ "sigSecLevel" SG_ 819 BCM_KL15_Off_Announcement "null";
BA_ "sigConfig" SG_ 819 BCM_IG1Sts "null";
BA_ "sigExplanation" SG_ 819 BCM_IG1Sts "null";
BA_ "sigSecLevel" SG_ 819 BCM_IG1Sts "null";
BA_ "sigConfig" SG_ 819 BCM_PwrMod "null";
BA_ "sigExplanation" SG_ 819 BCM_PwrMod "null";
BA_ "sigSecLevel" SG_ 819 BCM_PwrMod "B";
BA_ "sigConfig" SG_ 819 BCM_PwrModVld "null";
BA_ "sigExplanation" SG_ 819 BCM_PwrModVld "null";
BA_ "sigSecLevel" SG_ 819 BCM_PwrModVld "B";
BA_ "sigConfig" SG_ 819 BCM_BrkSwtSts "null";
BA_ "sigExplanation" SG_ 819 BCM_BrkSwtSts "null";
BA_ "sigSecLevel" SG_ 819 BCM_BrkSwtSts "null";
BA_ "sigConfig" SG_ 819 BCM_IG1StsVld_CAPE "null";
BA_ "sigExplanation" SG_ 819 BCM_IG1StsVld_CAPE "null";
BA_ "sigSecLevel" SG_ 819 BCM_IG1StsVld_CAPE "null";
BA_ "sigConfig" SG_ 819 BCM_IG2StsVld_CAPE "null";
BA_ "sigExplanation" SG_ 819 BCM_IG2StsVld_CAPE "null";
BA_ "sigSecLevel" SG_ 819 BCM_IG2StsVld_CAPE "null";
BA_ "sigConfig" SG_ 819 BCM_KL30s_L "null";
BA_ "sigExplanation" SG_ 819 BCM_KL30s_L "null";
BA_ "sigSecLevel" SG_ 819 BCM_KL30s_L "null";
BA_ "sigConfig" SG_ 819 BCM_IG2Sts "null";
BA_ "sigExplanation" SG_ 819 BCM_IG2Sts "null";
BA_ "sigSecLevel" SG_ 819 BCM_IG2Sts "null";
BA_ "sigConfig" SG_ 819 BCM_InteriorSwtSt "null";
BA_ "sigExplanation" SG_ 819 BCM_InteriorSwtSt "null";
BA_ "sigSecLevel" SG_ 819 BCM_InteriorSwtSt "null";
BA_ "sigConfig" SG_ 835 BCM_343_CheckSum "null";
BA_ "sigExplanation" SG_ 835 BCM_343_CheckSum "null";
BA_ "sigSecLevel" SG_ 835 BCM_343_CheckSum "null";
BA_ "sigConfig" SG_ 835 BCM_343_AliveCounter "null";
BA_ "sigExplanation" SG_ 835 BCM_343_AliveCounter "null";
BA_ "sigSecLevel" SG_ 835 BCM_343_AliveCounter "null";
BA_ "sigConfig" SG_ 835 BCM_RemReqFb "null";
BA_ "sigExplanation" SG_ 835 BCM_RemReqFb "null";
BA_ "sigSecLevel" SG_ 835 BCM_RemReqFb "null";
BA_ "sigConfig" SG_ 835 BCM_APASwSts "null";
BA_ "sigExplanation" SG_ 835 BCM_APASwSts "null";
BA_ "sigSecLevel" SG_ 835 BCM_APASwSts "null";
BA_ "sigConfig" SG_ 835 BCM_FrntHoodLidSts "null";
BA_ "sigExplanation" SG_ 835 BCM_FrntHoodLidSts "null";
BA_ "sigSecLevel" SG_ 835 BCM_FrntHoodLidSts "null";
BA_ "sigConfig" SG_ 835 BCM_SunroofAntipinchSts "null";
BA_ "sigExplanation" SG_ 835 BCM_SunroofAntipinchSts "null";
BA_ "sigSecLevel" SG_ 835 BCM_SunroofAntipinchSts "null";
BA_ "sigConfig" SG_ 835 BCM_FrntDrDoorLockSts "null";
BA_ "sigExplanation" SG_ 835 BCM_FrntDrDoorLockSts "null";
BA_ "sigSecLevel" SG_ 835 BCM_FrntDrDoorLockSts "null";
BA_ "sigConfig" SG_ 835 BCM_TrRelsSwtSts "null";
BA_ "sigExplanation" SG_ 835 BCM_TrRelsSwtSts "null";
BA_ "sigSecLevel" SG_ 835 BCM_TrRelsSwtSts "null";
BA_ "sigConfig" SG_ 835 BCM_LockAllDoorCmd "null";
BA_ "sigExplanation" SG_ 835 BCM_LockAllDoorCmd "null";
BA_ "sigSecLevel" SG_ 835 BCM_LockAllDoorCmd "null";
BA_ "sigConfig" SG_ 835 BCM_DrFrntDoorSts "null";
BA_ "sigExplanation" SG_ 835 BCM_DrFrntDoorSts "null";
BA_ "sigSecLevel" SG_ 835 BCM_DrFrntDoorSts "B(C)";
BA_ "sigConfig" SG_ 835 BCM_PasFrntDoorSts "null";
BA_ "sigExplanation" SG_ 835 BCM_PasFrntDoorSts "null";
BA_ "sigSecLevel" SG_ 835 BCM_PasFrntDoorSts "B(C)";
BA_ "sigConfig" SG_ 835 BCM_AntithftSts "null";
BA_ "sigExplanation" SG_ 835 BCM_AntithftSts "null";
BA_ "sigSecLevel" SG_ 835 BCM_AntithftSts "null";
BA_ "sigConfig" SG_ 835 BCM_CenLockSwtSts "null";
BA_ "sigExplanation" SG_ 835 BCM_CenLockSwtSts "null";
BA_ "sigSecLevel" SG_ 835 BCM_CenLockSwtSts "null";
BA_ "sigConfig" SG_ 835 BCM_DoorUnlockSetFb "null";
BA_ "sigExplanation" SG_ 835 BCM_DoorUnlockSetFb "null";
BA_ "sigSecLevel" SG_ 835 BCM_DoorUnlockSetFb "null";
BA_ "sigConfig" SG_ 835 BCM_RiReDoorSts "null";
BA_ "sigExplanation" SG_ 835 BCM_RiReDoorSts "null";
BA_ "sigSecLevel" SG_ 835 BCM_RiReDoorSts "B(C)";
BA_ "sigConfig" SG_ 835 BCM_LeReDoorSts "null";
BA_ "sigExplanation" SG_ 835 BCM_LeReDoorSts "null";
BA_ "sigSecLevel" SG_ 835 BCM_LeReDoorSts "B(C)";
BA_ "sigConfig" SG_ 835 BCM_LeFrntWinSts "null";
BA_ "sigExplanation" SG_ 835 BCM_LeFrntWinSts "null";
BA_ "sigSecLevel" SG_ 835 BCM_LeFrntWinSts "null";
BA_ "sigConfig" SG_ 835 BCM_RiFrntWinSts "null";
BA_ "sigExplanation" SG_ 835 BCM_RiFrntWinSts "null";
BA_ "sigSecLevel" SG_ 835 BCM_RiFrntWinSts "null";
BA_ "sigConfig" SG_ 835 BCM_LeReWinSts "null";
BA_ "sigExplanation" SG_ 835 BCM_LeReWinSts "null";
BA_ "sigSecLevel" SG_ 835 BCM_LeReWinSts "null";
BA_ "sigConfig" SG_ 835 BCM_RiReWinSt "null";
BA_ "sigExplanation" SG_ 835 BCM_RiReWinSt "null";
BA_ "sigSecLevel" SG_ 835 BCM_RiReWinSt "null";
BA_ "sigConfig" SG_ 835 BCM_SunroofSts "null";
BA_ "sigExplanation" SG_ 835 BCM_SunroofSts "null";
BA_ "sigSecLevel" SG_ 835 BCM_SunroofSts "null";
BA_ "sigConfig" SG_ 835 BCM_FolwMeSetStsFb "null";
BA_ "sigExplanation" SG_ 835 BCM_FolwMeSetStsFb "null";
BA_ "sigSecLevel" SG_ 835 BCM_FolwMeSetStsFb "null";
BA_ "sigConfig" SG_ 835 BCM_DrvrDoorUnlckOutpCmd "null";
BA_ "sigExplanation" SG_ 835 BCM_DrvrDoorUnlckOutpCmd "null";
BA_ "sigSecLevel" SG_ 835 BCM_DrvrDoorUnlckOutpCmd "null";
BA_ "sigConfig" SG_ 835 BCM_PassDoorUnlckOutpCmd "null";
BA_ "sigExplanation" SG_ 835 BCM_PassDoorUnlckOutpCmd "null";
BA_ "sigSecLevel" SG_ 835 BCM_PassDoorUnlckOutpCmd "null";
BA_ "sigConfig" SG_ 835 BCM_LeDRLOutpCmd "null";
BA_ "sigExplanation" SG_ 835 BCM_LeDRLOutpCmd "null";
BA_ "sigSecLevel" SG_ 835 BCM_LeDRLOutpCmd "null";
BA_ "sigConfig" SG_ 835 BCM_RiDRLOutpCmd "null";
BA_ "sigExplanation" SG_ 835 BCM_RiDRLOutpCmd "null";
BA_ "sigSecLevel" SG_ 835 BCM_RiDRLOutpCmd "null";
BA_ "sigConfig" SG_ 835 BCM_ArmedClsWinSetSts "null";
BA_ "sigExplanation" SG_ 835 BCM_ArmedClsWinSetSts "null";
BA_ "sigSecLevel" SG_ 835 BCM_ArmedClsWinSetSts "null";
BA_ "sigConfig" SG_ 835 BCM_OffAutoUnlckSetSts "null";
BA_ "sigExplanation" SG_ 835 BCM_OffAutoUnlckSetSts "null";
BA_ "sigSecLevel" SG_ 835 BCM_OffAutoUnlckSetSts "null";
BA_ "sigConfig" SG_ 835 BCM_WarnVbrnSts "null";
BA_ "sigExplanation" SG_ 835 BCM_WarnVbrnSts "null";
BA_ "sigSecLevel" SG_ 835 BCM_WarnVbrnSts "null";
BA_ "GenSigStartValue" SG_ 835 BCM_SunroofPosnInfo 127;
BA_ "sigConfig" SG_ 835 BCM_SunroofPosnInfo "null";
BA_ "sigExplanation" SG_ 835 BCM_SunroofPosnInfo "null";
BA_ "sigSecLevel" SG_ 835 BCM_SunroofPosnInfo "null";
BA_ "sigConfig" SG_ 835 BCM_SunroofOpenAr "null";
BA_ "sigExplanation" SG_ 835 BCM_SunroofOpenAr "null";
BA_ "sigSecLevel" SG_ 835 BCM_SunroofOpenAr "null";
BA_ "sigConfig" SG_ 835 BCM_SteerWhlVbrnAlrmAvl "null";
BA_ "sigExplanation" SG_ 835 BCM_SteerWhlVbrnAlrmAvl "null";
BA_ "sigSecLevel" SG_ 835 BCM_SteerWhlVbrnAlrmAvl "null";
BA_ "sigConfig" SG_ 835 BCM_SunroofRunngSts "null";
BA_ "sigExplanation" SG_ 835 BCM_SunroofRunngSts "null";
BA_ "sigSecLevel" SG_ 835 BCM_SunroofRunngSts "null";
BA_ "sigConfig" SG_ 835 BCM_MirrCmd "null";
BA_ "sigExplanation" SG_ 835 BCM_MirrCmd "null";
BA_ "sigSecLevel" SG_ 835 BCM_MirrCmd "null";
BA_ "sigConfig" SG_ 837 BCM_345_CheckSum "null";
BA_ "sigExplanation" SG_ 837 BCM_345_CheckSum "null";
BA_ "sigSecLevel" SG_ 837 BCM_345_CheckSum "null";
BA_ "sigConfig" SG_ 837 BCM_345_AliveCounter "null";
BA_ "sigExplanation" SG_ 837 BCM_345_AliveCounter "null";
BA_ "sigSecLevel" SG_ 837 BCM_345_AliveCounter "null";
BA_ "sigConfig" SG_ 837 BCM_OutpValResl_HUD "null";
BA_ "sigExplanation" SG_ 837 BCM_OutpValResl_HUD "null";
BA_ "sigSecLevel" SG_ 837 BCM_OutpValResl_HUD "null";
BA_ "sigConfig" SG_ 837 BCM_SunshadeRunngSts "null";
BA_ "sigExplanation" SG_ 837 BCM_SunshadeRunngSts "null";
BA_ "sigSecLevel" SG_ 837 BCM_SunshadeRunngSts "null";
BA_ "sigConfig" SG_ 837 BCM_RiSolaValr_RLS "null";
BA_ "sigExplanation" SG_ 837 BCM_RiSolaValr_RLS "null";
BA_ "sigSecLevel" SG_ 837 BCM_RiSolaValr_RLS "A";
BA_ "sigConfig" SG_ 837 BCM_LeSolaValr_RLS "null";
BA_ "sigExplanation" SG_ 837 BCM_LeSolaValr_RLS "null";
BA_ "sigSecLevel" SG_ 837 BCM_LeSolaValr_RLS "A";
BA_ "sigConfig" SG_ 837 BCM_WindshdHum_RLS "null";
BA_ "sigExplanation" SG_ 837 BCM_WindshdHum_RLS "null";
BA_ "sigSecLevel" SG_ 837 BCM_WindshdHum_RLS "A";
BA_ "sigConfig" SG_ 837 BCM_WindshdT_RLS "null";
BA_ "sigExplanation" SG_ 837 BCM_WindshdT_RLS "null";
BA_ "sigSecLevel" SG_ 837 BCM_WindshdT_RLS "A";
BA_ "sigConfig" SG_ 837 BCM_MeasdVal_HUD "null";
BA_ "sigExplanation" SG_ 837 BCM_MeasdVal_HUD "null";
BA_ "sigSecLevel" SG_ 837 BCM_MeasdVal_HUD "null";
BA_ "sigConfig" SG_ 837 BCM_SunshadePosnInfo "null";
BA_ "sigExplanation" SG_ 837 BCM_SunshadePosnInfo "null";
BA_ "sigSecLevel" SG_ 837 BCM_SunshadePosnInfo "null";
BA_ "sigConfig" SG_ 852 MCU_R_354_CheckSum "null";
BA_ "sigExplanation" SG_ 852 MCU_R_354_CheckSum "null";
BA_ "sigSecLevel" SG_ 852 MCU_R_354_CheckSum "null";
BA_ "sigConfig" SG_ 852 MCU_R_354_AliveCounter "null";
BA_ "sigExplanation" SG_ 852 MCU_R_354_AliveCounter "null";
BA_ "sigSecLevel" SG_ 852 MCU_R_354_AliveCounter "null";
BA_ "sigConfig" SG_ 852 MCU_R_ReqZeroTqFlg "null";
BA_ "sigExplanation" SG_ 852 MCU_R_ReqZeroTqFlg "null";
BA_ "sigSecLevel" SG_ 852 MCU_R_ReqZeroTqFlg "null";
BA_ "sigConfig" SG_ 852 MCU_R_CrtSts "null";
BA_ "sigExplanation" SG_ 852 MCU_R_CrtSts "null";
BA_ "sigSecLevel" SG_ 852 MCU_R_CrtSts "null";
BA_ "GenSigStartValue" SG_ 852 MCU_R_MaxPwrGennTq 511;
BA_ "sigConfig" SG_ 852 MCU_R_MaxPwrGennTq "null";
BA_ "sigExplanation" SG_ 852 MCU_R_MaxPwrGennTq "null";
BA_ "sigSecLevel" SG_ 852 MCU_R_MaxPwrGennTq "null";
BA_ "GenSigStartValue" SG_ 852 MCU_R_MaxElecTq 511;
BA_ "sigConfig" SG_ 852 MCU_R_MaxElecTq "null";
BA_ "sigExplanation" SG_ 852 MCU_R_MaxElecTq "null";
BA_ "sigSecLevel" SG_ 852 MCU_R_MaxElecTq "null";
BA_ "GenSigStartValue" SG_ 852 MCU_R_MOT_T 48;
BA_ "sigConfig" SG_ 852 MCU_R_MOT_T "null";
BA_ "sigExplanation" SG_ 852 MCU_R_MOT_T "null";
BA_ "sigSecLevel" SG_ 852 MCU_R_MOT_T "null";
BA_ "GenSigStartValue" SG_ 852 MCU_R_IGBTT 48;
BA_ "sigConfig" SG_ 852 MCU_R_IGBTT "null";
BA_ "sigExplanation" SG_ 852 MCU_R_IGBTT "null";
BA_ "sigSecLevel" SG_ 852 MCU_R_IGBTT "null";
BA_ "sigConfig" SG_ 853 MCU_F_355_CheckSum "null";
BA_ "sigExplanation" SG_ 853 MCU_F_355_CheckSum "null";
BA_ "sigSecLevel" SG_ 853 MCU_F_355_CheckSum "null";
BA_ "sigConfig" SG_ 853 MCU_F_355_AliveCounter "null";
BA_ "sigExplanation" SG_ 853 MCU_F_355_AliveCounter "null";
BA_ "sigSecLevel" SG_ 853 MCU_F_355_AliveCounter "null";
BA_ "sigConfig" SG_ 853 MCU_F_ReqZeroTqFlg "null";
BA_ "sigExplanation" SG_ 853 MCU_F_ReqZeroTqFlg "null";
BA_ "sigSecLevel" SG_ 853 MCU_F_ReqZeroTqFlg "null";
BA_ "GenSigStartValue" SG_ 853 MCU_F_MaxPwrGennTq 511;
BA_ "sigConfig" SG_ 853 MCU_F_MaxPwrGennTq "null";
BA_ "sigExplanation" SG_ 853 MCU_F_MaxPwrGennTq "null";
BA_ "sigSecLevel" SG_ 853 MCU_F_MaxPwrGennTq "null";
BA_ "GenSigStartValue" SG_ 853 MCU_F_MaxElecTq 511;
BA_ "sigConfig" SG_ 853 MCU_F_MaxElecTq "null";
BA_ "sigExplanation" SG_ 853 MCU_F_MaxElecTq "null";
BA_ "sigSecLevel" SG_ 853 MCU_F_MaxElecTq "null";
BA_ "GenSigStartValue" SG_ 853 MCU_F_MOT_T 48;
BA_ "sigConfig" SG_ 853 MCU_F_MOT_T "null";
BA_ "sigExplanation" SG_ 853 MCU_F_MOT_T "null";
BA_ "sigSecLevel" SG_ 853 MCU_F_MOT_T "null";
BA_ "GenSigStartValue" SG_ 853 MCU_F_IGBTT 48;
BA_ "sigConfig" SG_ 853 MCU_F_IGBTT "null";
BA_ "sigExplanation" SG_ 853 MCU_F_IGBTT "null";
BA_ "sigSecLevel" SG_ 853 MCU_F_IGBTT "null";
BA_ "sigConfig" SG_ 855 VCU_357_CheckSum "null";
BA_ "sigExplanation" SG_ 855 VCU_357_CheckSum "null";
BA_ "sigSecLevel" SG_ 855 VCU_357_CheckSum "null";
BA_ "sigConfig" SG_ 855 VCU_357_AliveCounter "null";
BA_ "sigExplanation" SG_ 855 VCU_357_AliveCounter "null";
BA_ "sigSecLevel" SG_ 855 VCU_357_AliveCounter "null";
BA_ "sigConfig" SG_ 855 VCU_ChrgSts_GB "null";
BA_ "sigExplanation" SG_ 855 VCU_ChrgSts_GB "null";
BA_ "sigSecLevel" SG_ 855 VCU_ChrgSts_GB "null";
BA_ "sigConfig" SG_ 855 VCU_MCUFltSum_GB "null";
BA_ "sigExplanation" SG_ 855 VCU_MCUFltSum_GB "null";
BA_ "sigSecLevel" SG_ 855 VCU_MCUFltSum_GB "null";
BA_ "sigConfig" SG_ 855 VCU_BrkPedlSts_GB "null";
BA_ "sigExplanation" SG_ 855 VCU_BrkPedlSts_GB "null";
BA_ "sigSecLevel" SG_ 855 VCU_BrkPedlSts_GB "null";
BA_ "sigConfig" SG_ 855 VCU_SOCLoWakeUpThd "null";
BA_ "sigExplanation" SG_ 855 VCU_SOCLoWakeUpThd "null";
BA_ "sigSecLevel" SG_ 855 VCU_SOCLoWakeUpThd "null";
BA_ "sigConfig" SG_ 855 VCU_SOCLoWakeUpEnaCmd "null";
BA_ "sigExplanation" SG_ 855 VCU_SOCLoWakeUpEnaCmd "null";
BA_ "sigSecLevel" SG_ 855 VCU_SOCLoWakeUpEnaCmd "null";
BA_ "sigConfig" SG_ 855 VCU_DrvModDiRmn "null";
BA_ "sigExplanation" SG_ 855 VCU_DrvModDiRmn "null";
BA_ "sigSecLevel" SG_ 855 VCU_DrvModDiRmn "null";
BA_ "sigConfig" SG_ 855 VCU_SpclTerrainModUsrRmn "null";
BA_ "sigExplanation" SG_ 855 VCU_SpclTerrainModUsrRmn "null";
BA_ "sigSecLevel" SG_ 855 VCU_SpclTerrainModUsrRmn "null";
BA_ "sigConfig" SG_ 855 VCU_BattIntegtChrgEndFlg "null";
BA_ "sigExplanation" SG_ 855 VCU_BattIntegtChrgEndFlg "null";
BA_ "sigSecLevel" SG_ 855 VCU_BattIntegtChrgEndFlg "null";
BA_ "sigConfig" SG_ 855 VCU_BattIntegtChrgModPwrOnReq "null";
BA_ "sigExplanation" SG_ 855 VCU_BattIntegtChrgModPwrOnReq "null";
BA_ "sigSecLevel" SG_ 855 VCU_BattIntegtChrgModPwrOnReq "null";
BA_ "sigConfig" SG_ 855 VCU_BattIntegtChrgWakeUpSts "null";
BA_ "sigExplanation" SG_ 855 VCU_BattIntegtChrgWakeUpSts "null";
BA_ "sigSecLevel" SG_ 855 VCU_BattIntegtChrgWakeUpSts "null";
BA_ "sigConfig" SG_ 855 VCU_RemUgrdFltFbSig "null";
BA_ "sigExplanation" SG_ 855 VCU_RemUgrdFltFbSig "null";
BA_ "sigSecLevel" SG_ 855 VCU_RemUgrdFltFbSig "null";
BA_ "sigConfig" SG_ 856 VCU_358_CheckSum "null";
BA_ "sigExplanation" SG_ 856 VCU_358_CheckSum "null";
BA_ "sigSecLevel" SG_ 856 VCU_358_CheckSum "null";
BA_ "sigConfig" SG_ 856 VCU_358_AliveCounter "null";
BA_ "sigExplanation" SG_ 856 VCU_358_AliveCounter "null";
BA_ "sigSecLevel" SG_ 856 VCU_358_AliveCounter "null";
BA_ "sigConfig" SG_ 856 VCU_EPedlEnaSig "null";
BA_ "sigExplanation" SG_ 856 VCU_EPedlEnaSig "null";
BA_ "sigSecLevel" SG_ 856 VCU_EPedlEnaSig "null";
BA_ "sigConfig" SG_ 856 VCU_ComLostFlt_ESP "null";
BA_ "sigExplanation" SG_ 856 VCU_ComLostFlt_ESP "null";
BA_ "sigSecLevel" SG_ 856 VCU_ComLostFlt_ESP "null";
BA_ "sigConfig" SG_ 856 VCU_ComFlt_iBooster "null";
BA_ "sigExplanation" SG_ 856 VCU_ComFlt_iBooster "null";
BA_ "sigSecLevel" SG_ 856 VCU_ComFlt_iBooster "null";
BA_ "sigConfig" SG_ 856 VCU_RegenLvlFb "null";
BA_ "sigExplanation" SG_ 856 VCU_RegenLvlFb "null";
BA_ "sigSecLevel" SG_ 856 VCU_RegenLvlFb "null";
BA_ "sigConfig" SG_ 856 VCU_AccelModFb "null";
BA_ "sigExplanation" SG_ 856 VCU_AccelModFb "null";
BA_ "sigSecLevel" SG_ 856 VCU_AccelModFb "null";
BA_ "sigConfig" SG_ 856 VCU_EPedlStsFb "null";
BA_ "sigExplanation" SG_ 856 VCU_EPedlStsFb "null";
BA_ "sigSecLevel" SG_ 856 VCU_EPedlStsFb "null";
BA_ "sigConfig" SG_ 856 VCU_CcTrgSpdDisp "null";
BA_ "sigExplanation" SG_ 856 VCU_CcTrgSpdDisp "null";
BA_ "sigSecLevel" SG_ 856 VCU_CcTrgSpdDisp "null";
BA_ "sigConfig" SG_ 856 VCU_Sts_CC_ICC "null";
BA_ "sigExplanation" SG_ 856 VCU_Sts_CC_ICC "null";
BA_ "sigSecLevel" SG_ 856 VCU_Sts_CC_ICC "null";
BA_ "sigConfig" SG_ 856 VCU_CCIconDisp "null";
BA_ "sigExplanation" SG_ 856 VCU_CCIconDisp "null";
BA_ "sigSecLevel" SG_ 856 VCU_CCIconDisp "null";
BA_ "sigConfig" SG_ 856 VCU_DispSpdUnit_CC "null";
BA_ "sigExplanation" SG_ 856 VCU_DispSpdUnit_CC "null";
BA_ "sigSecLevel" SG_ 856 VCU_DispSpdUnit_CC "null";
BA_ "sigConfig" SG_ 864 BMS_PwrBattPosGNDInsulRrel "null";
BA_ "sigExplanation" SG_ 864 BMS_PwrBattPosGNDInsulRrel "null";
BA_ "sigSecLevel" SG_ 864 BMS_PwrBattPosGNDInsulRrel "null";
BA_ "sigConfig" SG_ 864 BMS_PwrBattNegGNDInsulRrel "null";
BA_ "sigExplanation" SG_ 864 BMS_PwrBattNegGNDInsulRrel "null";
BA_ "sigSecLevel" SG_ 864 BMS_PwrBattNegGNDInsulRrel "null";
BA_ "sigConfig" SG_ 864 BMS_PwrBattPosGNDInsulR "null";
BA_ "sigExplanation" SG_ 864 BMS_PwrBattPosGNDInsulR "null";
BA_ "sigSecLevel" SG_ 864 BMS_PwrBattPosGNDInsulR "null";
BA_ "sigConfig" SG_ 864 BMS_PwrBattNegGNDInsulR "null";
BA_ "sigExplanation" SG_ 864 BMS_PwrBattNegGNDInsulR "null";
BA_ "sigSecLevel" SG_ 864 BMS_PwrBattNegGNDInsulR "null";
BA_ "sigConfig" SG_ 867 VCU_ACDchaStrtFailReason "null";
BA_ "sigExplanation" SG_ 867 VCU_ACDchaStrtFailReason "null";
BA_ "sigSecLevel" SG_ 867 VCU_ACDchaStrtFailReason "null";
BA_ "sigConfig" SG_ 867 VCU_AllwRemHeatgSts "null";
BA_ "sigExplanation" SG_ 867 VCU_AllwRemHeatgSts "null";
BA_ "sigSecLevel" SG_ 867 VCU_AllwRemHeatgSts "null";
BA_ "sigConfig" SG_ 867 VCU_FbRemHeatgOperSts "null";
BA_ "sigExplanation" SG_ 867 VCU_FbRemHeatgOperSts "null";
BA_ "sigSecLevel" SG_ 867 VCU_FbRemHeatgOperSts "null";
BA_ "sigConfig" SG_ 867 VCU_ChrgEndSOCCrtCtrlFlg "null";
BA_ "sigExplanation" SG_ 867 VCU_ChrgEndSOCCrtCtrlFlg "null";
BA_ "sigSecLevel" SG_ 867 VCU_ChrgEndSOCCrtCtrlFlg "null";
BA_ "sigConfig" SG_ 867 VCU_Lvl2ProtStrtFlg "null";
BA_ "sigExplanation" SG_ 867 VCU_Lvl2ProtStrtFlg "null";
BA_ "sigSecLevel" SG_ 867 VCU_Lvl2ProtStrtFlg "null";
BA_ "sigConfig" SG_ 867 VCU_TotOverVoltLvl2ProtFlg "null";
BA_ "sigExplanation" SG_ 867 VCU_TotOverVoltLvl2ProtFlg "null";
BA_ "sigSecLevel" SG_ 867 VCU_TotOverVoltLvl2ProtFlg "null";
BA_ "sigConfig" SG_ 867 VCU_UnderVoltFltLvl2ProtFlg "null";
BA_ "sigExplanation" SG_ 867 VCU_UnderVoltFltLvl2ProtFlg "null";
BA_ "sigSecLevel" SG_ 867 VCU_UnderVoltFltLvl2ProtFlg "null";
BA_ "sigConfig" SG_ 867 VCU_OverTFltLvl2ProtFlg "null";
BA_ "sigExplanation" SG_ 867 VCU_OverTFltLvl2ProtFlg "null";
BA_ "sigSecLevel" SG_ 867 VCU_OverTFltLvl2ProtFlg "null";
BA_ "sigConfig" SG_ 867 VCU_OverVoltFltLvl2ProtFlg "null";
BA_ "sigExplanation" SG_ 867 VCU_OverVoltFltLvl2ProtFlg "null";
BA_ "sigSecLevel" SG_ 867 VCU_OverVoltFltLvl2ProtFlg "null";
BA_ "sigConfig" SG_ 867 VCU_CellIntShoFltLvl2ProtFlg "null";
BA_ "sigExplanation" SG_ 867 VCU_CellIntShoFltLvl2ProtFlg "null";
BA_ "sigSecLevel" SG_ 867 VCU_CellIntShoFltLvl2ProtFlg "null";
BA_ "sigConfig" SG_ 867 VCU_InsulFltLvl2ProtFlg "null";
BA_ "sigExplanation" SG_ 867 VCU_InsulFltLvl2ProtFlg "null";
BA_ "sigSecLevel" SG_ 867 VCU_InsulFltLvl2ProtFlg "null";
BA_ "sigConfig" SG_ 867 VCU_VehCfgExchgFlg "null";
BA_ "sigExplanation" SG_ 867 VCU_VehCfgExchgFlg "null";
BA_ "sigSecLevel" SG_ 867 VCU_VehCfgExchgFlg "null";
BA_ "sigConfig" SG_ 867 VCU_ReadEEFailFlg "null";
BA_ "sigExplanation" SG_ 867 VCU_ReadEEFailFlg "null";
BA_ "sigSecLevel" SG_ 867 VCU_ReadEEFailFlg "null";
BA_ "sigConfig" SG_ 867 VCU_WrEEFailFlg "null";
BA_ "sigExplanation" SG_ 867 VCU_WrEEFailFlg "null";
BA_ "sigSecLevel" SG_ 867 VCU_WrEEFailFlg "null";
BA_ "sigConfig" SG_ 867 VCU_FirstUseEEFlg "null";
BA_ "sigExplanation" SG_ 867 VCU_FirstUseEEFlg "null";
BA_ "sigSecLevel" SG_ 867 VCU_FirstUseEEFlg "null";
BA_ "sigConfig" SG_ 867 VCU_SwUpdataFlg "null";
BA_ "sigExplanation" SG_ 867 VCU_SwUpdataFlg "null";
BA_ "sigSecLevel" SG_ 867 VCU_SwUpdataFlg "null";
BA_ "sigConfig" SG_ 867 VCU_NewOldEESwtFlg "null";
BA_ "sigExplanation" SG_ 867 VCU_NewOldEESwtFlg "null";
BA_ "sigSecLevel" SG_ 867 VCU_NewOldEESwtFlg "null";
BA_ "sigConfig" SG_ 867 VCU_FSCFillEndFlg "null";
BA_ "sigExplanation" SG_ 867 VCU_FSCFillEndFlg "null";
BA_ "sigSecLevel" SG_ 867 VCU_FSCFillEndFlg "null";
BA_ "sigConfig" SG_ 867 VCU_MaxAlrmLvl "null";
BA_ "sigExplanation" SG_ 867 VCU_MaxAlrmLvl "null";
BA_ "sigSecLevel" SG_ 867 VCU_MaxAlrmLvl "null";
BA_ "sigConfig" SG_ 867 VCU_UsrStopChrgReqSts "null";
BA_ "sigExplanation" SG_ 867 VCU_UsrStopChrgReqSts "null";
BA_ "sigSecLevel" SG_ 867 VCU_UsrStopChrgReqSts "null";
BA_ "sigConfig" SG_ 867 VCU_DchaIndcrLampCtrlCmd "null";
BA_ "sigExplanation" SG_ 867 VCU_DchaIndcrLampCtrlCmd "null";
BA_ "sigSecLevel" SG_ 867 VCU_DchaIndcrLampCtrlCmd "null";
BA_ "sigConfig" SG_ 867 VCU_VehExtDchaSts "null";
BA_ "sigExplanation" SG_ 867 VCU_VehExtDchaSts "null";
BA_ "sigSecLevel" SG_ 867 VCU_VehExtDchaSts "null";
BA_ "sigConfig" SG_ 867 VCU_S1SwtCmd "null";
BA_ "sigExplanation" SG_ 867 VCU_S1SwtCmd "null";
BA_ "sigSecLevel" SG_ 867 VCU_S1SwtCmd "null";
BA_ "sigConfig" SG_ 867 VCU_DchaFltStsIndcn "null";
BA_ "sigExplanation" SG_ 867 VCU_DchaFltStsIndcn "null";
BA_ "sigSecLevel" SG_ 867 VCU_DchaFltStsIndcn "null";
BA_ "sigConfig" SG_ 867 VCU_DchaUsrSetThd "null";
BA_ "sigExplanation" SG_ 867 VCU_DchaUsrSetThd "null";
BA_ "sigSecLevel" SG_ 867 VCU_DchaUsrSetThd "null";
BA_ "sigConfig" SG_ 867 VCU_RemHeatgDmd "null";
BA_ "sigExplanation" SG_ 867 VCU_RemHeatgDmd "null";
BA_ "sigSecLevel" SG_ 867 VCU_RemHeatgDmd "null";
BA_ "sigConfig" SG_ 867 VCU_PwrBattHeatgTyp "null";
BA_ "sigExplanation" SG_ 867 VCU_PwrBattHeatgTyp "null";
BA_ "sigSecLevel" SG_ 867 VCU_PwrBattHeatgTyp "null";
BA_ "sigConfig" SG_ 867 VCU_RemPwrBattPreheatgDmdTi "null";
BA_ "sigExplanation" SG_ 867 VCU_RemPwrBattPreheatgDmdTi "null";
BA_ "sigSecLevel" SG_ 867 VCU_RemPwrBattPreheatgDmdTi "null";
BA_ "sigConfig" SG_ 867 VCU_ChrgInsulFctOpenSts "null";
BA_ "sigExplanation" SG_ 867 VCU_ChrgInsulFctOpenSts "null";
BA_ "sigSecLevel" SG_ 867 VCU_ChrgInsulFctOpenSts "null";
BA_ "sigConfig" SG_ 867 VCU_ChrgEquipPwrNotEngh "null";
BA_ "sigExplanation" SG_ 867 VCU_ChrgEquipPwrNotEngh "null";
BA_ "sigSecLevel" SG_ 867 VCU_ChrgEquipPwrNotEngh "null";
BA_ "sigConfig" SG_ 867 VCU_ACChrgStrtFailReason "null";
BA_ "sigExplanation" SG_ 867 VCU_ACChrgStrtFailReason "null";
BA_ "sigSecLevel" SG_ 867 VCU_ACChrgStrtFailReason "null";
BA_ "sigConfig" SG_ 868 BCM_364_CheckSum "null";
BA_ "sigExplanation" SG_ 868 BCM_364_CheckSum "null";
BA_ "sigSecLevel" SG_ 868 BCM_364_CheckSum "null";
BA_ "sigConfig" SG_ 868 BCM_364_AliveCounter "null";
BA_ "sigExplanation" SG_ 868 BCM_364_AliveCounter "null";
BA_ "sigSecLevel" SG_ 868 BCM_364_AliveCounter "null";
BA_ "GenSigStartValue" SG_ 868 BCM_SBRMatStPass 3;
BA_ "sigConfig" SG_ 868 BCM_SBRMatStPass "null";
BA_ "sigExplanation" SG_ 868 BCM_SBRMatStPass "null";
BA_ "sigSecLevel" SG_ 868 BCM_SBRMatStPass "null";
BA_ "GenSigStartValue" SG_ 868 BCM_BucSwtSt2ndRowLeft 3;
BA_ "sigConfig" SG_ 868 BCM_BucSwtSt2ndRowLeft "null";
BA_ "sigExplanation" SG_ 868 BCM_BucSwtSt2ndRowLeft "null";
BA_ "sigSecLevel" SG_ 868 BCM_BucSwtSt2ndRowLeft "null";
BA_ "GenSigStartValue" SG_ 868 BCM_BucSwtSt2ndRowMid 3;
BA_ "sigConfig" SG_ 868 BCM_BucSwtSt2ndRowMid "null";
BA_ "sigExplanation" SG_ 868 BCM_BucSwtSt2ndRowMid "null";
BA_ "sigSecLevel" SG_ 868 BCM_BucSwtSt2ndRowMid "null";
BA_ "GenSigStartValue" SG_ 868 BCM_BucSwtSt2ndRowRight 3;
BA_ "sigConfig" SG_ 868 BCM_BucSwtSt2ndRowRight "null";
BA_ "sigExplanation" SG_ 868 BCM_BucSwtSt2ndRowRight "null";
BA_ "sigSecLevel" SG_ 868 BCM_BucSwtSt2ndRowRight "null";
BA_ "GenSigStartValue" SG_ 868 BCM_BucSwtSt3rdRowLeft 3;
BA_ "sigConfig" SG_ 868 BCM_BucSwtSt3rdRowLeft "null";
BA_ "sigExplanation" SG_ 868 BCM_BucSwtSt3rdRowLeft "null";
BA_ "sigSecLevel" SG_ 868 BCM_BucSwtSt3rdRowLeft "null";
BA_ "GenSigStartValue" SG_ 868 BCM_BucSwtSt3rdRowRight 3;
BA_ "sigConfig" SG_ 868 BCM_BucSwtSt3rdRowRight "null";
BA_ "sigExplanation" SG_ 868 BCM_BucSwtSt3rdRowRight "null";
BA_ "sigSecLevel" SG_ 868 BCM_BucSwtSt3rdRowRight "null";
BA_ "GenSigStartValue" SG_ 868 BCM_SBRMatSt2ndRowLeft 3;
BA_ "sigConfig" SG_ 868 BCM_SBRMatSt2ndRowLeft "null";
BA_ "sigExplanation" SG_ 868 BCM_SBRMatSt2ndRowLeft "null";
BA_ "sigSecLevel" SG_ 868 BCM_SBRMatSt2ndRowLeft "null";
BA_ "GenSigStartValue" SG_ 868 BCM_SBRMatSt2ndRowMid 3;
BA_ "sigConfig" SG_ 868 BCM_SBRMatSt2ndRowMid "null";
BA_ "sigExplanation" SG_ 868 BCM_SBRMatSt2ndRowMid "null";
BA_ "sigSecLevel" SG_ 868 BCM_SBRMatSt2ndRowMid "null";
BA_ "GenSigStartValue" SG_ 868 BCM_SBRMatSt2ndRowRight 3;
BA_ "sigConfig" SG_ 868 BCM_SBRMatSt2ndRowRight "null";
BA_ "sigExplanation" SG_ 868 BCM_SBRMatSt2ndRowRight "null";
BA_ "sigSecLevel" SG_ 868 BCM_SBRMatSt2ndRowRight "null";
BA_ "GenSigStartValue" SG_ 868 BCM_SBRMat3rdRowLeft 3;
BA_ "sigConfig" SG_ 868 BCM_SBRMat3rdRowLeft "null";
BA_ "sigExplanation" SG_ 868 BCM_SBRMat3rdRowLeft "null";
BA_ "sigSecLevel" SG_ 868 BCM_SBRMat3rdRowLeft "null";
BA_ "GenSigStartValue" SG_ 868 BCM_SBRMat3rdRowRight 3;
BA_ "sigConfig" SG_ 868 BCM_SBRMat3rdRowRight "null";
BA_ "sigExplanation" SG_ 868 BCM_SBRMat3rdRowRight "null";
BA_ "sigSecLevel" SG_ 868 BCM_SBRMat3rdRowRight "null";
BA_ "sigConfig" SG_ 869 MCU_F_SecuStsChkFlt "null";
BA_ "sigExplanation" SG_ 869 MCU_F_SecuStsChkFlt "null";
BA_ "sigSecLevel" SG_ 869 MCU_F_SecuStsChkFlt "null";
BA_ "sigConfig" SG_ 869 MCU_F_HVActvDchaFlt "null";
BA_ "sigExplanation" SG_ 869 MCU_F_HVActvDchaFlt "null";
BA_ "sigSecLevel" SG_ 869 MCU_F_HVActvDchaFlt "null";
BA_ "sigConfig" SG_ 869 MCU_F_CtrlPanTChkCircFlt "null";
BA_ "sigExplanation" SG_ 869 MCU_F_CtrlPanTChkCircFlt "null";
BA_ "sigSecLevel" SG_ 869 MCU_F_CtrlPanTChkCircFlt "null";
BA_ "sigConfig" SG_ 869 MCU_F_ComLostFlt_VCU "null";
BA_ "sigExplanation" SG_ 869 MCU_F_ComLostFlt_VCU "null";
BA_ "sigSecLevel" SG_ 869 MCU_F_ComLostFlt_VCU "null";
BA_ "sigConfig" SG_ 869 MCU_F_E2EFlt "null";
BA_ "sigExplanation" SG_ 869 MCU_F_E2EFlt "null";
BA_ "sigSecLevel" SG_ 869 MCU_F_E2EFlt "null";
BA_ "sigConfig" SG_ 869 MCU_F_I2TFlt "null";
BA_ "sigExplanation" SG_ 869 MCU_F_I2TFlt "null";
BA_ "sigSecLevel" SG_ 869 MCU_F_I2TFlt "null";
BA_ "sigConfig" SG_ 869 MCU_F_OperModFlt "null";
BA_ "sigExplanation" SG_ 869 MCU_F_OperModFlt "null";
BA_ "sigSecLevel" SG_ 869 MCU_F_OperModFlt "null";
BA_ "sigConfig" SG_ 869 MCU_F_CooltOverTFlt "null";
BA_ "sigExplanation" SG_ 869 MCU_F_CooltOverTFlt "null";
BA_ "sigSecLevel" SG_ 869 MCU_F_CooltOverTFlt "null";
BA_ "sigConfig" SG_ 869 MCU_F_PhaCrtSampleCircFltU "null";
BA_ "sigExplanation" SG_ 869 MCU_F_PhaCrtSampleCircFltU "null";
BA_ "sigSecLevel" SG_ 869 MCU_F_PhaCrtSampleCircFltU "null";
BA_ "sigConfig" SG_ 869 MCU_F_PhaCrtSampleCircFltV "null";
BA_ "sigExplanation" SG_ 869 MCU_F_PhaCrtSampleCircFltV "null";
BA_ "sigSecLevel" SG_ 869 MCU_F_PhaCrtSampleCircFltV "null";
BA_ "sigConfig" SG_ 869 MCU_F_PhaCrtSampleCircFltW "null";
BA_ "sigExplanation" SG_ 869 MCU_F_PhaCrtSampleCircFltW "null";
BA_ "sigSecLevel" SG_ 869 MCU_F_PhaCrtSampleCircFltW "null";
BA_ "sigConfig" SG_ 869 MCU_F_ThreePhaCrtChkFlt "null";
BA_ "sigExplanation" SG_ 869 MCU_F_ThreePhaCrtChkFlt "null";
BA_ "sigSecLevel" SG_ 869 MCU_F_ThreePhaCrtChkFlt "null";
BA_ "sigConfig" SG_ 869 MCU_F_DCBusUnderVoltFlt "null";
BA_ "sigExplanation" SG_ 869 MCU_F_DCBusUnderVoltFlt "null";
BA_ "sigSecLevel" SG_ 869 MCU_F_DCBusUnderVoltFlt "null";
BA_ "sigConfig" SG_ 869 MCU_F_DCBusOverVoltFlt "null";
BA_ "sigExplanation" SG_ 869 MCU_F_DCBusOverVoltFlt "null";
BA_ "sigSecLevel" SG_ 869 MCU_F_DCBusOverVoltFlt "null";
BA_ "sigConfig" SG_ 869 MCU_F_PosnSnsrChkCircFlt "null";
BA_ "sigExplanation" SG_ 869 MCU_F_PosnSnsrChkCircFlt "null";
BA_ "sigSecLevel" SG_ 869 MCU_F_PosnSnsrChkCircFlt "null";
BA_ "sigConfig" SG_ 869 MCU_F_DCBusVoltSampleCircFlt "null";
BA_ "sigExplanation" SG_ 869 MCU_F_DCBusVoltSampleCircFlt "null";
BA_ "sigSecLevel" SG_ 869 MCU_F_DCBusVoltSampleCircFlt "null";
BA_ "sigConfig" SG_ 869 MCU_F_OverSpdFlt "null";
BA_ "sigExplanation" SG_ 869 MCU_F_OverSpdFlt "null";
BA_ "sigSecLevel" SG_ 869 MCU_F_OverSpdFlt "null";
BA_ "sigConfig" SG_ 869 MCU_F_IGBTOverTFltU "null";
BA_ "sigExplanation" SG_ 869 MCU_F_IGBTOverTFltU "null";
BA_ "sigSecLevel" SG_ 869 MCU_F_IGBTOverTFltU "null";
BA_ "sigConfig" SG_ 869 MCU_F_IGBTTChkCircFltU "null";
BA_ "sigExplanation" SG_ 869 MCU_F_IGBTTChkCircFltU "null";
BA_ "sigSecLevel" SG_ 869 MCU_F_IGBTTChkCircFltU "null";
BA_ "sigConfig" SG_ 869 MCU_F_IGBTTChkCircFltV "null";
BA_ "sigExplanation" SG_ 869 MCU_F_IGBTTChkCircFltV "null";
BA_ "sigSecLevel" SG_ 869 MCU_F_IGBTTChkCircFltV "null";
BA_ "sigConfig" SG_ 869 MCU_F_IGBTTChkCircFltW "null";
BA_ "sigExplanation" SG_ 869 MCU_F_IGBTTChkCircFltW "null";
BA_ "sigSecLevel" SG_ 869 MCU_F_IGBTTChkCircFltW "null";
BA_ "sigConfig" SG_ 869 MCU_F_OverTFlt "null";
BA_ "sigExplanation" SG_ 869 MCU_F_OverTFlt "null";
BA_ "sigSecLevel" SG_ 869 MCU_F_OverTFlt "null";
BA_ "sigConfig" SG_ 869 MCU_F_TChkCircFlt "null";
BA_ "sigExplanation" SG_ 869 MCU_F_TChkCircFlt "null";
BA_ "sigSecLevel" SG_ 869 MCU_F_TChkCircFlt "null";
BA_ "sigConfig" SG_ 869 MCU_F_CtrlPanOverTFlt "null";
BA_ "sigExplanation" SG_ 869 MCU_F_CtrlPanOverTFlt "null";
BA_ "sigSecLevel" SG_ 869 MCU_F_CtrlPanOverTFlt "null";
BA_ "sigConfig" SG_ 869 MCU_F_LVPwrSplyUnderVoltFlt "null";
BA_ "sigExplanation" SG_ 869 MCU_F_LVPwrSplyUnderVoltFlt "null";
BA_ "sigSecLevel" SG_ 869 MCU_F_LVPwrSplyUnderVoltFlt "null";
BA_ "sigConfig" SG_ 869 MCU_F_LVPwrSplyOverVoltFlt "null";
BA_ "sigExplanation" SG_ 869 MCU_F_LVPwrSplyOverVoltFlt "null";
BA_ "sigSecLevel" SG_ 869 MCU_F_LVPwrSplyOverVoltFlt "null";
BA_ "sigConfig" SG_ 869 MCU_F_FbTqStsChkFlt "null";
BA_ "sigExplanation" SG_ 869 MCU_F_FbTqStsChkFlt "null";
BA_ "sigSecLevel" SG_ 869 MCU_F_FbTqStsChkFlt "null";
BA_ "sigConfig" SG_ 869 MCU_F_PhaCrtSwOverCrtFltU "null";
BA_ "sigExplanation" SG_ 869 MCU_F_PhaCrtSwOverCrtFltU "null";
BA_ "sigSecLevel" SG_ 869 MCU_F_PhaCrtSwOverCrtFltU "null";
BA_ "sigConfig" SG_ 869 MCU_F_TqCmdOverLimFlt "null";
BA_ "sigExplanation" SG_ 869 MCU_F_TqCmdOverLimFlt "null";
BA_ "sigSecLevel" SG_ 869 MCU_F_TqCmdOverLimFlt "null";
BA_ "sigConfig" SG_ 869 MCU_F_PwrSplyModFlt "null";
BA_ "sigExplanation" SG_ 869 MCU_F_PwrSplyModFlt "null";
BA_ "sigSecLevel" SG_ 869 MCU_F_PwrSplyModFlt "null";
BA_ "sigConfig" SG_ 869 MCU_F_IGBTThreePhaTChkFlt "null";
BA_ "sigExplanation" SG_ 869 MCU_F_IGBTThreePhaTChkFlt "null";
BA_ "sigSecLevel" SG_ 869 MCU_F_IGBTThreePhaTChkFlt "null";
BA_ "sigConfig" SG_ 869 MCU_F_RotCalFlt "null";
BA_ "sigExplanation" SG_ 869 MCU_F_RotCalFlt "null";
BA_ "sigSecLevel" SG_ 869 MCU_F_RotCalFlt "null";
BA_ "sigConfig" SG_ 869 MCU_F_IntComFlt "null";
BA_ "sigExplanation" SG_ 869 MCU_F_IntComFlt "null";
BA_ "sigSecLevel" SG_ 869 MCU_F_IntComFlt "null";
BA_ "sigConfig" SG_ 869 MCU_F_IntTqChkFlt "null";
BA_ "sigExplanation" SG_ 869 MCU_F_IntTqChkFlt "null";
BA_ "sigSecLevel" SG_ 869 MCU_F_IntTqChkFlt "null";
BA_ "sigConfig" SG_ 869 MCU_F_IGBTDesatFltTop "null";
BA_ "sigExplanation" SG_ 869 MCU_F_IGBTDesatFltTop "null";
BA_ "sigSecLevel" SG_ 869 MCU_F_IGBTDesatFltTop "null";
BA_ "sigConfig" SG_ 869 MCU_F_IGBTDesatFltBot "null";
BA_ "sigExplanation" SG_ 869 MCU_F_IGBTDesatFltBot "null";
BA_ "sigSecLevel" SG_ 869 MCU_F_IGBTDesatFltBot "null";
BA_ "sigConfig" SG_ 869 MCU_F_PhaCrtSwOverCrtFltV "null";
BA_ "sigExplanation" SG_ 869 MCU_F_PhaCrtSwOverCrtFltV "null";
BA_ "sigSecLevel" SG_ 869 MCU_F_PhaCrtSwOverCrtFltV "null";
BA_ "sigConfig" SG_ 869 MCU_F_PhaCrtSwOverCrtFltW "null";
BA_ "sigExplanation" SG_ 869 MCU_F_PhaCrtSwOverCrtFltW "null";
BA_ "sigSecLevel" SG_ 869 MCU_F_PhaCrtSwOverCrtFltW "null";
BA_ "sigConfig" SG_ 869 MCU_F_IGBTOverTFltV "null";
BA_ "sigExplanation" SG_ 869 MCU_F_IGBTOverTFltV "null";
BA_ "sigSecLevel" SG_ 869 MCU_F_IGBTOverTFltV "null";
BA_ "sigConfig" SG_ 869 MCU_F_IGBTOverTFltW "null";
BA_ "sigExplanation" SG_ 869 MCU_F_IGBTOverTFltW "null";
BA_ "sigSecLevel" SG_ 869 MCU_F_IGBTOverTFltW "null";
BA_REL_ "SC_Verification" BU_SG_REL_ VCU SG_ 817 PKC_OTAInhbRdy 1;
BA_REL_ "SC_Verification" BU_SG_REL_ VCU SG_ 817 PKC_StrtReq 1;
BA_REL_ "SC_Verification" BU_SG_REL_ VCU SG_ 817 PKC_IMMO_AuthSts 1;
BA_REL_ "SC_Verification" BU_SG_REL_ VCU SG_ 817 PKC_331_SSecOC_Fresh_Byte0 1;
BA_REL_ "SC_Verification" BU_SG_REL_ VCU SG_ 817 PKC_331_SSecOC_MAC_Byte0 1;
BA_REL_ "SC_Verification" BU_SG_REL_ VCU SG_ 817 PKC_331_SSecOC_MAC_Byte1 1;
BA_REL_ "SC_Verification" BU_SG_REL_ VCU SG_ 817 PKC_331_SSecOC_MAC_Byte2 1;
VAL_ 565 OBC_DCPosRlyCtrlSts 0 "Open" 1 "Closed" ;
VAL_ 565 OBC_DCNegRlyCtrlSts 0 "Open" 1 "Closed" ;
VAL_ 565 OBC_DCCrt 32767 "Invalid" ;
VAL_ 565 OBC_DCVolt 65535 "Invalid" ;
VAL_ 565 OBC_DCChrgnRlyCrt 32767 "Invalid" ;
VAL_ 566 VCU_DCChrgDchaGunCnctnSts 0 "Initial_value" 1 "Not_connected" 2 "DCCharging/discharging_gun_fully_connnected" 3 "Invalid" ;
VAL_ 566 VCU_OutpACWakeupSigSts 0 "Initial_value" 1 "Not_waken_up" 2 "Waken_up" 3 "Invalid" ;
VAL_ 566 VCU_OutpFCWakeupSigSts 0 "Initial_value" 1 "Not_waken_up" 2 "Waken_up" 3 "Invalid" ;
VAL_ 566 VCU_ACChrgDchaGunCnctnSts 0 "Initial_value" 1 "Not_connected" 2 "ACCharging/discharging_gun_fully_connnected" 3 "V2V_adapter_plugged" 4 "V2L_adapter_plugged" 5 "Reserved" 6 "Reserved" 7 "Invalid" ;
VAL_ 566 VCU_VcuErrCtgy 0 "No_Error" 1 "Component" 2 "Level_2" 3 "Cp_Lv2" 4 "Signal_Status" 5 "Cp_SigSts" 6 "Lv2_SigSts" 7 "Cp_Lv2_SigSts" ;
VAL_ 566 VCU_VcuErrBitVect 0 "no_Error" 1 "Vehicle_Speed_Error" 2 "Accelerator_Pedal_Error" 4 "Cl15_Error" 8 "GSL_Logic_Error" 16 "Charging_Connection_Error" 32 "Lvl2_Static_Torque_Error" 64 "Lvl2_Dynamic_Torque_Dd" 128 "Lvl2_Dynamic_Torque_ESC" 256 "Lvl2_Dynamic_Torque_Rng" 512 "Battery_Error" 1024 "EFA_Error" 2048 "ERA_Error" 4096 "DcDc12_Error" 8192 "GSL_Error" 16384 "PLC_Error" 32768 "THM_Error" 65536 "LadAc_Error" 131072 "LadDc_Error" 262144 "Isolation_error" 524288 "HVIL_Error" 1048576 "Batt_Precharge_Error" 2097152 "Batt_Level_Error" 8388608 "Batt_Main_Contactor_Error" 16777216 "Batt_COM_Lost_Error" 33554432 "EFA_COM_Lost_Error" 67108864 "Dc_Charging_Contactor_Error" ;
VAL_ 566 VCU_VcuState 0 "Undefined" 1 "Wakeup" 2 "Startup_LV" 3 "Startup_HV" 4 "Startup_Boardnet_Supply" 5 "Standby" 6 "Drive" 7 "Charge" 8 "Postrun_Conditioning" 9 "Postrun_Auxiliaries_Idle" 10 "Postrun_HV_Deactivation" 11 "Postrun_HV_Active_Discharge" 12 "Postrun_LV_Deactivation" 13 "Sleep" 14 "Emergency_OFF_Auxiliaries_Idle" 15 "Emergency_OFF_HV_Deactivation" 16 "Emergency_OFF_HV_Act_Dischrg" 17 "Emergency_OFF_LV_Deactivation" 18 "Safestate" 31 "Invalid" ;
VAL_ 566 VCU_PwrSplyEquipSts 0 "Initial_value" 1 "State_2" 2 "State_2'" 3 "State_3'" 4 "Charging_stopped" 5 "Plug_and_charge" 6 "Reserved" 7 "Invalid" ;
VAL_ 586 BMS_PwrBattChrgDchaCrt1 65535 "Invalid" ;
VAL_ 586 BMS_PwrBattChrgDchaCrt2 65535 "Invalid" ;
VAL_ 586 BMS_PwrBattIntTotVoltV1 65535 "Invalid" ;
VAL_ 608 VCU_VehChrgDchgMod 0 "Initial_value" 1 "DC_charging" 2 "VTOL_discharging" 3 "VTOV_discharging" 4 "AC_charging" 5 "V2L_trunk_active" 6 "Reserved" 7 "Invalid" ;
VAL_ 608 VCU_DCRlyCtrlCmd 0 "Open" 1 "Close" ;
VAL_ 608 VCU_ChrgSysOperCmd 0 "Initial_value" 1 "Standby" 2 "Working_mode" 3 "Power_mode" 4 "Shutdown" 5 "Sleep" 6 "Reserved" 7 "Invalid" ;
VAL_ 608 VCU_ChrgSts 0 "Initial_value" 1 "Connected_but_not_charging" 2 "AC_charging" 3 "DC_charging" 4 "Charging_completed" 5 "Charging_fault" 6 "Reserved" 7 "Invalid" ;
VAL_ 627 TBOX_ScheduleCharg_End_Mins 63 "Invalid" ;
VAL_ 627 TBOX_ScheduleCharg_Start_Hr 31 "Invalid" ;
VAL_ 627 TBOX_ScheduleCharg_End_Hr 31 "Invalid" ;
VAL_ 627 TBOX_SetSceduleChargTimeFb 0 "Invalid" 1 "Successful" 2 "Failed" 3 "Reserved" ;
VAL_ 627 TBOX_ScheduleCharg_Start_Mins 63 "Invalid" ;
VAL_ 627 TBOX_ScheduleCharg_Status 0 "Description_for_the_value_'0x0'" 1 "Description_for_the_value_'0x1'" 2 "Description_for_the_value_'0x2'" 3 "Description_for_the_value_'0x3'" ;
VAL_ 627 TBOX_V2L_TrEna 0 "No" 1 "Yes" ;
VAL_ 627 TBOX_V2L_ChrgPortEna 0 "No" 1 "Yes" ;
VAL_ 627 TBOX_V2V_Ena 0 "No" 1 "Yes" ;
VAL_ 627 TBOX_V2H_Ena 0 "No" 1 "Yes" ;
VAL_ 627 TBOX_V2G_Ena 0 "No" 1 "Yes" ;
VAL_ 649 VCU_SetSpeedLimitSts 254 "max._speed" 255 "no_speed_limit" ;
VAL_ 678 IBS_WakeupStatus 0 "No_active_wakeup_demand" 1 "Active_wakeup_demand" 2 "Not_defined" 3 "Signal_not_available_(SNA)" ;
VAL_ 678 IBS_LowVoltage 0 "Flag_inactive" 1 "Flag_active" ;
VAL_ 678 IBS_PowerOn 0 "Flag_inactive" 1 "Flag_active" ;
VAL_ 678 IBS_EngineStart 0 "Flag_inactive" 1 "Flag_active" ;
VAL_ 678 IBS_Sulfation 0 "Flag_inactive" 1 "Flag_active" ;
VAL_ 678 IBS_BatteryDefect 0 "Flag_inactive" 1 "Flag_active" ;
VAL_ 678 IBS_SOCUpperTolerance 255 "SNA" ;
VAL_ 678 IBS_SOCLowerTolerance 255 "SNA" ;
VAL_ 678 IBS_CapacityLossTop 255 "SNA" ;
VAL_ 678 IBS_CapacityLossBottom 255 "SNA" ;
VAL_ 681 IBS_BatteryCurrent 16777215 "SNA" ;
VAL_ 681 IBS_BatteryVoltage 65535 "SNA" ;
VAL_ 681 IBS_BatteryTemperature 511 "SNA" ;
VAL_ 681 IBS_CurrentAutorange 0 "Range_not_defined" 1 "Current_range_I1" 2 "Current_range_I2" 3 "Current_range_I3" ;
VAL_ 681 IBS_Error 0 "IBS_OK" 1 "IBS_defect" ;
VAL_ 684 IBS_StateOfCharge 255 "SNA" ;
VAL_ 684 IBS_StateOfHealth 255 "SNA" ;
VAL_ 684 IBS_EstVoltaDrop 255 "SNA" ;
VAL_ 684 IBS_OptChargeVolt 255 "SNA" ;
VAL_ 684 IBS_AvgRi 65535 "SNA" ;
VAL_ 687 IBS_AvailableCapacity 65535 "SNA" ;
VAL_ 687 IBS_DischargeableAh 65535 "SNA" ;
VAL_ 687 IBS_NominalCapacity 255 "SNA" ;
VAL_ 687 IBS_Recalibrated 0 "Recalibrated" 1 "Not_recalibrated" ;
VAL_ 743 ECC_ICCSysSwtCmdFb 0 "Inactive" 1 "Air_Conditioning_power_on_(Short)" 2 "Air_Conditioning_shutdown_(long)" 3 "Reserved" ;
VAL_ 743 ECC_CooltLvlWarn 0 "no_warning" 1 "set_warning" 2 "Reserved" 3 "Invalid" ;
VAL_ 748 BMS_Cont_CurrentState_PV_Pos 0 "RelayClosed" 1 "RelayOpen" ;
VAL_ 748 BMS_Cont_TargetState_PV_Pos 0 "RelayClosed" 1 "RelayOpen" ;
VAL_ 749 BMS_Cont_CurrentState_PV_Neg 0 "RelayClosed" 1 "RelayOpen" ;
VAL_ 749 BMS_Cont_TargetSgtate_PV_Neg 0 "RelayClosed" 1 "RelayOpen" ;
VAL_ 750 BMS_Cont_Act_St_HV_Pos 0 "RelayClosed" 1 "RelayOpen" ;
VAL_ 750 BMS_Cont_Tar_St_HV_Pos 0 "RelayClosed" 1 "RelayOpen" ;
VAL_ 751 BMS_Cont_Act_St_HV_Neg 0 "RelayClosed" 1 "RelayOpen" ;
VAL_ 751 BMS_Cont_Tar_St_HV_Neg 0 "RelayClosed" 1 "RelayOpen" ;
VAL_ 752 BMS_Cont_Act_St_HV_Prec 0 "RelayClosed" 1 "RelayOpen" ;
VAL_ 752 BMS_Cont_Tar_St_HV_Prec 0 "RelayClosed" 1 "RelayOpen" ;
VAL_ 755 BMS_ErrorWarning_CellVoltageDiff 0 "WarningNotActive" 1 "Warning" ;
VAL_ 755 BMS_ErrorActive_CellVoltageDiffO 0 "ErrorNotActive" 1 "Error" ;
VAL_ 755 BMS_ErrorWarning_Diff_U1_UCellSu 0 "WarningNotActive" 1 "Warning" ;
VAL_ 755 BMS_ErrorActive_Diff_U1_UCellSum 0 "ErrorNotActive" 1 "Error" ;
VAL_ 755 BMS_ErrorWarning_SOH_Low 0 "WarningNotActive" 1 "Warning" ;
VAL_ 755 BMS_ErrorActive_SOH_Low 0 "ErrorNotActive" 1 "Error" ;
VAL_ 755 BMS_SystemError_SystemInitFailed 0 "ErrorNotActive" 1 "Error" ;
VAL_ 755 BMS_SystemError_Precharge 0 "ErrorNotActive" 1 "Error" ;
VAL_ 755 BMS_SystemError_HV_CCT_WrongPola 0 "ErrorNotActive" 1 "Error" ;
VAL_ 755 BMS_SystemError_HV_CCT_NoBatVolt 0 "ErrorNotActive" 1 "Error" ;
VAL_ 755 BMS_HVlinkWarning_VCU_MessageInt 0 "WarningNotActive" 1 "Warning" ;
VAL_ 755 BMS_HVlinkError_IVT_Comm_Failure 0 "ErrorNotActive" 1 "Error" ;
VAL_ 755 BMS_HVlinkWarning_IVT_Meas_Failu 0 "WarningNotActive" 1 "Warning" ;
VAL_ 755 BMS_HVlinkError_IVT_Meas_Failure 0 "ErrorNotActive" 1 "Error" ;
VAL_ 755 BMS_HVlinkError_NVM_Comm_Failure 0 "ErrorNotActive" 1 "Error" ;
VAL_ 755 BMS_HVlinkWarning_Eeprom_LifeCyc 0 "WarningNotActive" 1 "Warning" ;
VAL_ 755 BMS_HVlinkError_Eeprom_LifeCycle 0 "ErrorNotActive" 1 "Error" ;
VAL_ 755 BMS_HVlinkError_ContactorGeneric 0 "ErrorNotActive" 1 "Error" ;
VAL_ 755 BMS_HVlinkError_ContactorOpen 0 "ErrorNotActive" 1 "Error" ;
VAL_ 755 BMS_HVlinkError_ContactorAuxFail 0 "ErrorNotActive" 1 "Error" ;
VAL_ 755 BMS_HVlinkError_ContactorPwmEcon 0 "ErrorNotActive" 1 "Error" ;
VAL_ 755 BMS_HVlinkWarning_AnalogInput_Ex 0 "WarningNotActive" 1 "Warning" ;
VAL_ 755 BMS_HVlinkError_AnalogInput_Exce 0 "ErrorNotActive" 1 "Error" ;
VAL_ 755 BMS_HWerror_KL30_Voltage 0 "ErrorNotActive" 1 "Error" ;
VAL_ 755 BMS_HWerror_SD_Voltage 0 "ErrorNotActive" 1 "Error" ;
VAL_ 755 BMS_HWerror_PCB_Temp_Sensor_Fail 0 "ErrorNotActive" 1 "Error" ;
VAL_ 755 BMS_HWerror_Cell_Temp_Sensor_Fai 0 "ErrorNotActive" 1 "Error" ;
VAL_ 755 BMS_HWwarning_LCM_PCB_OverTemp 0 "WarningNotActive" 1 "Warning" ;
VAL_ 755 BMS_HWerror_LCM_PCB_OverTemp 0 "ErrorNotActive" 1 "Error" ;
VAL_ 755 BMS_HWwarning_LCM_PCB_UnderTemp 0 "WarningNotActive" 1 "Warning" ;
VAL_ 755 BMS_HWerror_LCM_PCB_UnderTemp 0 "ErrorNotActive" 1 "Error" ;
VAL_ 755 BMS_Software_Error_Boot_Faild 0 "ErrorNotActive" 1 "Error" ;
VAL_ 767 VCU_WrkShpModFB 0 "init" 1 "Inactive._EPB_fail" 2 "Inactive._Park_lock_disengage_fail" 3 "Inactive._Rear_axle_Clutch_disengage_fail" 4 "Inactive._Clutch_+_EPB_fail" 5 "Inactive._Clutch_+_Park_lock_fail" 6 "Inactive._Clutch_+_EPB_+_Park_lock_fail" 7 "Inactive._EPB_+_Park_lock_fail" 8 "Inactive._Driver_requested_D_or_R_gear_(give_hier_the_highest_priority_while_checking_in_parallel_with_other_conditions)" 9 "Active" 15 "Invalid" ;
VAL_ 767 VCU_ACC_PA_MinA 65535 "Invalid" ;
VAL_ 767 VCU_ACC_PA_MaxA 65535 "Invalid" ;
VAL_ 767 VCU_WrkShpModAvlbSts 0 "Initial_value" 1 "Not_available" 2 "Available" 3 "Invalid" ;
VAL_ 783 ICC_QuickBootMode 0 "Off" 1 "On" ;
VAL_ 785 ADAS_HiPrioDegradationSts 0 "No_high_priority_popup_requested" 1 "All_ADAS_features_offline" 2 "ACC_is_being_disabled,_driver_take_control_" 3 "Driver_assist_(ACC_with_LCC)_being_disabled,_Driver_take_control" 4 "Traffic_Jam_Assist_being_disabled,_Driver_take_control" 5 "All_front_AEB_support_is_disabled" 6 "All_rear_AEB_support_is_disabled" 7 "Autopark_operations_being_disabled,_driver_take_control" 8 "Park_Assist_Support_disabled" 9 "Front_Cross_Path_Braking_disabled" 10 "Rear_Cross_Path_Braking_disabled" 11 "Emergency_Steering_Assist_is_disabled" 12 "Reserved" 13 "Reserved" 14 "Reserved" 15 "Reserved" 16 "Reserved" 17 "Reserved" 18 "Reserved" 19 "Reserved" 20 "Reserved" 21 "Reserved" 22 "Reserved" 23 "Reserved" 24 "Reserved" 25 "Reserved" 26 "Reserved" 27 "Reserved" 28 "Reserved" 29 "Reserved" 30 "Reserved" 31 "Reserved" 32 "Reserved" 33 "Reserved" 34 "Reserved" 35 "Reserved" 36 "Reserved" 37 "Reserved" 38 "Reserved" 39 "Reserved" 40 "Reserved" 41 "Reserved" 42 "Reserved" 43 "Reserved" 44 "Reserved" 45 "Reserved" 46 "Reserved" 47 "Reserved" 48 "Reserved" 49 "Reserved" 50 "Reserved" 51 "Reserved" 52 "Reserved" 53 "Reserved" 54 "Reserved" 55 "Reserved" 56 "Reserved" 57 "Reserved" 58 "Reserved" 59 "Reserved" 60 "Reserved" 61 "Reserved" 62 "Reserved" 63 "Reserved" ;
VAL_ 785 ADAS_ISA_PerSpdLim_req 0 "No_Percieved_Speed_Limit_change_notification_request" 1 "Percieved_Speed_Limit_change_notification_request" ;
VAL_ 785 ADAS_LoPrioDegradationSts 0 "No_low_priority_popup_requested" 1 "Blind_Spot_monitoring_is_offline" 2 "Collision_warning_disabled" 3 "Lane_departure_warning_disabled" 4 "Front_Cross_path_warning_disabled" 5 "Rear_Cross_Path_warning_disabled" 6 "Park_Assist_warnings_disabled" 7 "Door_Opening_Warning_disabled" 8 "Wheel_Scratch_Prevention_disabled" 9 "DCAA_disabled" 10 "Reserved" 11 "Reserved" 12 "Reserved" 13 "Reserved" 14 "Reserved" 15 "Reserved" 16 "Reserved" 17 "Reserved" 18 "Reserved" 19 "Reserved" 20 "Reserved" 21 "Reserved" 22 "Reserved" 23 "Reserved" 24 "Reserved" 25 "Reserved" 26 "Reserved" 27 "Reserved" 28 "Reserved" 29 "Reserved" 30 "Reserved" 31 "Reserved" 32 "Reserved" 33 "Reserved" 34 "Reserved" 35 "Reserved" 36 "Reserved" 37 "Reserved" 38 "Reserved" 39 "Reserved" 40 "Reserved" 41 "Reserved" 42 "Reserved" 43 "Reserved" 44 "Reserved" 45 "Reserved" 46 "Reserved" 47 "Reserved" 48 "Reserved" 49 "Reserved" 50 "Reserved" 51 "Reserved" 52 "Reserved" 53 "Reserved" 54 "Reserved" 55 "Reserved" 56 "Reserved" 57 "Reserved" 58 "Reserved" 59 "Reserved" 60 "Reserved" 61 "Reserved" 62 "Reserved" 63 "Reserved" ;
VAL_ 785 ADAS_SpeedLimitUnit 0 "KPH" 1 "MPH" ;
VAL_ 792 ESP_BrkPedlStsVld 0 "Initializing" 1 "Valid" 2 "Invalid" 3 "Reserved" ;
VAL_ 792 ESP_BrkPedlSts 0 "Brake_Pedal_Not_Pressed" 1 "Brake_Pedal_Pressed" ;
VAL_ 792 ESP_VehSpdVld 0 "Initializing" 1 "Valid" 2 "Invalid" 3 "Reserved" ;
VAL_ 792 ESP_SysActv 0 "No_Telltale_Requested" 1 "Telltale_Requested" ;
VAL_ 792 ESP_LampSwtOffIndcn 0 "No_Telltale_Requested" 1 "Telltale_Requested" ;
VAL_ 792 ESP_FltIndcn_EBD 0 "No_Telltale_Requested" 1 "Telltale_Requested" ;
VAL_ 792 ESP_FltIndcn_ABS 0 "No_Telltale_Requested" 1 "Telltale_Requested" ;
VAL_ 792 ESP_IninModSigIndcn 0 "Not_In_Initialization_Mode" 1 "In_Intialization_Mode" ;
VAL_ 792 ESP_FltIndcn_TCS 0 "No_Telltale_Requested" 1 "Telltale_Requested" ;
VAL_ 792 ESP_CtrlSts_HDC 0 "Off" 1 "On_Active_Braking" 2 "On_Not_Active_Braking" 3 "Reserved" ;
VAL_ 792 ESP_AvlIndcn_HDC 0 "Available" 1 "Not_Available" ;
VAL_ 792 ESP_NoBrkP 0 "Exist_Brk_Force" 1 "No_Brk_Force" ;
VAL_ 792 ESP_RDAEnaFlg 0 "Inactive_not_enabled" 1 "Active_enable" ;
VAL_ 799 ICC_SetSpeedLimit 254 "max._speed" 255 "no_speed_limit" ;
VAL_ 816 BMS_VehInsulFltDisp 0 "Normal" 1 "Abnormal" ;
VAL_ 816 BMS_PwrBattSysFltDisp 0 "Normal" 1 "Abnormal" ;
VAL_ 816 BMS_PwrBattAvlCp 65535 "Invalid" ;
VAL_ 816 BMS_CellMinTAlrm 0 "No_fault" 1 "Fault" ;
VAL_ 816 BMS_PwrBattThermRunawayAlrm 0 "No_Thermal_Runaway" 1 "Thermal_Runaway_Detected" ;
VAL_ 816 BMS_PwrBattOverT 0 "Normal" 1 "Abnormal" ;
VAL_ 816 BMS_PwrBattInsulSts 0 "Initial_value" 1 "Not_thermally_insulated" 2 "Thermally_insulated" 3 "Thermal_insulation_is_on_for_the_power_battery_is_at_low_temperature" ;
VAL_ 817 PKC_OTARdy_Fb 0 "Initial" 1 "Ready" 2 "Not_Ready" 3 "Invalid" ;
VAL_ 817 PKC_OTAInhbRdy 0 "Initial" 1 "Inhibit" 2 "Not_Inhibit" 3 "Invalid" ;
VAL_ 817 PKC_RemReqCfmRxResp 0 "Inactive" 1 "Active" ;
VAL_ 817 PKC_SysLrngMod 0 "Not_In_Learning_Mode" 1 "In_Learning_Mode" ;
VAL_ 817 PKC_StrtReq 0 "No_Request" 1 "Request_Challenge_from_VCU" ;
VAL_ 817 PKC_IMMO_AuthSts 0 "Initial" 1 "Auth_Valid" 2 "Auth_Invalid" 3 "Invalid" ;
VAL_ 817 PKC_RemModOpenSts 0 "Invalid" 1 "RES_Run_(Function_allowable_state)" 2 "RES_Start_(remote_function_operation)" 3 "Reserved" ;
VAL_ 817 PKC_MnvrSelect 0 "None" 1 "Maneuver_1" 2 "Maneuver_2" 3 "Maneuver_3" 4 "Maneuver_4" 5 "Maneuver_5" 6 "Reserved" 7 "Invalid" ;
VAL_ 817 PKC_MnvrDelete 0 "None" 1 "Maneuver_1" 2 "Maneuver_2" 3 "Maneuver_3" 4 "Maneuver_4" 5 "Maneuver_5" 6 "Reserved" 7 "Invalid" ;
VAL_ 819 BCM_KL15_Off_Announcement 0 "NotAvailable" 1 "No_Announcement" 2 "KL15_shutdown_announced" 3 "Reserved" ;
VAL_ 819 BCM_IG1Sts 0 "NotAvailable" 1 "Inactive" 2 "Active" 3 "Reserved" ;
VAL_ 819 BCM_PwrMod 0 "Off" 1 "ACC_(Reserved)" 2 "IGN_On" 3 "Crank_Pending_(Power_Anti-theft_Certification_Process)" 4 "Run" 5 "Crank_Off_(Reserved)" 6 "Reserved" 7 "Reserved" ;
VAL_ 819 BCM_PwrModVld 0 "Initializing" 1 "Valid" 2 "Invalid" 3 "Reserved" ;
VAL_ 819 BCM_BrkSwtSts 0 "No_Pressed" 1 "Pressed" ;
VAL_ 819 BCM_IG1StsVld_CAPE 0 "Initializing" 1 "Valid" 2 "Invalid" 3 "Reserved" ;
VAL_ 819 BCM_IG2StsVld_CAPE 0 "Initializing" 1 "Valid" 2 "Invalid" 3 "Reserved" ;
VAL_ 819 BCM_KL30s_L 0 "Not_Available" 1 "Inactive" 2 "Active" 3 "Reserved" ;
VAL_ 819 BCM_IG2Sts 0 "Not_Available" 1 "Inactive" 2 "Active" 3 "Reserved" ;
VAL_ 819 BCM_InteriorSwtSt 0 "Inactive" 1 "pressed" 2 "reserved" 3 "reserved" ;
VAL_ 835 BCM_RemReqFb 0 "Idle" 1 "Successful" 2 "Failed" 3 "Processing" ;
VAL_ 835 BCM_APASwSts 0 "Not_active_Not_enabled" 1 "Active_enable" 2 "Reserved" 3 "Invalid" ;
VAL_ 835 BCM_FrntHoodLidSts 0 "Closed" 1 "Open" ;
VAL_ 835 BCM_SunroofAntipinchSts 0 "Inactive" 1 "Active" ;
VAL_ 835 BCM_FrntDrDoorLockSts 0 "Lock" 1 "Unlock" ;
VAL_ 835 BCM_TrRelsSwtSts 0 "Inactive" 1 "Active" ;
VAL_ 835 BCM_LockAllDoorCmd 0 "Inactive" 1 "Active" ;
VAL_ 835 BCM_DrFrntDoorSts 0 "Closed" 1 "Open" ;
VAL_ 835 BCM_PasFrntDoorSts 0 "Closed" 1 "Open" ;
VAL_ 835 BCM_AntithftSts 0 "Anti_Theft_system_Unset" 1 "Anti_Theft_system_Partially_Set" 2 "Anti_Theft_system_Set" 3 "Anti_Theft_alarm_triggered" ;
VAL_ 835 BCM_CenLockSwtSts 0 "Inactive" 1 "Unlock" 2 "Lock" 3 "Reserved" ;
VAL_ 835 BCM_DoorUnlockSetFb 0 "driver's_door" 1 "All_doors" ;
VAL_ 835 BCM_RiReDoorSts 0 "Closed" 1 "Open" ;
VAL_ 835 BCM_LeReDoorSts 0 "Closed" 1 "Open" ;
VAL_ 835 BCM_LeFrntWinSts 0 "Closed" 1 "Open" ;
VAL_ 835 BCM_RiFrntWinSts 0 "Closed" 1 "Open" ;
VAL_ 835 BCM_LeReWinSts 0 "Closed" 1 "Open" ;
VAL_ 835 BCM_RiReWinSt 0 "Closed" 1 "Open" ;
VAL_ 835 BCM_SunroofSts 0 "Closed" 1 "Open" ;
VAL_ 835 BCM_FolwMeSetStsFb 0 "Follow_Me_Closed" 1 "15" 2 "30" 3 "45" 4 "60" 5 "Reserved" 6 "Reserved" 7 "Reserved" ;
VAL_ 835 BCM_DrvrDoorUnlckOutpCmd 0 "Inactive" 1 "Active" ;
VAL_ 835 BCM_PassDoorUnlckOutpCmd 0 "Inactive" 1 "Active" ;
VAL_ 835 BCM_LeDRLOutpCmd 0 "Off" 1 "On" ;
VAL_ 835 BCM_RiDRLOutpCmd 0 "Off" 1 "On" ;
VAL_ 835 BCM_ArmedClsWinSetSts 0 "Inactive" 1 "Active" ;
VAL_ 835 BCM_OffAutoUnlckSetSts 0 "Inactive" 1 "Active" ;
VAL_ 835 BCM_WarnVbrnSts 0 "Not_Active" 1 "Active" ;
VAL_ 835 BCM_SunroofOpenAr 0 "Horizontal_sliding_zone" 1 "Vertical_inclined_zone" ;
VAL_ 835 BCM_SteerWhlVbrnAlrmAvl 0 "Available" 1 "Not_Available_available" 2 "Failure_failed" 3 "Reserved" ;
VAL_ 835 BCM_SunroofRunngSts 0 "Stopped" 1 "Opening_Tilt" 2 "Closing_Tilt" 3 "Opening_Slide" 4 "Closing_Slide" 5 "Reversing_(AP/Stall)" 6 "Moving_Uninitialized" 7 "Reserved" ;
VAL_ 835 BCM_MirrCmd 0 "Inactive" 1 "Fold" 2 "Unfold" 3 "Not_Used" ;
VAL_ 837 BCM_OutpValResl_HUD 0 "HUD_Measuring_Range_1(4cd/m2)" 1 "HUD_Measuring_Range_1(40cd/m2)" ;
VAL_ 837 BCM_SunshadeRunngSts 0 "Stopped" 1 "Opening_Slide" 2 "Closing_Slide" 3 "Reversing_(AP/Stall)" 4 "Moving_Uninitialized" 5 "Reserved" 6 "Reserved" 7 "Reserved" ;
VAL_ 852 MCU_R_ReqZeroTqFlg 0 "No_request" 1 "With_request" ;
VAL_ 852 MCU_R_CrtSts 0 "Standby_state" 1 "Electric_state" 2 "Generation_state" 3 "Reserved" ;
VAL_ 852 MCU_R_MaxPwrGennTq 1023 "Invalid" ;
VAL_ 852 MCU_R_MaxElecTq 1023 "Invalid" ;
VAL_ 852 MCU_R_MOT_T 511 "Invalid" ;
VAL_ 852 MCU_R_IGBTT 511 "Invalid" ;
VAL_ 853 MCU_F_ReqZeroTqFlg 0 "No_request" 1 "With_request" ;
VAL_ 853 MCU_F_CrtSts 0 "Standby_state" 1 "Electric_state" 2 "Generation_state" 3 "Reserved" ;
VAL_ 853 MCU_F_MaxPwrGennTq 1023 "Invalid" ;
VAL_ 853 MCU_F_MaxElecTq 1023 "Invalid" ;
VAL_ 853 MCU_F_MOT_T 511 "Invalid" ;
VAL_ 853 MCU_F_IGBTT 511 "Invalid" ;
VAL_ 855 VCU_ChrgSts_GB 0 "Initial_value" 1 "Parking_charging" 2 "Driving_charging" 3 "Not_charged" 4 "Charging_complete" 5 "Reserved" 6 "Reserved" 7 "Reserved" ;
VAL_ 855 VCU_MCUFltSum_GB 254 "abnormal" 255 "Invalid" ;
VAL_ 855 VCU_BrkPedlSts_GB 0 "brake_OFF" 101 "braking_active_state" ;
VAL_ 855 VCU_SOCLoWakeUpEnaCmd 0 "Do_not_wake_up" 1 "allowed_to_wake_up" ;
VAL_ 855 VCU_DrvModDiRmn 0 "Initial_value" 1 "The_E-Pedal_is_activated" 2 "All_Terrain_activated" 3 "Reserved" 4 "Reserved" 5 "Reserved" 6 "Reserved" 7 "Reserved" ;
VAL_ 855 VCU_SpclTerrainModUsrRmn 0 "Initial_value" 1 "ESP_function_activated_to_disable_all_terrain" 2 "ESP_function_fault_disabled_all_terrain" 3 "Intelligent_driving_activated_disable_all_terrain" 4 "Vehicle_speed_too_high_Disable_all_terrain" 5 "Reserved" 6 "Reserved" 7 "Reserved" ;
VAL_ 855 VCU_BattIntegtChrgEndFlg 0 "Not_ended" 1 "ended" ;
VAL_ 855 VCU_BattIntegtChrgModPwrOnReq 0 "Initialization" 1 "No_demand" 2 "On_demand" 3 "Reserved" ;
VAL_ 855 VCU_BattIntegtChrgWakeUpSts 0 "Not_waken_up" 1 "waken_up" ;
VAL_ 855 VCU_RemUgrdFltFbSig 0 "Initial_value" 1 "Low_battery" 2 "Low_traction_battery" 3 "The_vehicle_is_not_stationary" 4 "gear_is_not_at_P,_N_gear" 5 "The_vehicle_is_at_Ready" 6 "vehicle_not_allowed_for_silent_upgrade" 7 "high_voltage_power-off_fault" 8 "R_&_D_upgrade_download_program,_the_battery_power_does_not_meet_the_demand" 9 "Viod" 10 "Viod" 11 "Viod" 12 "Viod" 13 "Viod" 14 "Viod" 15 "Viod" ;
VAL_ 855 VCU_OTAInhbRdy 0 "Initial" 1 "Inhibit" 2 "Not_Inhibit" 3 "Invalid" ;
VAL_ 856 VCU_KickdwnFlg 0 "Inactive" 1 "Active" 3 "Invalid" ;
VAL_ 856 VCU_EPedlEnaSig 0 "Not_enabled" 1 "Enable" ;
VAL_ 856 VCU_ComLostFlt_ESP 0 "Normal" 1 "Abnormal" ;
VAL_ 856 VCU_ComFlt_iBooster 0 "Normal" 1 "Abnormal" ;
VAL_ 856 VCU_RegenLvlFb 0 "Off" 1 "Normal" 2 "High" 3 "Invalid" ;
VAL_ 856 VCU_AccelModFb 0 "Low" 1 "Medium_" 2 "High" 3 "Invalid" ;
VAL_ 856 VCU_EPedlStsFb 0 "OnePedalDrive" 1 "Roll" 2 "Creep" 3 "Invalid" ;
VAL_ 856 VCU_CcTrgSpdDisp 255 "no_display" ;
VAL_ 856 VCU_Sts_CC_ICC 0 "Off" 1 "Initialization" 2 "Standby" 3 "Active" 4 "Override" 5 "Reserved" 6 "Reserved" 7 "Deactivation_brake" 8 "Deactivation_other" 9 "Failure_reversible" 10 "Failure_irreversible" 11 "Reserved" 12 "Reserved" 13 "Reserved" 14 "Reserved" 15 "Reserved" ;
VAL_ 856 VCU_CCIconDisp 0 "No_Display" 1 "White" 2 "Green" 3 "Fault" 4 "Reserved" 5 "Reserved" 6 "Reserved" 7 "Reserved" ;
VAL_ 856 VCU_DispSpdUnit_CC 0 "KMH" 1 "MPH" ;
VAL_ 856 VCU_BoostEnStat 0 "Default" 1 "Boost_unavailable:_Max_activation_number_exceeded" 2 "Boost_unavailable:_Drive_Mode" 3 "Boost_unavailable:_EDU_Coolant_Inlet_Temperature" 4 "Boost_unavailable:_EDU_Coolant_Flow" 5 "Boost_unavailable:_EDU_Stator/_Rotor_Temperature" 6 "Boost_unavailable:_EDU_Decoupling_Unit_open" 7 "Boost_unavailable:_Battery_limitation" 8 "Boost_available" 9 "Boost_active" 10 "Boost_unavailable:_vehicle_not_in_standstil" 11 "Boost_unavailable:_multiple_causes" 15 "invalid" ;
VAL_ 856 VCU_OTARdy_Fb 0 "Initial" 1 "Ready" 2 "Not_Ready" 3 "Invalid" ;
VAL_ 856 VCU_OTA_ECUInhb_Req 0 "Init" 1 "Inhibit_Request" 2 "No_Inhibit_request" 3 "Invalid" ;
VAL_ 856 VCU_OTAVehCdnChk_ASIL 0 "OTA_veh_cond_not_ok" 1 "OTA_veh_cond_ok" 2 "Fault" 3 "Invalid" ;
VAL_ 856 VCU_OTAVehInhb_ASIL_Fb 0 "Inhibition_not_ok" 1 "Inhibition_ok" 2 "Reserved" 3 "Invalid" ;
VAL_ 864 BMS_PwrBattPosGNDInsulRrel 65535 "Invalid" ;
VAL_ 864 BMS_PwrBattNegGNDInsulRrel 65535 "Invalid" ;
VAL_ 864 BMS_PwrBattPosGNDInsulR 65535 "Invalid" ;
VAL_ 864 BMS_PwrBattNegGNDInsulR 65535 "Invalid" ;
VAL_ 867 VCU_ACDchaStrtFailReason 0 "Initial_value" 1 "Discharging_gun_not_connected_well,_please_replug_it" 2 "No_vehicle_is_detected_for_charging" 3 "Veh_discharg_system_failed,_pull_the_gun_out,_restart_and_repeat_the_steps_agency" 4 "Dicharging_gun_not_locked" 5 "To_discharge,_please_click_the_discharge_button" 6 "Reserved" 7 "Reserved" ;
VAL_ 867 VCU_AllwRemHeatgSts 0 "Initial_value" 1 "BMS_remote_heating_allowed" 2 "SOC_too_low,_remote_heating_not_allowed" 3 "Temperature_too_low,_remote_heating_not_allowed" 4 "In_charging,_remote_heating_not_allowed" 5 "BMS_fault" 6 "Temperature_acceptable,_no_remote_heating_required" 7 "Reserved" ;
VAL_ 867 VCU_FbRemHeatgOperSts 0 "initializing" 1 "Remote_heating" ;
VAL_ 867 VCU_ChrgEndSOCCrtCtrlFlg 0 "No_demand" 1 "Charge_at_min._current" 2 "Request_0A_(standby)" 3 "Reserved" ;
VAL_ 867 VCU_Lvl2ProtStrtFlg 0 "Not_active" 1 "Active" ;
VAL_ 867 VCU_TotOverVoltLvl2ProtFlg 0 "No_fault" 1 "Fault" ;
VAL_ 867 VCU_UnderVoltFltLvl2ProtFlg 0 "No_fault" 1 "Fault" ;
VAL_ 867 VCU_OverTFltLvl2ProtFlg 0 "No_fault" 1 "Fault" ;
VAL_ 867 VCU_OverVoltFltLvl2ProtFlg 0 "No_fault" 1 "Fault" ;
VAL_ 867 VCU_CellIntShoFltLvl2ProtFlg 0 "No_fault" 1 "Fault" ;
VAL_ 867 VCU_InsulFltLvl2ProtFlg 0 "No_fault" 1 "Fault" ;
VAL_ 867 VCU_VehCfgExchgFlg 0 "No" 1 "Yes" ;
VAL_ 867 VCU_ReadEEFailFlg 0 "No" 1 "Yes" ;
VAL_ 867 VCU_WrEEFailFlg 0 "No" 1 "Yes" ;
VAL_ 867 VCU_FirstUseEEFlg 0 "No" 1 "Yes" ;
VAL_ 867 VCU_SwUpdataFlg 0 "No" 1 "Yes" ;
VAL_ 867 VCU_NewOldEESwtFlg 0 "No" 1 "Yes" ;
VAL_ 867 VCU_FSCFillEndFlg 0 "Not_fully_charged" 1 "Fully_charged_and_completed" ;
VAL_ 867 VCU_MaxAlrmLvl 0 "No_fault" 1 "Class_1_fault" 2 "Class_2_fault" 3 "Class_3_fault" ;
VAL_ 867 VCU_UsrStopChrgReqSts 0 "No_request" 1 "Request_for_stopping_charging/discharing_through_the_key" 2 "Request_for_stopping_charging/discharing_through_the_button" 3 "Reserved" ;
VAL_ 867 VCU_DchaIndcrLampCtrlCmd 0 "off" 1 "on" ;
VAL_ 867 VCU_VehExtDchaSts 0 "Initial_value" 1 "Prepare_for_discharging" 2 "Discharging" 3 "Discharging_completed" 4 "No_discharging_allowed" 5 "Internal_Discharge_Error" 6 "Overcurrent_Error" 7 "Invalid" ;
VAL_ 867 VCU_S1SwtCmd 0 "Initial_value" 1 "Electric_level_command" 2 "PWM_command" 3 "Invalid" ;
VAL_ 867 VCU_DchaFltStsIndcn 0 "Normal" 1 "Fault" ;
VAL_ 867 VCU_DchaUsrSetThd 0 "Not_arrived" 1 "Arrived" ;
VAL_ 867 VCU_RemHeatgDmd 0 "Initial_value" 1 "Remote_heating_in_demand" 2 "No_remote_heating_demand" 3 "Reserved" ;
VAL_ 867 VCU_PwrBattHeatgTyp 0 "Initial_value" 1 "Power_battery_charging" 2 "Charging_pile_charging" 3 "No_demand" ;
VAL_ 867 VCU_ChrgInsulFctOpenSts 0 "Thermal_insulation_off" 1 "Thermal_insulation_on" ;
VAL_ 867 VCU_ChrgEquipPwrNotEngh 0 "Initial_value" 1 "Charging_power_insufficient" 2 "Charging_power_sufficient" 3 "Reserved" ;
VAL_ 867 VCU_ACChrgStrtFailReason 0 "Initial_value" 1 "Charging_gun_not_connected_well,_please_replug_it" 2 "Charging_pile_unable_to_be_started,_please_sweep_the_card_or_change_the_pile" 3 "Veh_charg_sys_failed,_pull_gun_out,_restart_vehicle,_repeat_the_steps,_cont_agency" 4 "Charging_gun_not_locked" 5 "Reserved" 6 "Reserved" 7 "Reserved" ;
VAL_ 868 BCM_OTARdy_Fb 0 "Initial" 1 "Ready" 2 "Not_Ready" 3 "Invalid" ;
VAL_ 868 BCM_OTAInhbRdy 0 "Initial" 1 "Inhibit" 2 "Not_Inhibit" 3 "Invalid" ;
VAL_ 868 BCM_SBRMatStPass 0 "Seat_not_occupied" 1 "Seat_occupied" 2 "Fault" 3 "Invalid" ;
VAL_ 868 BCM_BucSwtSt2ndRowLeft 0 "Buckled" 1 "Not_buckled" 2 "Fault" 3 "Invalid" ;
VAL_ 868 BCM_BucSwtSt2ndRowMid 0 "Buckled" 1 "Not_buckled" 2 "Fault" 3 "Invalid" ;
VAL_ 868 BCM_BucSwtSt2ndRowRight 0 "Buckled" 1 "Not_buckled" 2 "Fault" 3 "Invalid" ;
VAL_ 868 BCM_BucSwtSt3rdRowLeft 0 "Buckled" 1 "Not_buckled" 2 "Fault" 3 "Invalid" ;
VAL_ 868 BCM_BucSwtSt3rdRowRight 0 "Buckled" 1 "Not_buckled" 2 "Fault" 3 "Invalid" ;
VAL_ 868 BCM_SBRMatSt2ndRowLeft 0 "Seat_not_occupied" 1 "Seat_occupied" 2 "Fault" 3 "Invalid" ;
VAL_ 868 BCM_SBRMatSt2ndRowMid 0 "Seat_not_occupied" 1 "Seat_occupied" 2 "Fault" 3 "Invalid" ;
VAL_ 868 BCM_SBRMatSt2ndRowRight 0 "Seat_not_occupied" 1 "Seat_occupied" 2 "Fault" 3 "Invalid" ;
VAL_ 868 BCM_SBRMat3rdRowLeft 0 "Seat_not_occupied" 1 "Seat_occupied" 2 "Fault" 3 "Invalid" ;
VAL_ 868 BCM_SBRMat3rdRowRight 0 "Seat_not_occupied" 1 "Seat_occupied" 2 "Fault" 3 "Invalid" ;
VAL_ 869 MCU_F_SecuStsChkFlt 0 "Normal" 1 "Abnormal" ;
VAL_ 869 MCU_F_HVActvDchaFlt 0 "Normal" 1 "Abnormal" ;
VAL_ 869 MCU_F_CtrlPanTChkCircFlt 0 "Normal" 1 "Abnormal" ;
VAL_ 869 MCU_F_ComLostFlt_VCU 0 "Normal" 1 "Abnormal" ;
VAL_ 869 MCU_F_E2EFlt 0 "Normal" 1 "Abnormal" ;
VAL_ 869 MCU_F_I2TFlt 0 "Normal" 1 "Abnormal" ;
VAL_ 869 MCU_F_OperModFlt 0 "Normal" 1 "Abnormal" ;
VAL_ 869 MCU_F_CooltOverTFlt 0 "Normal" 1 "Abnormal" ;
VAL_ 869 MCU_F_PhaCrtSampleCircFltU 0 "Normal" 1 "Abnormal" ;
VAL_ 869 MCU_F_PhaCrtSampleCircFltV 0 "Normal" 1 "Abnormal" ;
VAL_ 869 MCU_F_PhaCrtSampleCircFltW 0 "Normal" 1 "Abnormal" ;
VAL_ 869 MCU_F_ThreePhaCrtChkFlt 0 "Normal" 1 "Abnormal" ;
VAL_ 869 MCU_F_DCBusUnderVoltFlt 0 "Normal" 1 "Abnormal" ;
VAL_ 869 MCU_F_DCBusOverVoltFlt 0 "Normal" 1 "Abnormal" ;
VAL_ 869 MCU_F_PosnSnsrChkCircFlt 0 "Normal" 1 "Abnormal" ;
VAL_ 869 MCU_F_DCBusVoltSampleCircFlt 0 "Normal" 1 "Abnormal" ;
VAL_ 869 MCU_F_OverSpdFlt 0 "Normal" 1 "Abnormal" ;
VAL_ 869 MCU_F_IGBTOverTFltU 0 "Normal" 1 "Abnormal" ;
VAL_ 869 MCU_F_IGBTTChkCircFltU 0 "Normal" 1 "Abnormal" ;
VAL_ 869 MCU_F_IGBTTChkCircFltV 0 "Normal" 1 "Abnormal" ;
VAL_ 869 MCU_F_IGBTTChkCircFltW 0 "Normal" 1 "Abnormal" ;
VAL_ 869 MCU_F_OverTFlt 0 "Normal" 1 "Abnormal" ;
VAL_ 869 MCU_F_TChkCircFlt 0 "Normal" 1 "Abnormal" ;
VAL_ 869 MCU_F_CtrlPanOverTFlt 0 "Normal" 1 "Abnormal" ;
VAL_ 869 MCU_F_LVPwrSplyUnderVoltFlt 0 "Normal" 1 "Abnormal" ;
VAL_ 869 MCU_F_LVPwrSplyOverVoltFlt 0 "Normal" 1 "Abnormal" ;
VAL_ 869 MCU_F_FbTqStsChkFlt 0 "Normal" 1 "Abnormal" ;
VAL_ 869 MCU_F_PhaCrtSwOverCrtFltU 0 "Normal" 1 "Abnormal" ;
VAL_ 869 MCU_F_TqCmdOverLimFlt 0 "Normal" 1 "Abnormal" ;
VAL_ 869 MCU_F_PwrSplyModFlt 0 "Normal" 1 "Abnormal" ;
VAL_ 869 MCU_F_IGBTThreePhaTChkFlt 0 "Normal" 1 "Abnormal" ;
VAL_ 869 MCU_F_RotCalFlt 0 "Normal" 1 "Abnormal" ;
VAL_ 869 MCU_F_IntComFlt 0 "Normal" 1 "Abnormal" ;
VAL_ 869 MCU_F_IntTqChkFlt 0 "Normal" 1 "Abnormal" ;
VAL_ 869 MCU_F_IGBTDesatFltTop 0 "Normal" 1 "Abnormal" ;
VAL_ 869 MCU_F_IGBTDesatFltBot 0 "Normal" 1 "Abnormal" ;
VAL_ 869 MCU_F_PhaCrtSwOverCrtFltV 0 "Normal" 1 "Abnormal" ;
VAL_ 869 MCU_F_PhaCrtSwOverCrtFltW 0 "Normal" 1 "Abnormal" ;
VAL_ 869 MCU_F_IGBTOverTFltV 0 "Normal" 1 "Abnormal" ;
VAL_ 869 MCU_F_IGBTOverTFltW 0 "Normal" 1 "Abnormal" ;
